VERSION "HNNBNNNYNNNNNNNNNNNNNNNNNNNNNNNNNNNNNNNNNN/4/%%%/4/'%**4NNN///"

NS_ :

BS_:

BU_: BAP_Tester BCM1 Gateway Gateway_PAG Klima_MSB Lift_VA VAS_L VAS_R

BO_ 1624 Licht_vorne_01: 8 BCM1
 SG_ Licht_Vorne_01_CRC : 0|8@1+ (1,0) [0|255] ""  Gateway,Gateway_PAG
 SG_ Licht_Vorne_01_BZ : 8|4@1+ (1,0) [0|15] ""  Gateway,Gateway_PAG
 SG_ LV_Standlicht_Anzeige : 12|1@1+ (1.0,0.0) [0.0|1] ""  Gateway,Gateway_PAG
 SG_ LV_Abblendlicht_Anzeige : 13|1@1+ (1.0,0.0) [0.0|1] ""  Gateway,Gateway_PAG
 SG_ LV_Fernlicht_Anzeige : 14|1@1+ (1.0,0.0) [0.0|1] ""  Gateway,Gateway_PAG
 SG_ LV_Nebellicht_Anzeige : 15|1@1+ (1.0,0.0) [0.0|1] ""  Gateway,Gateway_PAG
 SG_ LV_Nebelschlusslicht_Anzeige : 16|1@1+ (1.0,0.0) [0.0|1] ""  Gateway,Gateway_PAG
 SG_ LV_Tagfahrlicht_Anzeige : 17|1@1+ (1.0,0.0) [0.0|1] ""  Gateway,Gateway_PAG
 SG_ LV_AFL_aktiv_Anzeige : 18|1@1+ (1.0,0.0) [0.0|1] ""  Gateway,Gateway_PAG
 SG_ LV_AFL_defekt : 19|1@1+ (1.0,0.0) [0.0|1] ""  Gateway,Gateway_PAG
 SG_ LV_Blinker_li_def : 20|1@1+ (1.0,0.0) [0.0|1] ""  Gateway,Gateway_PAG,VAS_L,VAS_R
 SG_ LV_Standlicht_li_def : 21|1@1+ (1.0,0.0) [0.0|1] ""  Gateway,Gateway_PAG
 SG_ LV_Abblendlicht_li_def : 22|1@1+ (1.0,0.0) [0.0|1] ""  Gateway,Gateway_PAG,VAS_L,VAS_R
 SG_ LV_Fernlicht_li_def : 23|1@1+ (1.0,0.0) [0.0|1] ""  Gateway,Gateway_PAG,VAS_L,VAS_R
 SG_ LV_Nebellicht_li_def : 24|1@1+ (1.0,0.0) [0.0|1] ""  Gateway,Gateway_PAG,VAS_L,VAS_R
 SG_ LV_Blk_li_Seite_def : 25|1@1+ (1.0,0.0) [0.0|1] ""  Gateway,Gateway_PAG,VAS_L,VAS_R
 SG_ LV_Tagfahrlicht_li_def : 26|1@1+ (1.0,0.0) [0.0|1] ""  Gateway,Gateway_PAG
 SG_ LV_FLA_aktiv_Anzeige : 27|1@1+ (1.0,0.0) [0.0|1] ""  Gateway,Gateway_PAG
 SG_ LV_FLA_defekt : 28|1@1+ (1.0,0.0) [0.0|1] ""  Gateway,Gateway_PAG
 SG_ LV_FLA_Sensor_blockiert : 29|1@1+ (1.0,0.0) [0.0|1] ""  Gateway,Gateway_PAG
 SG_ LV_Blinker_re_def : 30|1@1+ (1.0,0.0) [0.0|1] ""  Gateway,Gateway_PAG,VAS_L,VAS_R
 SG_ LV_Standlicht_re_def : 31|1@1+ (1.0,0.0) [0.0|1] ""  Gateway,Gateway_PAG
 SG_ LV_Abblendlicht_re_def : 32|1@1+ (1.0,0.0) [0.0|1] ""  Gateway,Gateway_PAG,VAS_L,VAS_R
 SG_ LV_Fernlicht_re_def : 33|1@1+ (1.0,0.0) [0.0|1] ""  Gateway,Gateway_PAG,VAS_L,VAS_R
 SG_ LV_Nebellicht_re_def : 34|1@1+ (1.0,0.0) [0.0|1] ""  Gateway,Gateway_PAG,VAS_L,VAS_R
 SG_ LV_Blk_re_Seite_def : 35|1@1+ (1.0,0.0) [0.0|1] ""  Gateway,Gateway_PAG,VAS_L,VAS_R
 SG_ LV_Tagfahrlicht_re_def : 36|1@1+ (1.0,0.0) [0.0|1] ""  Gateway,Gateway_PAG
 SG_ LV_Aussenlicht_def : 37|1@1+ (1.0,0.0) [0.0|1] ""  Gateway,Gateway_PAG,VAS_L,VAS_R
 SG_ LV_Abblendlicht_TFL_li_def : 38|1@1+ (1.0,0.0) [0.0|1] ""  Gateway,Gateway_PAG,VAS_L,VAS_R
 SG_ LV_Nebellicht_TFL_li_def : 39|1@1+ (1.0,0.0) [0.0|1] ""  Gateway,Gateway_PAG,VAS_L,VAS_R
 SG_ LV_Standlicht_TFL_li_def : 40|1@1+ (1.0,0.0) [0.0|1] ""  Gateway,Gateway_PAG
 SG_ LV_Abblend_Fernlicht_li_def : 41|1@1+ (1.0,0.0) [0.0|1] ""  Gateway,Gateway_PAG,VAS_L,VAS_R
 SG_ LV_Abblendlicht_TFL_re_def : 42|1@1+ (1.0,0.0) [0.0|1] ""  Gateway,Gateway_PAG,VAS_L,VAS_R
 SG_ LV_Nebellicht_TFL_re_def : 43|1@1+ (1.0,0.0) [0.0|1] ""  Gateway,Gateway_PAG,VAS_L,VAS_R
 SG_ LV_Standlicht_TFL_re_def : 44|1@1+ (1.0,0.0) [0.0|1] ""  Gateway,Gateway_PAG
 SG_ LV_Abblend_Fernlicht_re_def : 45|1@1+ (1.0,0.0) [0.0|1] ""  Gateway,Gateway_PAG,VAS_L,VAS_R
 SG_ LV_Abbiegelicht_li_def : 46|1@1+ (1.0,0.0) [0.0|1] ""  Gateway,Gateway_PAG
 SG_ LV_Abbiegelicht_re_def : 47|1@1+ (1.0,0.0) [0.0|1] ""  Gateway,Gateway_PAG
 SG_ BCM1_Linksverkehr : 48|1@1+ (1.0,0.0) [0.0|1] ""  Gateway,Gateway_PAG
 SG_ BCM1_Licht_Dunkelheit_aktiv : 49|1@1+ (1.0,0.0) [0.0|1] ""  Gateway,Gateway_PAG
 SG_ LV_LED_Scheinwerfer_li_def : 50|1@1+ (1.0,0.0) [0.0|1] ""  Gateway,Gateway_PAG
 SG_ LV_LED_Scheinwerfer_re_def : 51|1@1+ (1.0,0.0) [0.0|1] ""  Gateway,Gateway_PAG
 SG_ LV_Blinker_VL_aktiv : 52|1@1+ (1.0,0.0) [0.0|1] ""  Gateway,Gateway_PAG,VAS_L,VAS_R
 SG_ LV_Blinker_VR_aktiv : 53|1@1+ (1.0,0.0) [0.0|1] ""  Gateway,Gateway_PAG,VAS_L,VAS_R
 SG_ LV_MXB_Status_Anzeige : 54|2@1+ (1.0,0.0) [0.0|3] ""  Gateway,Gateway_PAG

BO_ 1321 Lift_01: 8 Lift_VA
 SG_ Lift_Charisma_FahrPr : 15|3@1+ (1.0,0.0) [0.0|7] ""  Gateway,Gateway_PAG
 SG_ Lift_Charisma_Status : 18|2@1+ (1.0,0.0) [0.0|3] ""  Gateway,Gateway_PAG
 SG_ Lift_Charisma_Umschaltung : 20|2@1+ (1.0,0.0) [0.0|3] ""  Gateway,Gateway_PAG
 SG_ Lift_Anforderung_EFP : 22|2@1+ (1.0,0.0) [0.0|3] ""  Gateway,Gateway_PAG
 SG_ Lift_ESP_Zuschaltung : 24|1@1+ (1.0,0.0) [0.0|1] ""  Gateway,Gateway_PAG
 SG_ Lift_Meldung_12 : 40|1@1+ (1.0,0.0) [0.0|1] ""  Gateway,Gateway_PAG
 SG_ Lift_Meldung_13 : 41|1@1+ (1.0,0.0) [0.0|1] ""  Gateway,Gateway_PAG
 SG_ Lift_Meldung_14 : 42|1@1+ (1.0,0.0) [0.0|1] ""  Gateway,Gateway_PAG
 SG_ Lift_LED : 43|2@1+ (1.0,0.0) [0.0|3] ""  Gateway,Gateway_PAG
 SG_ Lift_Position : 45|3@1+ (1.0,0.0) [0.0|7] ""  Gateway,Gateway_PAG
 SG_ Lift_Meldung_01 : 48|1@1+ (1.0,0.0) [0.0|1] ""  Gateway,Gateway_PAG
 SG_ Lift_Meldung_02 : 49|1@1+ (1.0,0.0) [0.0|1] ""  Gateway,Gateway_PAG
 SG_ Lift_Meldung_03 : 50|1@1+ (1.0,0.0) [0.0|1] ""  Gateway,Gateway_PAG
 SG_ Lift_Meldung_04 : 51|1@1+ (1.0,0.0) [0.0|1] ""  Gateway,Gateway_PAG
 SG_ Lift_Meldung_05 : 52|1@1+ (1.0,0.0) [0.0|1] ""  Gateway,Gateway_PAG
 SG_ Lift_Meldung_06 : 53|1@1+ (1.0,0.0) [0.0|1] ""  Gateway,Gateway_PAG
 SG_ Lift_Meldung_07 : 54|1@1+ (1.0,0.0) [0.0|1] ""  Gateway,Gateway_PAG
 SG_ Lift_Meldung_08 : 55|1@1+ (1.0,0.0) [0.0|1] ""  Gateway,Gateway_PAG
 SG_ Lift_Meldung_09 : 56|1@1+ (1.0,0.0) [0.0|1] ""  Gateway,Gateway_PAG
 SG_ Lift_Meldung_10 : 57|1@1+ (1.0,0.0) [0.0|1] ""  Gateway,Gateway_PAG
 SG_ Lift_Meldung_11 : 58|1@1+ (1.0,0.0) [0.0|1] ""  Gateway,Gateway_PAG
 SG_ Lift_SpannungsAnf : 59|2@1+ (1.0,0.0) [0.0|3] ""  Gateway,Gateway_PAG
 SG_ Lift_StartStopp_Info : 61|2@1+ (1.0,0.0) [0.0|3] ""  Gateway,Gateway_PAG

BO_ 822 LR_HZG_01: 2 Gateway
 SG_ LR_HZG_Temp_Sensor : 0|8@1+ (1,-50) [-50|104] "Unit_DegreCelsi"  Klima_MSB
 SG_ LR_HZG_Taster_on_off : 8|1@1+ (1.0,0.0) [0.0|1] ""  BCM1,Klima_MSB

BO_ 2527679652 LS1_01: 8 Gateway
 SG_ LS1_Reinigung_Anf : 63|1@1+ (1.0,0.0) [0.0|1] ""  BCM1

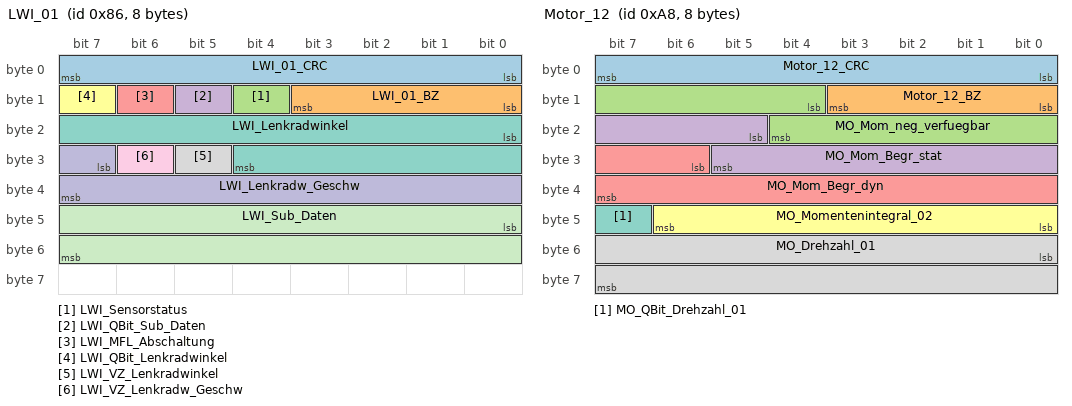
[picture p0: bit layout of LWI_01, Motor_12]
BO_ 134 LWI_01: 8 Gateway
 SG_ LWI_01_CRC : 0|8@1+ (1,0) [0|255] ""  Vector__XXX
 SG_ LWI_01_BZ : 8|4@1+ (1,0) [0|15] ""  Vector__XXX
 SG_ LWI_Sensorstatus : 12|1@1+ (1.0,0.0) [0.0|1] ""  Vector__XXX
 SG_ LWI_QBit_Sub_Daten : 13|1@1+ (1.0,0.0) [0.0|1] ""  Vector__XXX
 SG_ LWI_MFL_Abschaltung : 14|1@1+ (1.0,0.0) [0.0|1] ""  Vector__XXX
 SG_ LWI_QBit_Lenkradwinkel : 15|1@1+ (1.0,0.0) [0.0|1] ""  Vector__XXX
 SG_ LWI_Lenkradwinkel : 16|13@1+ (0.1,0) [0.0|800.0] "Unit_DegreOfArc"  Lift_VA
 SG_ LWI_VZ_Lenkradwinkel : 29|1@1+ (1.0,0.0) [0.0|1] ""  Lift_VA
 SG_ LWI_VZ_Lenkradw_Geschw : 30|1@1+ (1.0,0.0) [0.0|1] ""  Vector__XXX
 SG_ LWI_Lenkradw_Geschw : 31|9@1+ (5,0) [0|2500] "Unit_DegreOfArcPerSecon"  Vector__XXX
 SG_ LWI_Sub_Daten : 40|16@1+ (1,0) [0|65535] ""  Vector__XXX

BO_ 917 LWR_AFS_01: 8 BCM1
 SG_ AFS_Abbiegelicht_li_Anf : 0|1@1+ (1.0,0.0) [0.0|1] ""  Gateway,Gateway_PAG
 SG_ AFS_Abbiegelicht_re_Anf : 1|1@1+ (1.0,0.0) [0.0|1] ""  Gateway,Gateway_PAG
 SG_ AFS_Abbiegelicht_Dimm_Anf : 2|1@1+ (1.0,0.0) [0.0|1] ""  Gateway,Gateway_PAG
 SG_ AFS_Verfuegbarkeit_GLW : 3|1@1+ (1.0,0.0) [0.0|1] ""  Gateway,Gateway_PAG
 SG_ AFS_Status_adaptive_LV : 4|1@1+ (1.0,0.0) [0.0|1] ""  Gateway,Gateway_PAG
 SG_ AFS_Fernlicht_li_defekt : 5|1@1+ (1.0,0.0) [0.0|1] ""  Gateway,Gateway_PAG
 SG_ AFS_Fernlicht_re_defekt : 6|1@1+ (1.0,0.0) [0.0|1] ""  Gateway,Gateway_PAG
 SG_ AFS_Fernlicht_Status : 7|1@1+ (1.0,0.0) [0.0|1] ""  Gateway,Gateway_PAG
 SG_ LWR_AFS_01_BZ : 8|4@1+ (1,0) [0|15] ""  Gateway,Gateway_PAG
 SG_ AFS_Lampe : 12|1@1+ (1.0,0.0) [0.0|1] ""  Gateway,Gateway_PAG
 SG_ LWR_Lampe : 13|1@1+ (1.0,0.0) [0.0|1] ""  Gateway,Gateway_PAG
 SG_ AFS_Fehlertext : 14|1@1+ (1.0,0.0) [0.0|1] ""  Gateway,Gateway_PAG
 SG_ AFS_LED_Blinkmode : 15|1@1+ (1.0,0.0) [0.0|1] ""  Gateway,Gateway_PAG
 SG_ LWR_Touristenmodus_aktiv : 16|1@1+ (1.0,0.0) [0.0|1] ""  Gateway,Gateway_PAG
 SG_ AFS_Charisma_FahrPr : 17|4@1+ (1.0,0.0) [0.0|15] ""  Gateway,Gateway_PAG
 SG_ AFS_Charisma_Status : 21|2@1+ (1.0,0.0) [0.0|3] ""  Gateway,Gateway_PAG
 SG_ LWR_Sicherheitsposition_re : 23|1@1+ (1.0,0.0) [0.0|1] ""  Gateway,Gateway_PAG
 SG_ AFS_Allwetterlicht : 24|1@1+ (1.0,0.0) [0.0|1] ""  Gateway,Gateway_PAG
 SG_ LWR_Touristenmodus_verbaut : 25|1@1+ (1.0,0.0) [0.0|1] ""  Gateway,Gateway_PAG
 SG_ AFS_adaptive_LV_verbaut : 26|1@1+ (1.0,0.0) [0.0|1] ""  Gateway,Gateway_PAG
 SG_ LWR_Reisemodus_Texte : 27|2@1+ (1.0,0.0) [0.0|3] ""  Gateway,Gateway_PAG
 SG_ GLW_Sensor_blockiert : 29|1@1+ (1.0,0.0) [0.0|1] ""  Gateway,Gateway_PAG
 SG_ AFS_Charisma_Umschaltung : 30|2@1+ (1.0,0.0) [0.0|3] ""  Gateway,Gateway_PAG
 SG_ LWR_Pos_Schrittmotor : 32|8@1+ (0.4,0) [0.0|100.0] "Unit_PerCent"  Gateway,Gateway_PAG
 SG_ LWR_Hoehenwert_VL : 40|8@1+ (1,-127) [-127|126] ""  Gateway,Gateway_PAG
 SG_ LWR_Hoehenwert_HL : 48|8@1+ (1,-127) [-127|126] ""  Gateway,Gateway_PAG
 SG_ AFS_Ersatzlicht_Links : 56|1@1+ (1.0,0.0) [0.0|1] ""  Gateway,Gateway_PAG
 SG_ AFS_Ersatzlicht_Rechts : 57|1@1+ (1.0,0.0) [0.0|1] ""  Gateway,Gateway_PAG
 SG_ LWR_AFS_Grundeinstellung : 58|1@1+ (1.0,0.0) [0.0|1] ""  Gateway,Gateway_PAG
 SG_ LWR_AFS_Parametrisierung : 59|1@1+ (1.0,0.0) [0.0|1] ""  Gateway,Gateway_PAG
 SG_ LWR_Initialisierungslauf : 60|1@1+ (1.0,0.0) [0.0|1] ""  Gateway,Gateway_PAG
 SG_ LWR_Sicherheitsposition_li : 61|1@1+ (1.0,0.0) [0.0|1] ""  Gateway,Gateway_PAG
 SG_ LWR_Modus : 62|1@1+ (1.0,0.0) [0.0|1] ""  Gateway,Gateway_PAG

BO_ 1153 MainUnit_01: 8 Gateway
 SG_ ZR_LoGeWa_Event_Kombiwarnung : 0|4@1+ (1.0,0.0) [0.0|15] ""  Vector__XXX
 SG_ Nav_FoD_Status : 4|3@1+ (1.0,0.0) [0.0|7] ""  Vector__XXX
 SG_ MIB_Tongenerator_PH_verfuegbar : 9|3@1+ (1.0,0.0) [0.0|7] ""  BCM1
 SG_ MMI_Counter_Bedienevent : 12|4@1+ (1.0,0.0) [0.0|15] ""  Vector__XXX
 SG_ DSSS_Warning : 16|5@1+ (1.0,0.0) [0.0|31] ""  Vector__XXX
 SG_ ZR_Kindersicherung_RSE : 21|1@1+ (1.0,0.0) [0.0|1] ""  Vector__XXX
 SG_ ZR_RSE_aktivieren : 22|1@1+ (1.0,0.0) [0.0|1] ""  Vector__XXX
 SG_ MMI_SDS_aktiv : 23|1@1+ (1.0,0.0) [0.0|1] ""  Vector__XXX
 SG_ MU_SecondDisplay : 24|3@1+ (1.0,0.0) [0.0|7] ""  Vector__XXX
 SG_ MMI_Telefon_aktiv : 27|1@1+ (1.0,0.0) [0.0|1] ""  Vector__XXX
 SG_ MMI_Gurt_Mic_ref : 28|1@1+ (1.0,0.0) [0.0|1] ""  Vector__XXX
 SG_ ZR_Sta_Inszenierung : 29|2@1+ (1.0,0.0) [0.0|3] ""  BCM1
 SG_ MMI_Gauges_active : 31|1@1+ (1.0,0.0) [0.0|1] ""  Vector__XXX
 SG_ MU_Update_Time : 32|8@1+ (0.1,0) [0.0|25.5] "Unit_Hours"  Vector__XXX
 SG_ ZR_MXB_Manoever_Ansage : 42|2@1+ (1.0,0.0) [0.0|3] ""  Vector__XXX
 SG_ ZR_LAPP_Sondermodus_Status : 44|2@1+ (1.0,0.0) [0.0|3] ""  Vector__XXX
 SG_ MMI_StartStopp_Info : 46|2@1+ (1.0,0.0) [0.0|3] ""  Vector__XXX
 SG_ ZR_Parken_Sondermodus : 48|4@1+ (1.0,0.0) [0.0|15] ""  Vector__XXX
 SG_ ZR_Rundenbewertung : 52|4@1+ (1.0,0.0) [0.0|15] ""  Vector__XXX
 SG_ ZR_Rundenfortschritt : 56|8@1+ (0.5,0) [0.0|100.0] "Unit_PerCent"  Vector__XXX

BO_ 1639 Mem_BFS_01: 8 Gateway
 SG_ BFS_Fond_Bed_Ack : 12|1@1+ (1.0,0.0) [0.0|1] ""  Vector__XXX
 SG_ BFS_Lehne_nicht_verriegelt : 13|1@1+ (1.0,0.0) [0.0|1] ""  Vector__XXX
 SG_ BFS_Klapptisch_offen : 14|1@1+ (1.0,0.0) [0.0|1] ""  Vector__XXX
 SG_ BFS_Gurtbringer_Sperre : 15|1@1+ (1.0,0.0) [0.0|1] ""  Vector__XXX
 SG_ BFS_Sitzsym_Fahrt_aktiv : 16|1@1+ (1.0,0.0) [0.0|1] ""  Vector__XXX
 SG_ BFS_Sitzfahrt_aktiv : 17|1@1+ (1.0,0.0) [0.0|1] ""  Vector__XXX
 SG_ BFS_SLV_aktiv : 18|1@1+ (1.0,0.0) [0.0|1] ""  Vector__XXX
 SG_ BFS_SHV_aktiv : 19|1@1+ (1.0,0.0) [0.0|1] ""  Vector__XXX
 SG_ BFS_LNV_aktiv : 20|1@1+ (1.0,0.0) [0.0|1] ""  Vector__XXX
 SG_ BFS_SNV_aktiv : 21|1@1+ (1.0,0.0) [0.0|1] ""  Vector__XXX
 SG_ BFS_KSV_aktiv : 22|1@1+ (1.0,0.0) [0.0|1] ""  Vector__XXX
 SG_ BFS_LKV_aktiv : 23|1@1+ (1.0,0.0) [0.0|1] ""  Vector__XXX
 SG_ BFS_STV_aktiv : 24|1@1+ (1.0,0.0) [0.0|1] ""  Vector__XXX
 SG_ BFS_LHV_aktiv : 25|1@1+ (1.0,0.0) [0.0|1] ""  Vector__XXX
 SG_ BFS_LWV_aktiv : 26|1@1+ (1.0,0.0) [0.0|1] ""  Vector__XXX
 SG_ BFS_GHV_aktiv : 27|1@1+ (1.0,0.0) [0.0|1] ""  Vector__XXX
 SG_ BFS_KSS_Fahrt_aktiv : 28|1@1+ (1.0,0.0) [0.0|1] ""  Vector__XXX
 SG_ BFS_MMB_lokal_Stop : 29|1@1+ (1.0,0.0) [0.0|1] ""  Vector__XXX
 SG_ BFS_Ruhestellung_Status : 30|1@1+ (1.0,0.0) [0.0|1] ""  Vector__XXX
 SG_ BFS_Seat_Locked : 31|1@1+ (1.0,0.0) [0.0|1] ""  Vector__XXX
 SG_ BFS_MMB_storage : 32|4@1+ (1.0,0.0) [0.0|15] ""  BCM1
 SG_ BFS_MMB_tipp : 36|1@1+ (1.0,0.0) [0.0|1] ""  BCM1
 SG_ BFS_MMB_tast : 37|1@1+ (1.0,0.0) [0.0|1] ""  BCM1
 SG_ BFS_MMB_store_LED_on : 38|1@1+ (1.0,0.0) [0.0|1] ""  Vector__XXX
 SG_ BFS_MMB_storage_beep : 39|1@1+ (1.0,0.0) [0.0|1] ""  Vector__XXX
 SG_ BFS_MMB_store : 40|1@1+ (1.0,0.0) [0.0|1] ""  Vector__XXX
 SG_ BFS_MMB_glob_stop : 41|1@1+ (1.0,0.0) [0.0|1] ""  BCM1
 SG_ BFS_FSV_ausgeklappt : 42|1@1+ (1.0,0.0) [0.0|1] ""  BCM1
 SG_ BFS_NFA_einfahren : 43|1@1+ (1.0,0.0) [0.0|1] ""  Vector__XXX
 SG_ BFS_Kollisionsbereich_Windschott : 44|1@1+ (1.0,0.0) [0.0|1] ""  Vector__XXX
 SG_ BFS_Kollisionsgefahr_Windschott : 45|1@1+ (1.0,0.0) [0.0|1] ""  Vector__XXX

BO_ 1178 Mem_FS_01: 8 Gateway
 SG_ FS_Fond_Bed_enable : 12|1@1+ (1.0,0.0) [0.0|1] ""  Vector__XXX
 SG_ FS_Lehne_nicht_verriegelt : 13|1@1+ (1.0,0.0) [0.0|1] ""  Vector__XXX
 SG_ FS_Spezialposition_anfahren : 14|1@1+ (1.0,0.0) [0.0|1] ""  Vector__XXX
 SG_ FS_Gurtbringer_Sperre : 15|1@1+ (1.0,0.0) [0.0|1] ""  Vector__XXX
 SG_ FS_BFS_Sitzsym_Anfahrt : 16|1@1+ (1.0,0.0) [0.0|1] ""  Vector__XXX
 SG_ FS_Sitzfahrt_aktiv : 17|1@1+ (1.0,0.0) [0.0|1] ""  BCM1
 SG_ FS_SLV_aktiv : 18|1@1+ (1.0,0.0) [0.0|1] ""  Vector__XXX
 SG_ FS_SHV_aktiv : 19|1@1+ (1.0,0.0) [0.0|1] ""  Vector__XXX
 SG_ FS_LNV_aktiv : 20|1@1+ (1.0,0.0) [0.0|1] ""  Vector__XXX
 SG_ FS_SNV_aktiv : 21|1@1+ (1.0,0.0) [0.0|1] ""  Vector__XXX
 SG_ FS_KSV_aktiv : 22|1@1+ (1.0,0.0) [0.0|1] ""  Vector__XXX
 SG_ FS_LKV_aktiv : 23|1@1+ (1.0,0.0) [0.0|1] ""  Vector__XXX
 SG_ FS_STV_aktiv : 24|1@1+ (1.0,0.0) [0.0|1] ""  Vector__XXX
 SG_ FS_LHV_aktiv : 25|1@1+ (1.0,0.0) [0.0|1] ""  Vector__XXX
 SG_ FS_LWV_aktiv : 26|1@1+ (1.0,0.0) [0.0|1] ""  Vector__XXX
 SG_ FS_GHV_aktiv : 27|1@1+ (1.0,0.0) [0.0|1] ""  Vector__XXX
 SG_ FS_BFS_KSS_Anfahrt : 28|1@1+ (1.0,0.0) [0.0|1] ""  Vector__XXX
 SG_ FS_MMB_lokal_Stop : 29|1@1+ (1.0,0.0) [0.0|1] ""  Vector__XXX
 SG_ FS_NFA_einfahren : 30|1@1+ (1.0,0.0) [0.0|1] ""  Vector__XXX
 SG_ FS_Kollisionsbereich_Windschott : 31|1@1+ (1.0,0.0) [0.0|1] ""  Vector__XXX
 SG_ FS_MMB_storage : 32|4@1+ (1.0,0.0) [0.0|15] ""  BCM1,Klima_MSB
 SG_ FS_MMB_tipp : 36|1@1+ (1.0,0.0) [0.0|1] ""  BCM1,Klima_MSB
 SG_ FS_MMB_tast : 37|1@1+ (1.0,0.0) [0.0|1] ""  BCM1,Klima_MSB
 SG_ FS_MMB_store_LED_on : 38|1@1+ (1.0,0.0) [0.0|1] ""  Vector__XXX
 SG_ FS_MMB_storage_beep : 39|1@1+ (1.0,0.0) [0.0|1] ""  Vector__XXX
 SG_ FS_MMB_store : 40|1@1+ (1.0,0.0) [0.0|1] ""  BCM1,Klima_MSB
 SG_ FS_MMB_glob_stop : 41|1@1+ (1.0,0.0) [0.0|1] ""  BCM1
 SG_ FS_EE_Fond_FS_enable : 42|1@1+ (1.0,0.0) [0.0|1] ""  Vector__XXX
 SG_ FS_EE_Fond_BFS_enable : 43|1@1+ (1.0,0.0) [0.0|1] ""  Vector__XXX
 SG_ FS_BFS_Fond_Verst_enable : 44|1@1+ (1.0,0.0) [0.0|1] ""  Vector__XXX
 SG_ FS_EE_BFS_enable : 45|1@1+ (1.0,0.0) [0.0|1] ""  Vector__XXX
 SG_ FS_Kollisionsgefahr_Windschott : 46|1@1+ (1.0,0.0) [0.0|1] ""  Vector__XXX

BO_ 1171 MFG_01: 8 Gateway
 SG_ MFG_01_CRC : 0|8@1+ (1,0) [0|255] ""  BCM1
 SG_ MFG_01_BZ : 8|4@1+ (1,0) [0|15] ""  BCM1
 SG_ MF_ZV_Lock : 12|1@1+ (1.0,0.0) [0.0|1] ""  Vector__XXX
 SG_ MF_Motorweiterlauf : 13|1@1+ (1.0,0.0) [0.0|1] ""  Vector__XXX
 SG_ MF_Heckrollo : 14|1@1+ (1.0,0.0) [0.0|1] ""  Vector__XXX
 SG_ MF_Anlassersperre : 15|1@1+ (1.0,0.0) [0.0|1] ""  Vector__XXX
 SG_ MF_Variante : 16|3@1+ (1.0,0.0) [0.0|7] ""  BCM1
 SG_ MF_Sperre_Rollo : 19|1@1+ (1.0,0.0) [0.0|1] ""  Vector__XXX
 SG_ MF_Laderelais : 20|1@1+ (1.0,0.0) [0.0|1] ""  Vector__XXX
 SG_ MF_StartStopp_Info : 21|2@1+ (1.0,0.0) [0.0|3] ""  Vector__XXX
 SG_ MF_Fernbed_ein : 23|1@1+ (1.0,0.0) [0.0|1] ""  BCM1
 SG_ MF_Standlicht : 24|1@1+ (1.0,0.0) [0.0|1] ""  BCM1
 SG_ MF_Fahrlicht : 25|1@1+ (1.0,0.0) [0.0|1] ""  BCM1
 SG_ MF_interm_Fernlicht : 26|1@1+ (1.0,0.0) [0.0|1] ""  BCM1
 SG_ MF_Warnblinker : 27|1@1+ (1.0,0.0) [0.0|1] ""  BCM1
 SG_ MF_Fussraumbel : 28|1@1+ (1.0,0.0) [0.0|1] ""  BCM1
 SG_ MF_Innenraumbel : 29|1@1+ (1.0,0.0) [0.0|1] ""  BCM1
 SG_ MF_Innenraumbel_Unterdrueck : 30|1@1+ (1.0,0.0) [0.0|1] ""  BCM1
 SG_ MF_Notstart : 31|1@1+ (1.0,0.0) [0.0|1] ""  Vector__XXX
 SG_ MF_Blk_li : 32|1@1+ (1.0,0.0) [0.0|1] ""  Vector__XXX
 SG_ MF_Blk_re : 33|1@1+ (1.0,0.0) [0.0|1] ""  Vector__XXX
 SG_ MF_Lichthupe : 34|1@1+ (1.0,0.0) [0.0|1] ""  BCM1
 SG_ MF_Fernlicht : 35|1@1+ (1.0,0.0) [0.0|1] ""  BCM1
 SG_ MF_HFS_verriegeln : 36|1@1+ (1.0,0.0) [0.0|1] ""  Vector__XXX
 SG_ MF_HFS_entriegeln : 37|1@1+ (1.0,0.0) [0.0|1] ""  Vector__XXX
 SG_ MF_HBFS_verriegeln : 38|1@1+ (1.0,0.0) [0.0|1] ""  Vector__XXX
 SG_ MF_HBFS_entriegeln : 39|1@1+ (1.0,0.0) [0.0|1] ""  Vector__XXX
 SG_ MF_Tippwischen : 40|1@1+ (1.0,0.0) [0.0|1] ""  BCM1
 SG_ MF_Frontintervall : 41|1@1+ (1.0,0.0) [0.0|1] ""  BCM1
 SG_ MF_Wischerstufe_1 : 42|1@1+ (1.0,0.0) [0.0|1] ""  BCM1
 SG_ MF_Wischerstufe_2 : 43|1@1+ (1.0,0.0) [0.0|1] ""  BCM1
 SG_ MF_Frontwaschen : 44|1@1+ (1.0,0.0) [0.0|1] ""  BCM1
 SG_ MF_nachtr_Stopp_Anf : 45|1@1+ (1.0,0.0) [0.0|1] ""  Vector__XXX
 SG_ MF_Heckintervall : 46|1@1+ (1.0,0.0) [0.0|1] ""  BCM1
 SG_ MF_Heckwaschen : 47|1@1+ (1.0,0.0) [0.0|1] ""  BCM1
 SG_ MF_Summer : 48|1@1+ (1.0,0.0) [0.0|1] ""  Vector__XXX
 SG_ MF_Alarm_Blinkertakt : 49|1@1+ (1.0,0.0) [0.0|1] ""  Vector__XXX
 SG_ MF_Alarm_Blinker : 50|1@1+ (1.0,0.0) [0.0|1] ""  Vector__XXX
 SG_ MF_TFL_Abschaltung : 51|1@1+ (1.0,0.0) [0.0|1] ""  BCM1
 SG_ MF_interm_Takt : 52|1@1+ (1.0,0.0) [0.0|1] ""  Vector__XXX
 SG_ MF_Tuerentriegelung_hinten : 53|1@1+ (1.0,0.0) [0.0|1] ""  Vector__XXX
 SG_ MF_interm_Fahrlicht : 54|1@1+ (1.0,0.0) [0.0|1] ""  Vector__XXX
 SG_ MF_Signalhorn : 55|1@1+ (1.0,0.0) [0.0|1] ""  BCM1
 SG_ MF_FH_FT_hoch : 56|1@1+ (1.0,0.0) [0.0|1] ""  Vector__XXX
 SG_ MF_FH_FT_tief : 57|1@1+ (1.0,0.0) [0.0|1] ""  Vector__XXX
 SG_ MF_FH_BT_hoch : 58|1@1+ (1.0,0.0) [0.0|1] ""  Vector__XXX
 SG_ MF_FH_BT_tief : 59|1@1+ (1.0,0.0) [0.0|1] ""  Vector__XXX
 SG_ MF_FT_verriegeln : 60|1@1+ (1.0,0.0) [0.0|1] ""  Vector__XXX
 SG_ MF_FT_entriegeln : 61|1@1+ (1.0,0.0) [0.0|1] ""  Vector__XXX
 SG_ MF_BT_verriegeln : 62|1@1+ (1.0,0.0) [0.0|1] ""  Vector__XXX
 SG_ MF_BT_entriegeln : 63|1@1+ (1.0,0.0) [0.0|1] ""  Vector__XXX

BO_ 817 MFL_01: 8 Gateway
 SG_ MFL_Zaehler : 0|4@1+ (1,0) [0|15] ""  Vector__XXX
 SG_ MFL_Toggle : 4|1@1+ (1,0) [0|1] ""  Vector__XXX
 SG_ MFL_Lokalaktiv : 5|1@1+ (1.0,0.0) [0.0|1] ""  Vector__XXX
 SG_ MFL_M_Taste : 6|1@1+ (1.0,0.0) [0.0|1] ""  Vector__XXX
 SG_ MFL_Paddle_Verbau : 7|1@1+ (1.0,0.0) [0.0|1] ""  Vector__XXX
 SG_ MFL_Tastencode_1 : 8|8@1+ (1.0,0.0) [0.0|255] ""  BCM1
 SG_ MFL_Tastencode_2 : 16|8@1+ (1.0,0.0) [0.0|255] ""  BCM1
 SG_ MFL_Eventcode_1 : 24|4@1+ (1.0,0.0) [0.0|15] ""  Vector__XXX
 SG_ MFL_Eventcode_2 : 28|4@1+ (1.0,0.0) [0.0|15] ""  Vector__XXX
 SG_ MFL_Marke : 32|4@1+ (1.0,0.0) [0.0|15] ""  Vector__XXX
 SG_ MFL_Variante : 36|4@1+ (1,0) [0|15] ""  Vector__XXX
 SG_ MFL_Dummy_0_Signal_1 : 40|8@1+ (1.0,0.0) [0.0|255] ""  Vector__XXX
 SG_ MFL_Tip_Down : 48|1@1+ (1.0,0.0) [0.0|1] ""  Vector__XXX
 SG_ MFL_Tip_Up : 49|1@1+ (1.0,0.0) [0.0|1] ""  Vector__XXX
 SG_ MFL_SatModul_links_Err : 50|1@1+ (1.0,0.0) [0.0|1] ""  Vector__XXX
 SG_ MFL_SatModul_rechts_Err : 51|1@1+ (1.0,0.0) [0.0|1] ""  Vector__XXX
 SG_ MFL_Dummy_0_Signal_2 : 52|1@1+ (1.0,0.0) [0.0|1] ""  Vector__XXX
 SG_ MFL_Dummy_0_Signal_3 : 53|1@1+ (1.0,0.0) [0.0|1] ""  Vector__XXX
 SG_ MFL_LR_HZG_Status : 54|1@1+ (1.0,0.0) [0.0|1] ""  Vector__XXX
 SG_ MFL_LR_HZG_Err : 55|1@1+ (1.0,0.0) [0.0|1] ""  Vector__XXX
 SG_ MFL_Signalhorn : 56|1@1+ (1.0,0.0) [0.0|1] ""  BCM1
 SG_ MFL_Signalhorn_Err : 57|1@1+ (1.0,0.0) [0.0|1] ""  Vector__XXX
 SG_ MFL_Tip_links_Err : 58|1@1+ (1.0,0.0) [0.0|1] ""  Vector__XXX
 SG_ MFL_Tip_rechts_Err : 59|1@1+ (1.0,0.0) [0.0|1] ""  Vector__XXX
 SG_ MFL_Taste_links_Err : 60|1@1+ (1.0,0.0) [0.0|1] ""  Vector__XXX
 SG_ MFL_Taste_rechts_Err : 61|1@1+ (1.0,0.0) [0.0|1] ""  Vector__XXX
 SG_ MFL_ECU_Err : 62|1@1+ (1.0,0.0) [0.0|1] ""  Vector__XXX
 SG_ MFL_Response_Err : 63|1@1+ (1.0,0.0) [0.0|1] ""  Vector__XXX

BO_ 1600 Motor_07: 8 Gateway
 SG_ MO_QBit_Ansaugluft_Temp : 0|1@1+ (1.0,0.0) [0.0|1] ""  Vector__XXX
 SG_ MO_QBit_Oel_Temp : 1|1@1+ (1.0,0.0) [0.0|1] ""  Vector__XXX
 SG_ MO_QBit_Kuehlmittel_Temp : 2|1@1+ (1.0,0.0) [0.0|1] ""  Vector__XXX
 SG_ MO_KL15_Abschaltempfehlung : 3|1@1+ (1.0,0.0) [0.0|1] ""  Vector__XXX
 SG_ MO_HYB_Fehler_HV_Netz : 4|1@1+ (1.0,0.0) [0.0|1] ""  Vector__XXX
 SG_ MO_aktives_Getriebeheizen : 5|1@1+ (1.0,0.0) [0.0|1] ""  Vector__XXX
 SG_ MO_Absperrventil_oeffnen : 6|2@1+ (1.0,0.0) [0.0|3] ""  BCM1,Klima_MSB
 SG_ MO_Ansaugluft_Temp : 8|8@1+ (0.75,-48) [-48.00|141.75] "Unit_DegreCelsi"  Vector__XXX
 SG_ MO_Oel_Temp : 16|8@1+ (1,-60) [-60|192] "Unit_DegreCelsi"  BCM1,Klima_MSB
 SG_ MO_Kuehlmittel_Temp : 24|8@1+ (0.75,-48) [-48.00|141.75] "Unit_DegreCelsi"  BCM1,Klima_MSB
 SG_ MO_Hoeheninfo : 32|8@1+ (0.00781,0) [0.00000|1.98374] ""  BCM1,Klima_MSB
 SG_ MO_Kennfeldk : 40|1@1+ (1.0,0.0) [0.0|1] ""  BCM1,Klima_MSB
 SG_ MO_Versionsinfo_02 : 41|5@1+ (1.0,0.0) [0.0|31] ""  Vector__XXX
 SG_ MO_QBit_Hoeheninfo : 46|1@1+ (1.0,0.0) [0.0|1] ""  Vector__XXX
 SG_ MO_Getriebe_kuehlen : 47|1@1+ (1.0,0.0) [0.0|1] ""  Vector__XXX
 SG_ MO_Mom_Traegheit_02 : 48|5@1+ (0.01,0) [0.00|0.31] "Unit_KiloGramMeterSquar"  Vector__XXX
 SG_ MO_Heizungspumpenansteuerung : 53|4@1+ (10,0) [0|100] "Unit_PerCent"  BCM1,Klima_MSB
 SG_ MO_SpannungsAnf : 57|1@1+ (1.0,0.0) [0.0|1] ""  Vector__XXX
 SG_ MO_Nachlaufzeit_Heizungspumpe : 58|6@1+ (15,0) [0|945] "Unit_Secon"  BCM1

BO_ 1607 Motor_09: 8 Gateway
 SG_ MO_ITM_Kuehlmittel_Temp : 0|8@1+ (0.75,-48) [-45.75|143.25] "Unit_DegreCelsi"  BCM1,Klima_MSB
 SG_ MO_E85_Sensor : 8|4@1+ (10,0) [0|100] "Unit_PerCent"  Vector__XXX
 SG_ SCR_Anz_Motorstarts : 12|4@1+ (1.0,0.0) [0.0|15] ""  Vector__XXX
 SG_ SCR_Reichweite : 16|15@1+ (1,0) [0|32766] "Unit_KiloMeter"  Vector__XXX
 SG_ MO_Ethanol_Spuelhinweis : 31|1@1+ (1.0,0.0) [0.0|1] ""  Vector__XXX
 SG_ SCR_Warnstufe_1 : 32|1@1+ (1.0,0.0) [0.0|1] ""  Vector__XXX
 SG_ SCR_Warnstufe_2 : 33|1@1+ (1.0,0.0) [0.0|1] ""  Vector__XXX
 SG_ SCR_Text : 34|3@1+ (1.0,0.0) [0.0|7] ""  Vector__XXX
 SG_ SCR_Akustik : 37|2@1+ (1.0,0.0) [0.0|3] ""  Vector__XXX
 SG_ SCR_verbaut : 39|1@1+ (1.0,0.0) [0.0|1] ""  Vector__XXX
 SG_ MO_Kraftstofffilter_Wasser : 40|1@1+ (1.0,0.0) [0.0|1] ""  Vector__XXX
 SG_ SCR_Systemfehler : 41|1@1+ (1.0,0.0) [0.0|1] ""  Vector__XXX
 SG_ SCR_Inducement_Strategie : 42|2@1+ (1.0,0.0) [0.0|3] ""  Vector__XXX
 SG_ MO_CO2_Faktor : 44|12@1+ (1,0) [1|4094] "Unit_GramPerLiter"  Vector__XXX
 SG_ MO_MKB_MUX M  : 56|2@1+ (1.0,0.0) [0.0|3] ""  Vector__XXX
 SG_ MO_MKB_01 m0  : 59|5@1+ (1.0,0.0) [0.0|31] ""  Vector__XXX
 SG_ MO_MKB_02 m1  : 59|5@1+ (1.0,0.0) [0.0|31] ""  Vector__XXX
 SG_ MO_MKB_03 m2  : 59|5@1+ (1.0,0.0) [0.0|31] ""  Vector__XXX
 SG_ MO_MKB_04 m3  : 59|5@1+ (1.0,0.0) [0.0|31] ""  Vector__XXX

BO_ 168 Motor_12: 8 Gateway
 SG_ Motor_12_CRC : 0|8@1+ (1,0) [0|255] ""  Vector__XXX
 SG_ Motor_12_BZ : 8|4@1+ (1,0) [0|15] ""  Vector__XXX
 SG_ MO_Mom_neg_verfuegbar : 12|9@1+ (1,-509) [-509|0] ""  Vector__XXX
 SG_ MO_Mom_Begr_stat : 21|9@1+ (1,0) [0|509] ""  Vector__XXX
 SG_ MO_Mom_Begr_dyn : 30|10@1+ (1,-509) [-509|509] ""  Vector__XXX
 SG_ MO_Momentenintegral_02 : 40|7@1+ (1,0) [0|100] "Unit_PerCent"  Vector__XXX
 SG_ MO_QBit_Drehzahl_01 : 47|1@1+ (1.0,0.0) [0.0|1] ""  BCM1,Klima_MSB
 SG_ MO_Drehzahl_01 : 48|16@1+ (0.25,0) [0.00|16383.00] "Unit_MinutInver"  BCM1,Klima_MSB,Lift_VA

BO_ 958 Motor_14: 8 Gateway
 SG_ Motor_14_CRC : 0|8@1+ (1,0) [0|255] ""  Vector__XXX
 SG_ Motor_14_BZ : 8|4@1+ (1,0) [0|15] ""  Vector__XXX
 SG_ MO_StartStopp_Status : 12|2@1+ (1.0,0.0) [0.0|3] ""  BCM1,Klima_MSB,Lift_VA
 SG_ MO_StartStopp_Wiederstart : 14|1@1+ (1.0,0.0) [0.0|1] ""  BCM1,Klima_MSB,Lift_VA
 SG_ MO_StartStopp_Motorstopp : 15|1@1+ (1.0,0.0) [0.0|1] ""  BCM1,Klima_MSB,Lift_VA
 SG_ MO_Freig_Reku : 16|2@1+ (1.0,0.0) [0.0|3] ""  Vector__XXX
 SG_ MO_Kl_75 : 18|1@1+ (1.0,0.0) [0.0|1] ""  BCM1,Klima_MSB,VAS_L,VAS_R
 SG_ MO_Kl_50 : 19|1@1+ (1.0,0.0) [0.0|1] ""  Lift_VA
 SG_ MO_Gangposition : 20|4@1+ (1.0,0.0) [0.0|15] ""  BCM1,Klima_MSB,VAS_L,VAS_R
 SG_ MO_StartStopp_Fahrerwunsch : 24|2@1+ (1.0,0.0) [0.0|3] ""  BCM1,Klima_MSB,Lift_VA
 SG_ MO_HYB_Fahrbereitschaft : 26|1@1+ (1.0,0.0) [0.0|1] ""  BCM1,Klima_MSB
 SG_ MO_Ext_E_Fahrt_aktiv : 27|1@1+ (1.0,0.0) [0.0|1] ""  BCM1,Klima_MSB
 SG_ MO_Fahrer_bremst : 28|1@1+ (1.0,0.0) [0.0|1] ""  BCM1
 SG_ MO_QBit_Fahrer_bremst : 29|1@1+ (1.0,0.0) [0.0|1] ""  BCM1
 SG_ MO_BLS : 30|1@1+ (1.0,0.0) [0.0|1] ""  BCM1
 SG_ MO_Konsistenz_Bremsped : 31|1@1+ (1.0,0.0) [0.0|1] ""  Vector__XXX
 SG_ MO_KomFehler_ESP : 32|1@1+ (1.0,0.0) [0.0|1] ""  Vector__XXX
 SG_ MO_Klima_Eingr : 33|2@1+ (1.0,0.0) [0.0|3] ""  BCM1,Klima_MSB
 SG_ MO_Aussp_Anlass : 35|1@1+ (1.0,0.0) [0.0|1] ""  Vector__XXX
 SG_ MO_Freig_Anlass : 36|1@1+ (1.0,0.0) [0.0|1] ""  Vector__XXX
 SG_ MO_Kuppl_schalter : 37|1@1+ (1.0,0.0) [0.0|1] ""  BCM1
 SG_ MO_Interlock : 38|1@1+ (1.0,0.0) [0.0|1] ""  BCM1
 SG_ MO_Motor_laeuft : 39|1@1+ (1.0,0.0) [0.0|1] ""  BCM1,Klima_MSB,Lift_VA
 SG_ MO_Kickdown : 40|1@1+ (1.0,0.0) [0.0|1] ""  BCM1,Klima_MSB
 SG_ MO_QBit_KL_75 : 41|1@1+ (1.0,0.0) [0.0|1] ""  BCM1
 SG_ MO_EKlKomLeiRed : 42|2@1+ (1.0,0.0) [0.0|3] ""  Vector__XXX
 SG_ MO_Handshake_STH : 44|1@1+ (1.0,0.0) [0.0|1] ""  Vector__XXX
 SG_ MO_BKV_Unterdruckwarnung : 45|1@1+ (1.0,0.0) [0.0|1] ""  Vector__XXX
 SG_ MO_Freigabe_Segeln : 46|1@1+ (1.0,0.0) [0.0|1] ""  Vector__XXX
 SG_ MO_PTC_Status : 47|3@1+ (1.0,0.0) [0.0|7] ""  Vector__XXX
 SG_ MO_QBit_Gangposition : 50|1@1+ (1.0,0.0) [0.0|1] ""  Vector__XXX
 SG_ MO_Signalquelle_Gangposition : 51|1@1+ (1.0,0.0) [0.0|1] ""  Vector__XXX
 SG_ MO_Remotestart_Betrieb : 52|1@1+ (1.0,0.0) [0.0|1] ""  Vector__XXX
 SG_ MO_Remotestart_moeglich : 53|1@1+ (1.0,0.0) [0.0|1] ""  Vector__XXX
 SG_ MO_Text_Geschw_red : 54|1@1+ (1.0,0.0) [0.0|1] ""  Vector__XXX
 SG_ MO_FMAus_aktiv : 55|1@1+ (1.0,0.0) [0.0|1] ""  BCM1,Klima_MSB
 SG_ MO_FMAus_Startvariante : 56|2@1+ (1.0,0.0) [0.0|3] ""  Vector__XXX
 SG_ MO_BMS_NV_Anf_stuetzen : 58|1@1+ (1.0,0.0) [0.0|1] ""  Vector__XXX
 SG_ MO_Zylinderabschaltung : 59|2@1+ (1.0,0.0) [0.0|3] ""  Vector__XXX
 SG_ MO_HYB_VM_aktiv : 61|1@1+ (1.0,0.0) [0.0|1] ""  BCM1,Klima_MSB
 SG_ MO_StartVorauss_erfuellt : 62|2@1+ (1.0,0.0) [0.0|3] ""  Vector__XXX

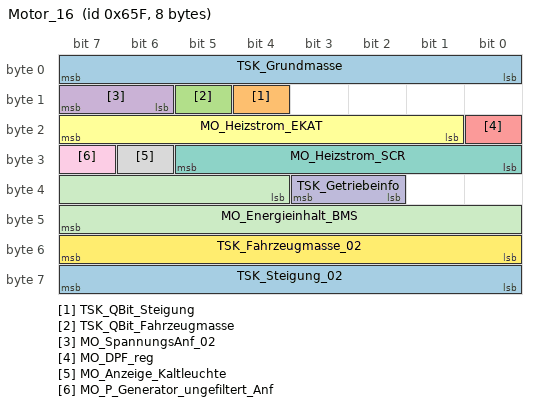
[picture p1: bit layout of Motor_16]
BO_ 1631 Motor_16: 8 Gateway
 SG_ TSK_Grundmasse : 0|8@1+ (32,0) [0|8128] "Unit_KiloGram"  Vector__XXX
 SG_ TSK_QBit_Steigung : 12|1@1+ (1.0,0.0) [0.0|1] ""  BCM1
 SG_ TSK_QBit_Fahrzeugmasse : 13|1@1+ (1.0,0.0) [0.0|1] ""  Vector__XXX
 SG_ MO_SpannungsAnf_02 : 14|2@1+ (1.0,0.0) [0.0|3] ""  Vector__XXX
 SG_ MO_DPF_reg : 16|1@1+ (1.0,0.0) [0.0|1] ""  Vector__XXX
 SG_ MO_Heizstrom_EKAT : 17|7@1+ (1,0) [0|126] "Unit_Amper"  Vector__XXX
 SG_ MO_Heizstrom_SCR : 24|6@1+ (1,0) [0|62] "Unit_Amper"  Vector__XXX
 SG_ MO_Anzeige_Kaltleuchte : 30|1@1+ (1.0,0.0) [0.0|1] ""  Vector__XXX
 SG_ MO_P_Generator_ungefiltert_Anf : 31|1@1+ (1.0,0.0) [0.0|1] ""  Vector__XXX
 SG_ TSK_Getriebeinfo : 34|2@1+ (1.0,0.0) [0.0|3] ""  Vector__XXX
 SG_ MO_Energieinhalt_BMS : 36|12@1+ (25,0) [0|102325] "Unit_WattHour"  Vector__XXX
 SG_ TSK_Fahrzeugmasse_02 : 48|8@1+ (32,0) [0|8128] "Unit_KiloGram"  Vector__XXX
 SG_ TSK_Steigung_02 : 56|8@1+ (0.8,-101.6) [-100.8|101.6] "Unit_PerCent"  BCM1

BO_ 812 Motor_17: 8 Gateway
 SG_ MO_Sperrung_FahrPr_BZS : 0|8@1+ (1.0,0.0) [0.0|255] ""  Vector__XXX
 SG_ MO_Rampenzeit_Generator_Anf : 8|4@1+ (1.0,0.0) [0.0|15] ""  Vector__XXX
 SG_ MO_Prio_MAX_Wunschdrehzahl : 12|1@1+ (1.0,0.0) [0.0|1] ""  Vector__XXX
 SG_ MO_Prio_MIN_Wunschdrehzahl : 13|1@1+ (1.0,0.0) [0.0|1] ""  Vector__XXX
 SG_ MO_Luftpfad_aktiv : 14|1@1+ (1.0,0.0) [0.0|1] ""  Vector__XXX
 SG_ MO_v_Begrenz_Aktivierbar : 15|1@1+ (1.0,0.0) [0.0|1] ""  Vector__XXX
 SG_ MO_Drehzahlbeeinflussung : 16|8@1+ (0.39,0) [0.00|99.45] "Unit_PerCent"  Vector__XXX
 SG_ MO_MIN_Wunschdrehzahl : 24|8@1+ (25,0) [0|6350] "Unit_MinutInver"  Vector__XXX
 SG_ MO_MAX_Wunschdrehzahl : 32|9@1+ (25,0) [0|12750] "Unit_MinutInver"  Vector__XXX
 SG_ MO_Charisma_FahrPr : 41|4@1+ (1.0,0.0) [0.0|15] ""  Vector__XXX
 SG_ MO_Charisma_Status : 45|2@1+ (1.0,0.0) [0.0|3] ""  Vector__XXX
 SG_ MO_StSt_Charisma_FahrPr : 47|4@1+ (1.0,0.0) [0.0|15] ""  Vector__XXX
 SG_ MO_StSt_Charisma_Status : 51|2@1+ (1.0,0.0) [0.0|3] ""  Vector__XXX
 SG_ MO_BZS_Charisma_FahrPr : 53|4@1+ (1.0,0.0) [0.0|15] ""  BCM1
 SG_ MO_BZS_Charisma_Status : 57|2@1+ (1.0,0.0) [0.0|3] ""  Vector__XXX
 SG_ MO_NGS_Position : 59|1@1+ (1.0,0.0) [0.0|1] ""  Vector__XXX
 SG_ MO_NGS_Status : 60|2@1+ (1.0,0.0) [0.0|3] ""  Vector__XXX
 SG_ MO_v_Begrenzung_Niveau : 62|2@1+ (1.0,0.0) [0.0|3] ""  Vector__XXX

BO_TX_BU_ 822 :Gateway,Gateway_PAG;
BO_TX_BU_ 2527679652 :Gateway,Gateway_PAG;
BO_TX_BU_ 134 :Gateway,Gateway_PAG;
BO_TX_BU_ 1153 :Gateway,Gateway_PAG;
BO_TX_BU_ 1639 :Gateway,Gateway_PAG;
BO_TX_BU_ 1178 :Gateway,Gateway_PAG;
BO_TX_BU_ 1171 :Gateway,Gateway_PAG;
BO_TX_BU_ 817 :Gateway,Gateway_PAG;
BO_TX_BU_ 1600 :Gateway,Gateway_PAG;
BO_TX_BU_ 1607 :Gateway,Gateway_PAG;
BO_TX_BU_ 168 :Gateway,Gateway_PAG;
BO_TX_BU_ 958 :Gateway,Gateway_PAG;
BO_TX_BU_ 1631 :Gateway,Gateway_PAG;
BO_TX_BU_ 812 :Gateway,Gateway_PAG;
CM_ BO_ 134 "ab MQB mit CRC in Byte 1";
CM_ BO_ 917 "MLB";
CM_ BO_ 1639 "MLBevo";
CM_ BO_ 1178 "ab MQB 7.2";
CM_ BO_ 1171 "ab MQB 7.2 gültig";
CM_ BO_ 1600 "ab MQB mit QBit Höheneinfo und MO_Versionsinfo_02";
CM_ BO_ 168 "Teil 2 neue Momentenschnittstelle MLB";

CM_ SG_ 1624 BCM1_Licht_Dunkelheit_aktiv "Licht aktiv aufgrund von Dunkelheit (nicht bei Autobahn-, Tagfahr- oder Regenlicht)";
CM_ SG_ 1624 BCM1_Linksverkehr "Information über Aufbauzustand des Fzg:
0 = Scheinwerfer für Rechtsverkehr
1 = Scheinwerfer für Linksverkehr";
CM_ SG_ 1624 Licht_Vorne_01_CRC "Für MLB:
'Berechnung siehe Lastenheft 'Kommunikationsabsicherung für FlexRay und CAN''

Ab MQB und MLBevo:
'Berechnung siehe Lastenheft 'End-to-End Kommunikationsabsicherung''

Endwerte siehe Begleitdokument 'S-PDU Kennungsfolgen'";
CM_ SG_ 1624 LV_Abbiegelicht_li_def "Fehlerstatus Abbiegelicht vorne links
";
CM_ SG_ 1624 LV_Abbiegelicht_re_def "Fehlerstatus Abbiegelicht vorne rechts
";
CM_ SG_ 1624 LV_Abblend_Fernlicht_li_def "Fehlerstatus Abblendlicht und Fernlicht links ";
CM_ SG_ 1624 LV_Abblend_Fernlicht_re_def "Fehlerstatus Abblendlicht und Fernlicht rechts";
CM_ SG_ 1624 LV_Abblendlicht_Anzeige "Abblendlicht aktiv";
CM_ SG_ 1624 LV_Abblendlicht_li_def "Fehlerstatus Abblendlicht vorne links 
";
CM_ SG_ 1624 LV_Abblendlicht_re_def "Fehlerstatus Abblendlicht vorne rechts
";
CM_ SG_ 1624 LV_Abblendlicht_TFL_li_def "Fehlerstatus Abblendlicht und Tagfahrlicht links
";
CM_ SG_ 1624 LV_Abblendlicht_TFL_re_def "Fehlerstatus Abblendlicht und Tagfahrlicht rechts ";
CM_ SG_ 1624 LV_AFL_aktiv_Anzeige "Anzeige AFL-Funktion";
CM_ SG_ 1624 LV_AFL_defekt "Fehlerstatus AFL
";
CM_ SG_ 1624 LV_Aussenlicht_def "Aussenlicht kann nicht mehr korrekt angesteuert werden (EEPROM Codierung kann nicht mehr ausgelesen werden)
";
CM_ SG_ 1624 LV_Blinker_li_def "Fehlerstatus Blinker vorne links
";
CM_ SG_ 1624 LV_Blinker_re_def "Fehlerstatus Blinker vorne rechts
";
CM_ SG_ 1624 LV_Blinker_VL_aktiv "Blinker vorne links
";
CM_ SG_ 1624 LV_Blinker_VR_aktiv "Blinker vorne links
";
CM_ SG_ 1624 LV_Blk_li_Seite_def "Fehlerstatus Seitenblinker links
";
CM_ SG_ 1624 LV_Blk_re_Seite_def "Fehlerstatus Blinker Seite rechts
";
CM_ SG_ 1624 LV_Fernlicht_Anzeige "Fernlicht_aktiv";
CM_ SG_ 1624 LV_Fernlicht_li_def "Fehlerstatus Fernlicht vorne links
";
CM_ SG_ 1624 LV_Fernlicht_re_def "Fehlerstatus Fernlicht vorne rechts
";
CM_ SG_ 1624 LV_FLA_aktiv_Anzeige "Ansteuerung FLA-Lampe im Kombi (BCM1 Bedienmaster)";
CM_ SG_ 1624 LV_FLA_defekt "Fehlerstatus FLA (Anzeige des entsprechenden Fehlertext im Kombi)";
CM_ SG_ 1624 LV_FLA_Sensor_blockiert "Status FLA-Sensor (Anzeige des entsprechenden Fehlertext im Kombi)";
CM_ SG_ 1624 LV_LED_Scheinwerfer_li_def "Fehlerstatus LED-Scheinwerfer links
";
CM_ SG_ 1624 LV_LED_Scheinwerfer_re_def "Fehlerstatus LED-Scheinwerfer rechts";
CM_ SG_ 1624 LV_MXB_Status_Anzeige "Aktueller Status des Fernlichts / MxB zur Signalisierung im Kombi.";
CM_ SG_ 1624 LV_Nebellicht_Anzeige "Nebellicht_aktiv
";
CM_ SG_ 1624 LV_Nebellicht_li_def "Fehlerstatus Nebelscheinwerfer vorne links
";
CM_ SG_ 1624 LV_Nebellicht_re_def "Fehlerstatus Nebelscheinwerfer vorne rechts
";
CM_ SG_ 1624 LV_Nebellicht_TFL_li_def "Fehlerstatus Nebellicht und Tagfahrlicht links ";
CM_ SG_ 1624 LV_Nebellicht_TFL_re_def "Fehlerstatus Nebellicht und Tagfahrlicht rechts";
CM_ SG_ 1624 LV_Nebelschlusslicht_Anzeige "Nebelschlusslicht_aktiv
";
CM_ SG_ 1624 LV_Standlicht_Anzeige "Anzeige Standlicht
";
CM_ SG_ 1624 LV_Standlicht_li_def "Fehlerstatus Standlicht vorne links
";
CM_ SG_ 1624 LV_Standlicht_re_def "Fehlerstatus Standlicht vorne rechts
";
CM_ SG_ 1624 LV_Standlicht_TFL_li_def "Fehlerstatus Standlicht und Tagfahrlicht links ";
CM_ SG_ 1624 LV_Standlicht_TFL_re_def "Fehlerstatus Standlicht und Tagfahrlicht rechts ";
CM_ SG_ 1624 LV_Tagfahrlicht_Anzeige "Anzeige Tagfahrlicht
";
CM_ SG_ 1624 LV_Tagfahrlicht_li_def "Fehlerstatus Tagfahrlicht links
";
CM_ SG_ 1624 LV_Tagfahrlicht_re_def "Fehlerstatus Tagfahrlicht rechts";

CM_ SG_ 1321 Lift_Anforderung_EFP "Lift Funktionsanforderungen";
CM_ SG_ 1321 Lift_Charisma_FahrPr "


";
CM_ SG_ 1321 Lift_Charisma_Status "Systemstatus des Charismateilnehmers

";
CM_ SG_ 1321 Lift_Charisma_Umschaltung "Erkennung Umschaltaufforderung des Charisma-Teilnehmers";
CM_ SG_ 1321 Lift_ESP_Zuschaltung "Zwangsweise Aktivierung der ESP-Funktionalität wird angefordert.";
CM_ SG_ 1321 Lift_LED "Status der Liftanzeige";
CM_ SG_ 1321 Lift_Meldung_01 "Meldung 1 für das Kombi ";
CM_ SG_ 1321 Lift_Meldung_02 "Meldung 2 für das Kombi ";
CM_ SG_ 1321 Lift_Meldung_03 "Meldung 3 für das Kombi ";
CM_ SG_ 1321 Lift_Meldung_04 "Meldung 4 für das Kombi ";
CM_ SG_ 1321 Lift_Meldung_05 "Meldung 5 für das Kombi ";
CM_ SG_ 1321 Lift_Meldung_06 "Meldung 6 für das Kombi ";
CM_ SG_ 1321 Lift_Meldung_07 "Meldung 7 für das Kombi ";
CM_ SG_ 1321 Lift_Meldung_08 "Meldung 8 für das Kombi ";
CM_ SG_ 1321 Lift_Meldung_09 "Meldung 9 für das Kombi ";
CM_ SG_ 1321 Lift_Meldung_10 "Meldung 10 für das Kombi";
CM_ SG_ 1321 Lift_Meldung_11 "Meldung 11 für das Kombi";
CM_ SG_ 1321 Lift_Meldung_12 "Meldung 12 für das Kombi";
CM_ SG_ 1321 Lift_Meldung_13 "Meldung 13 für das Kombi";
CM_ SG_ 1321 Lift_Meldung_14 "Meldung 14 für das Kombi";
CM_ SG_ 1321 Lift_Position "Aktuelle Position der Liftfunktion";
CM_ SG_ 1321 Lift_SpannungsAnf "Anforderung des Lift zur Spannungsanhebung des Bordnetzes.";
CM_ SG_ 1321 Lift_StartStopp_Info "Stopp-Freigabe und Start-Anforderung an den Start-Stopp-Koordinator";

CM_ SG_ 822 LR_HZG_Taster_on_off "Anforderung des Schalters am MFL: Lenkradheizung aus/ein
(Regelung der LR_HZG ist im SMLS)";
CM_ SG_ 822 LR_HZG_Temp_Sensor "Temperaturwert Lenkradheizung";

CM_ SG_ 2527679652 LS1_Reinigung_Anf "Anforderung zur Ansteuerung der Reinigungspumpe für den Laserscanner.";

CM_ SG_ 134 LWI_01_BZ "Botschaft asynchron geroutet. Zählerwert kann springen.";
CM_ SG_ 134 LWI_01_CRC "Für MLB:
'Berechnung siehe Lastenheft 'Kommunikationsabsicherung für FlexRay und CAN''

Ab MQB und MLBevo:
'Berechnung siehe Lastenheft 'End-to-End Kommunikationsabsicherung'

Endwerte siehe Begleitdokument 'S-PDU Kennungsfolgen'";
CM_ SG_ 134 LWI_Lenkradw_Geschw "Wertebereich = +/- 2500 Grad/s
Auflösung = 5 Grad/s

Hinweis: Zusätzlich gestellte Winkel bei Dynamiklenkung beachten !";
CM_ SG_ 134 LWI_Lenkradwinkel "Wertebereich = +/- 800 Grad
Auflösung = 0,1 Grad
ACHTUNG: spezifizierte Interne Auflösung des Sensors beträgt aber nur Schrittweite 0,5 Grad!

Hinweis:
MLB: Zusätzlich gestellte Winkel bei Dynamiklenkung beachten !
MQB: Nicht konstante Lenkübersetzu";
CM_ SG_ 134 LWI_MFL_Abschaltung "Signal zur Anforderung der MFL Abschaltung bei Erkennung einer dynamischen Lenkbewegung.";
CM_ SG_ 134 LWI_QBit_Lenkradwinkel "Das QBit wird auch bei nicht abgeglichenem Lenkradwinkelsensor gesetzt";
CM_ SG_ 134 LWI_QBit_Sub_Daten "Es gilt die Signalspezifikation laut LAH";
CM_ SG_ 134 LWI_Sub_Daten "Verschlüsseltes Datenpaket vom Sub-Rechner des LWS, Verwendung nur durch SCU und ESP_ADS
Verwendung gemäß 'Sicherheitsanforderungen an Empfängersteuergeräte'

Im MLB gilt die Signalspezifikation: LAH 8K0953B
Im MLBevo gilt die Signalspezifikation LAH.";
CM_ SG_ 134 LWI_VZ_Lenkradw_Geschw "Vorzeichen Lenkradwinkelgeschwindigkeit gemäss DIN70000; 
Nullstellung = +0";
CM_ SG_ 134 LWI_VZ_Lenkradwinkel "Vorzeichen Lenkradwinkel gemäss DIN70000; 
Nullstellung = +0";

CM_ SG_ 917 AFS_Abbiegelicht_Dimm_Anf "Beschreibt ob das Abbiegelicht gedimmt oder hart einschalten werden soll. Dimmkurve ist Empfänger hinterlegt.";
CM_ SG_ 917 AFS_Abbiegelicht_li_Anf "Anforderung das Abbiegelicht links einzuschalten";
CM_ SG_ 917 AFS_Abbiegelicht_re_Anf "Anforderung das Abbiegelicht rechts einzuschalten";
CM_ SG_ 917 AFS_adaptive_LV_verbaut "Verfügbarkeit der adaptiven Lichtverteilung im AFS-SG.
(Das BCM steuert mit diesem Signal die Einblendung des entsprechenden Menüs)";
CM_ SG_ 917 AFS_Allwetterlicht "Status ¿Allwetterlicht¿ - Licht für schlechte Sichtverhältnisse
(bei Defekt -> nicht aktiv)";
CM_ SG_ 917 AFS_Charisma_FahrPr "MLBevo: Aktuelles Fahrprogramm des Charisma-Teilnehmers (siehe Systemlastenheft Drive Select)
MQB: Istwert der Kennlinie (siehe Systemlastenheft MQB FPA)";
CM_ SG_ 917 AFS_Charisma_Status "Charisma Systemstatus des Charisma-Teilnehmers

Wert 0x3 ist nur für Fahrzeuge ab MQB relevant";
CM_ SG_ 917 AFS_Charisma_Umschaltung "Erkennung  Umschaltaufforderung des Charisma-Teilnehmers";
CM_ SG_ 917 AFS_Ersatzlicht_Links "Bei aktivierter Ersatzlichtfunktion wird das Abblendlicht ausgeschaltet und eine Ersatzlichtquelle eingeschaltet (z.Zt. B7)";
CM_ SG_ 917 AFS_Ersatzlicht_Rechts "Bei aktivierter Ersatzlichtfunktion wird das Abblendlicht ausgeschaltet und eine Ersatzlichtquelle eingeschaltet (z.Zt. B7)";
CM_ SG_ 917 AFS_Fehlertext "Fehlertext wird im Kombi angezeigt (z.Zt nur bei VW)";
CM_ SG_ 917 AFS_Fernlicht_li_defekt "Beschreibt ob das Fernlicht des linken Scheinwerfers defekt ist";
CM_ SG_ 917 AFS_Fernlicht_re_defekt "Beschreibt ob das Fernlicht des rechten Scheinwerfers defekt ist";
CM_ SG_ 917 AFS_Fernlicht_Status "Beschreibt ob das Fernlicht aktiv oder inaktiv ist";
CM_ SG_ 917 AFS_Lampe "Status der Fehlerlampe: aktuell anliegender Fehlerzustand des dynamischen oder statischen Kurvenlichtes";
CM_ SG_ 917 AFS_LED_Blinkmode "Lampe soll im Warnfall mit 1Hz blinken, wenn das Bit gesetzt ist (z.Zt nur bei VW)";
CM_ SG_ 917 AFS_Status_adaptive_LV "Gibt den Status der adaptiven Lichtverteilung an";
CM_ SG_ 917 AFS_Verfuegbarkeit_GLW "Beschreibt die Verfügbarkeit der Gleitenden Leuchtweite / Fernlichtassistenz - Verfügbarkeit bedeutet, dass die Funktion Gleitende Leuchtweite möglich ist";
CM_ SG_ 917 GLW_Sensor_blockiert "Das Signal zeigt an, dass die Kamera zur Zeit keine Sicht hat. 
Verhalten wie Fernlichassisten. 
Weiterleitung des Signals vom BCM an das KOMBI";
CM_ SG_ 917 LWR_AFS_Grundeinstellung "Grundeinstellung des Abblendlichtes am Lichteinstellkasten im Service oder Bandende mit Tester erfolgt! (auch für das dynamische Kurvernlicht)";
CM_ SG_ 917 LWR_AFS_Parametrisierung "Parametrisierung wählt die Fahrzeugvariante und die AFS-Variante aus";
CM_ SG_ 917 LWR_Hoehenwert_HL "Aktueller Höhensensorwert Hinten Links
MSS LB überträgt den Aktueller Höhensensorwert Vorne Rechts.

0x7F = 0 mm";
CM_ SG_ 917 LWR_Hoehenwert_VL "Aktueller Höhensensorwert Vorne Links

0x7F = 0 mm";
CM_ SG_ 917 LWR_Initialisierungslauf "Initialisierungslauf der Schrittmotoren, erfolgt defaultmäßig beim Motorstart";
CM_ SG_ 917 LWR_Lampe "Status der Fehlerlampe: aktuell anliegender Fehlerzustand";
CM_ SG_ 917 LWR_Modus "Schnelle oder langsame Regelart der LWR";
CM_ SG_ 917 LWR_Pos_Schrittmotor "Position des Aktuators in Prozent des maximalen Stellweges; vor dem Initialisierungslauf (Motorstart) wird der Initwert ausgegeben: 
0% : tiefste Stellung (auf Block) des Schrittmotors;
100% : maximaler Verstellweg des Schrittmotors (nicht die Grenze de";
CM_ SG_ 917 LWR_Reisemodus_Texte "Anzeige der eingestellten Verkehrsart bei aktivem Touristenlicht";
CM_ SG_ 917 LWR_Sicherheitsposition_li "Rechter Scheinwerfer in Sicherheitsposition.";
CM_ SG_ 917 LWR_Sicherheitsposition_re "Rechter Scheinwerfer in Sicherheitsposition.";
CM_ SG_ 917 LWR_Touristenmodus_aktiv "Über MMI sendet BCM1 eine Anforderung Touristenmodus an die LWR. Diese sendet als Rückmeldung an BCM1, dass der Touristenmodus aktiv geschaltet wurde";
CM_ SG_ 917 LWR_Touristenmodus_verbaut "Verfügbarkeit der Touristenfunktion im AFS/LWR-SG.
(Das BCM steuert mit diesem Signal die Einblendung des entsprechenden Menüs)";

CM_ SG_ 1153 DSSS_Warning "DSSS - Driving Safety Support System Meldungen";
CM_ SG_ 1153 MIB_Tongenerator_PH_verfuegbar "Verfügbarkeit des Tongenerators im MIB für die Nutzung durch die Parkhilfe";
CM_ SG_ 1153 MMI_Counter_Bedienevent "Signal wird inkrementiert, wenn Bedienevent stattgefunden hat.";
CM_ SG_ 1153 MMI_Gauges_active "Signal sent from Main Unit to Kombi instrument to give the display status of the additional gauges in the rotating display";
CM_ SG_ 1153 MMI_Gurt_Mic_ref "Referenzsignal für das Gurtmikrofon Steuergerät zur Signalisierung ob der Downlink aktiv oder inaktiv ist";
CM_ SG_ 1153 MMI_SDS_aktiv "Signal wird gesetzt, solange die Sprachbedienung aktiv ist.";
CM_ SG_ 1153 MMI_StartStopp_Info "Stopp-Freigabe und Start-Anforderung an den Start-Stopp-Koordinator
Signal gilt nur für MHEV12V im MLBevo, Stoppverbot darf nur bei Ausstattungsvariante mit 3D-Sound verwendet werden.";
CM_ SG_ 1153 MU_SecondDisplay "Dient zur Überwachung der zweiten LVDS Leitung.";
CM_ SG_ 1153 MU_Update_Time "Ermöglicht auslesen der Historiendaten, wann ein Update lief";
CM_ SG_ 1153 Nav_FoD_Status "FoD Status der Navigation";
CM_ SG_ 1153 ZR_Kindersicherung_RSE "Sperren der Rearseat Unit (Komplette Weckfähigkeit)";
CM_ SG_ 1153 ZR_LAPP_Sondermodus_Status "Statusrückmeldung zum ZR Sondermodus (BT Abschaltung)";
CM_ SG_ 1153 ZR_LoGeWa_Event_Kombiwarnung "Event für Kombiwarnung";
CM_ SG_ 1153 ZR_MXB_Manoever_Ansage "Übertragung der aktuellen Manöver-Ansage für MatrixBeam. Dient zur Veränderung des Lichtbilds abhängig von Navigationsmanövern.";
CM_ SG_ 1153 ZR_Parken_Sondermodus "Rückkanal zum pilotierten Parken zur Signalisierung Status Sondermodus";
CM_ SG_ 1153 ZR_RSE_aktivieren "Weckfähigkeit der RSE";
CM_ SG_ 1153 ZR_Rundenbewertung "Bewertung einer aktuellen Runde (langsamer, gleich schnell, schneller)";
CM_ SG_ 1153 ZR_Rundenfortschritt "Verhältnis von gefahrener Strecke in einer aktuellen Runde zur Länge einer Referenzrunde in Prozent";
CM_ SG_ 1153 ZR_Sta_Inszenierung "MIB sendet Status über Inszenierungssound (welcome sound) an BCM1
Zweck: Synchronisierung mit weiteren Teilnehmern der Startupinszenierung";

CM_ SG_ 1639 BFS_Fond_Bed_Ack "Bestätigung Beifahrersitzverstellung vom Fond";
CM_ SG_ 1639 BFS_FSV_ausgeklappt "Zustandssignalisierung der el. mech. Fußstütze (eingeklappt oder ausgeklappt)";
CM_ SG_ 1639 BFS_GHV_aktiv "Verstellung Gurthoehe
";
CM_ SG_ 1639 BFS_Gurtbringer_Sperre "Freigabesignal für den Gurtzubringer";
CM_ SG_ 1639 BFS_Klapptisch_offen "Signalisiert eine Verstelleinschränkung des Beifahrersitz  (für BAP Visualisierung)";
CM_ SG_ 1639 BFS_Kollisionsbereich_Windschott "Beifahrersitz steht innerhalb oder außerhalb Windschottbereich. Sitzposition in Kennfeld bedeutet: Windschott kann ohne Kollision ausfahren.";
CM_ SG_ 1639 BFS_Kollisionsgefahr_Windschott "Warnmeldung in Kombi anzeigen, dass manuelle oder automatische Sitzfahrt nicht (mehr) möglich ist, da Kollisionsgefahr zwischen Sitz und Windschott besteht.";
CM_ SG_ 1639 BFS_KSS_Fahrt_aktiv "Komfortseitensichtfahrt (BFS)";
CM_ SG_ 1639 BFS_KSV_aktiv "Kopfstuetzenverstellung BFS
";
CM_ SG_ 1639 BFS_Lehne_nicht_verriegelt "Fahrer Sitz Lehne Verstellung Verriegelt Status

Verwendung nur im  Bentley";
CM_ SG_ 1639 BFS_LHV_aktiv "Verstellung Lordose Höhe
";
CM_ SG_ 1639 BFS_LKV_aktiv "Verstellung Lehnenkopf
";
CM_ SG_ 1639 BFS_LNV_aktiv "Verstellung Lehnenneigung
";
CM_ SG_ 1639 BFS_LWV_aktiv "Lordose W Verstellung
";
CM_ SG_ 1639 BFS_MMB_glob_stop "Abbruch Memoryverstellung";
CM_ SG_ 1639 BFS_MMB_lokal_Stop "mit dem lokal Stop moechte man, dass ein Sitz mit Pneumatik - Lordose sich im Memoryfall wie ein Sitz mit elektromechanischer Lordose verhaelt. Nur lokler Abbruch im TIP-Betrieb.";
CM_ SG_ 1639 BFS_MMB_storage "Speichern auf Memoryposition";
CM_ SG_ 1639 BFS_MMB_storage_beep "Quittierungston Sitzmemory BFS (Anforderung Kombi)

";
CM_ SG_ 1639 BFS_MMB_store "Speichern der Sitzposition
";
CM_ SG_ 1639 BFS_MMB_store_LED_on "LED für Speichern
";
CM_ SG_ 1639 BFS_MMB_tast "Memoryverstellung im Tastbetrieb";
CM_ SG_ 1639 BFS_MMB_tipp "Memoryverstellung im Tippbetrieb";
CM_ SG_ 1639 BFS_NFA_einfahren "Neigungsverstellbare Fussauflage im Fond muss eingefahren werden";
CM_ SG_ 1639 BFS_Ruhestellung_Status "dient der Signalisierung für eine Verstelleinschränkung, da der Sitz sich in Ruhestellung befindet.";
CM_ SG_ 1639 BFS_Seat_Locked "Anzeige des gesperrten Beifahrersitzes aufgrund ungültiger Sitzposition.";
CM_ SG_ 1639 BFS_SHV_aktiv "Sitzhöhenverstellung
";
CM_ SG_ 1639 BFS_Sitzfahrt_aktiv "Aktive Sitzfahrt";
CM_ SG_ 1639 BFS_Sitzsym_Fahrt_aktiv "Sitzsymetriefahrt
";
CM_ SG_ 1639 BFS_SLV_aktiv "Sitzlängsverstellung
";
CM_ SG_ 1639 BFS_SNV_aktiv "Verstellung Sitzneigung
";
CM_ SG_ 1639 BFS_STV_aktiv "Sitztiefeverstellung
";

CM_ SG_ 1178 FS_BFS_Fond_Verst_enable "Verstellung Fond (vom MMI)
";
CM_ SG_ 1178 FS_BFS_KSS_Anfahrt "Komfortseitensicht Anfahrt BFS";
CM_ SG_ 1178 FS_BFS_Sitzsym_Anfahrt "Sitzsymetrie Anfahrt BFS";
CM_ SG_ 1178 FS_EE_BFS_enable "EasyEntry Freigabe für Befahrersitz.";
CM_ SG_ 1178 FS_EE_Fond_BFS_enable "EE Fond rechts

";
CM_ SG_ 1178 FS_EE_Fond_FS_enable "EE Fond links
";
CM_ SG_ 1178 FS_Fond_Bed_enable "Freigabe für Fondsitzverstellungen";
CM_ SG_ 1178 FS_GHV_aktiv "Verstellung Gurthöhe
";
CM_ SG_ 1178 FS_Gurtbringer_Sperre "Freigabesignal für den Gurtzubringer";
CM_ SG_ 1178 FS_Kollisionsbereich_Windschott "Fahrersitz steht innerhalb oder außerhalb Windschottbereich. Sitzposition in Kennfeld bedeutet: Windschott kann ohne Kollision ausfahren.";
CM_ SG_ 1178 FS_Kollisionsgefahr_Windschott "Warnmeldung in Kombi anzeigen, dass manuelle oder automatische Sitzfahrt nicht (mehr) möglich ist, da Kollisionsgefahr zwischen Sitz und Windschott besteht.";
CM_ SG_ 1178 FS_KSV_aktiv "Verstellung Kopfstütze
";
CM_ SG_ 1178 FS_Lehne_nicht_verriegelt "Fahrer Sitz Lehne Verstellung Verriegelt Status

Verwendung nur im Bentley";
CM_ SG_ 1178 FS_LHV_aktiv "Verstellung Lordose Höhe
";
CM_ SG_ 1178 FS_LKV_aktiv "Verstellung Lehnenkopf
";
CM_ SG_ 1178 FS_LNV_aktiv "Verstellung Lehnenneigung
";
CM_ SG_ 1178 FS_LWV_aktiv "Verstellung Lordose W
";
CM_ SG_ 1178 FS_MMB_glob_stop "Abbruch Memoryverstellung";
CM_ SG_ 1178 FS_MMB_lokal_Stop "mit dem lokal Stop moechte man, dass ein Sitz mit Pneumatik - Lordose sich im Memoryfall wie ein Sitz mit elektromechanischer Lordose verhaelt. Nur lokler Abbruch im TIP-Betrieb.";
CM_ SG_ 1178 FS_MMB_storage "Memory-Positionstaste, Funkschlüssel-Memory-ID, Benutzerkonto-Nummer";
CM_ SG_ 1178 FS_MMB_storage_beep "Quittierungston Sitzmemory FS (Anforderung Kombi)";
CM_ SG_ 1178 FS_MMB_store "Memoryposition Speichern";
CM_ SG_ 1178 FS_MMB_store_LED_on "LED für Speichern
";
CM_ SG_ 1178 FS_MMB_tast "Memoryverstellung im Tastbetrieb";
CM_ SG_ 1178 FS_MMB_tipp "Memoryverstellung im Tippbetrieb";
CM_ SG_ 1178 FS_NFA_einfahren "Neigungsverstellbare Fussauflage im Fond muss eingefahren werden";
CM_ SG_ 1178 FS_SHV_aktiv "Verstellung Sitzhöhe

";
CM_ SG_ 1178 FS_Sitzfahrt_aktiv "Aktive Sitzfahrt Fahrersitz
";
CM_ SG_ 1178 FS_SLV_aktiv "Sitzlängsverstellung
";
CM_ SG_ 1178 FS_SNV_aktiv "Verstellung Sitzneigung
";
CM_ SG_ 1178 FS_Spezialposition_anfahren "paralell zu diesem Signal wird eine Botschaft auf den KCAN gesendet in der spezielle Anforderungen für den Empfänger stehen. 
Dieses Signal dient zusätzlich der Checksummenabsicherung bei einer Remotverstellung ";
CM_ SG_ 1178 FS_STV_aktiv "Verstellung Sitztiefe
";

CM_ SG_ 1171 MF_Alarm_Blinker "Taxialarmblinken, wie DWA ohne Fanfare";
CM_ SG_ 1171 MF_Alarm_Blinkertakt "Ansteuerung Blinker bei Alarm. Signal wird getaktet.
0 = Blinker für Alarm aus
1 = Blinker für Alarm ein";
CM_ SG_ 1171 MF_Anlassersperre "Notarzt 230V-Steckdose";
CM_ SG_ 1171 MF_Blk_li "Versehrte oder Fahrschule; Prio über Fernbedienung ein";
CM_ SG_ 1171 MF_Blk_re "Versehrte oder Fahrschule; Prio über Fernbedienung ein";
CM_ SG_ 1171 MF_BT_entriegeln "Beifahrertür entriegeln";
CM_ SG_ 1171 MF_BT_verriegeln "Beifahrertür verriegeln";
CM_ SG_ 1171 MF_Fahrlicht "statisch oder auch mit Blink_modi für interm.  Fahrlicht";
CM_ SG_ 1171 MF_Fernbed_ein "Fernbedienung für Petri+Lehr; Versehrte und Fahrschule";
CM_ SG_ 1171 MF_Fernlicht "Versehrte oder Fahrschule; Oder-Verknüpfung";
CM_ SG_ 1171 MF_FH_BT_hoch "Versehrte";
CM_ SG_ 1171 MF_FH_BT_tief "Versehrte";
CM_ SG_ 1171 MF_FH_FT_hoch "Versehrte";
CM_ SG_ 1171 MF_FH_FT_tief "Versehrte";
CM_ SG_ 1171 MF_Frontintervall "Versehrte oder Fahrschule; Oder-Verknüpfung";
CM_ SG_ 1171 MF_Frontwaschen "Versehrte oder Fahrschule; Oder-Verknüpfung";
CM_ SG_ 1171 MF_FT_entriegeln "Fahrertür entriegeln";
CM_ SG_ 1171 MF_FT_verriegeln "Fahrertür verriegeln";
CM_ SG_ 1171 MF_Fussraumbel "Fussraumbeleuchtung, Fahrschule";
CM_ SG_ 1171 MF_HBFS_entriegeln "Hinten Beifahrertür entriegeln";
CM_ SG_ 1171 MF_HBFS_verriegeln "Hinten Beifahrertür verriegeln";
CM_ SG_ 1171 MF_Heckintervall "Versehrte oder Fahrschule; Oder-Verknüpfung";
CM_ SG_ 1171 MF_Heckrollo "zusätzliche Bedienstelle Heckrollo";
CM_ SG_ 1171 MF_Heckwaschen "Versehrte oder Fahrschule; Oder-Verknüpfung";
CM_ SG_ 1171 MF_HFS_entriegeln "Hinten Fahrertür entriegeln";
CM_ SG_ 1171 MF_HFS_verriegeln "Hinten Fahrertür verriegeln";
CM_ SG_ 1171 MF_Innenraumbel "sämtliche Beleuchtungen akitivieren (Fussraum, Tür u.a.)";
CM_ SG_ 1171 MF_Innenraumbel_Unterdrueck "Unterdrückung des Innenlichts/Fussraumbeleuchtung, sowie Schließblinken";
CM_ SG_ 1171 MF_interm_Fahrlicht "Ansteuerung intermittierendes Abblendlicht";
CM_ SG_ 1171 MF_interm_Fernlicht "mit Blink_modi für SoSi oder Taxialarm";
CM_ SG_ 1171 MF_interm_Takt "Taktung von intermittierenden Fernlicht/Fahrlicht bei einer Einsatzfahrt
0 = Licht aus
1 = Licht ein";
CM_ SG_ 1171 MF_Laderelais "Signal für die Auswertung zur Anzeige der Batterie-Schwach-Anzeige im Kombi";
CM_ SG_ 1171 MF_Lichthupe "Versehrte oder Fahrschule; Oder-Verknuepfung
";
CM_ SG_ 1171 MF_Motorweiterlauf "Motorstop Behoerdenfahrzeug";
CM_ SG_ 1171 MF_nachtr_Stopp_Anf "Dieses Signal dient dem Motor als Trigger, dass ein nachträglicher Motorstopp eingeleitet werden kann, wenn es die Bedingungen des StSt Koordinators dies zulassen.";
CM_ SG_ 1171 MF_Notstart "Signal zeigt an, dass ein Notstart über DBMC erfolgte.

Verwendung in Verbindung mit Signal MF_Variante = DBMC.";
CM_ SG_ 1171 MF_Signalhorn "Versehrte, Fahrschule oder Taxi (bei Alarm)";
CM_ SG_ 1171 MF_Sperre_Rollo "sperrt den Heckrollo";
CM_ SG_ 1171 MF_Standlicht "statisch oder auch mit Blink_modi für Taxialarm";
CM_ SG_ 1171 MF_StartStopp_Info "Stopp-Freigabe und Start-Anforderung an den Start-Stopp-Koordinator";
CM_ SG_ 1171 MF_Summer "Warnsummer für Funkhauptschalter und Fahrschulpedal";
CM_ SG_ 1171 MF_TFL_Abschaltung "Abschaltung des Tagfahrlicht
0 = keine Auswirkung
1 = Tagfahrlicht deaktiviert";
CM_ SG_ 1171 MF_Tippwischen "Versehrte oder Fahrschule; Oder-Verknüpfung";
CM_ SG_ 1171 MF_Tuerentriegelung_hinten "Bei von innen verriegelten Fahrzeug Türen hinten entriegeln
0 = keine Auswirkung
1 = Türen hinten entriegeln
";
CM_ SG_ 1171 MF_Variante "Sonderfahrzeugvariante
0 = keine Sonderfunktion 
1 = Sondersignalfahrzeug
2 = Taxi 
3 = Fahrhilfe 
4 = Fahrschule+Extra 
5 = SSF
6 =  DBMC
7 = Arbeitsmaschine";
CM_ SG_ 1171 MF_Warnblinker "Versehrte";
CM_ SG_ 1171 MF_Wischerstufe_1 "Versehrte oder Fahrschule; Oder-Verknüpfung";
CM_ SG_ 1171 MF_Wischerstufe_2 "Versehrte oder Fahrschule; Oder-Verknüpfung";
CM_ SG_ 1171 MF_ZV_Lock "Verriegelungsanforderung durch MFG analog Meldung einer Locktasterbetätigung durch TSG.";
CM_ SG_ 1171 MFG_01_BZ "4bit Botschaftszähler, wird in jeder Sendebotschaft inkrementiert
";
CM_ SG_ 1171 MFG_01_CRC "Für MLB:
'Berechnung siehe Lastenheft 'Kommunikationsabsicherung für FlexRay und CAN''

Ab MQB und MLBevo:
'Berechnung siehe Lastenheft 'End-to-End Kommunikationsabsicherung''

Endwerte siehe Begleitdokument 'S-PDU Kennungsfolgen'";

CM_ SG_ 817 MFL_ECU_Err "MFL-µC Fehler";
CM_ SG_ 817 MFL_Eventcode_1 "Siehe Q-LAH MFL-Protokoll";
CM_ SG_ 817 MFL_Eventcode_2 "Siehe Q-LAH MFL-Protokoll";
CM_ SG_ 817 MFL_Lokalaktiv "Zeigt an ob das SG nach Klemme15 AUS und nach entsprechender MAX Aktivzeit noch aktiv war";
CM_ SG_ 817 MFL_LR_HZG_Err "Lenkradheizung Fehler";
CM_ SG_ 817 MFL_LR_HZG_Status "Status Lenkradheizung";
CM_ SG_ 817 MFL_M_Taste "Taster für Umschaltung Automatik/manuelles Schalten (Tiptronic)";
CM_ SG_ 817 MFL_Marke "Marke für markenspezifische Variantennummer des MFL";
CM_ SG_ 817 MFL_Paddle_Verbau "Signalisiert den Zustand des Tipp-Paddle-Verbaus";
CM_ SG_ 817 MFL_Response_Err "siehe LIN2.0-Specification
(Darf nicht über ein Fehlergueltigkeitsbit abgesichtert werden!)";
CM_ SG_ 817 MFL_SatModul_links_Err "Schalter Tastermodul links Fehler";
CM_ SG_ 817 MFL_SatModul_rechts_Err "Schalter Tastermodul rechts Fehler";
CM_ SG_ 817 MFL_Signalhorn "Signalhorn nicht betaetigt/betaetigt";
CM_ SG_ 817 MFL_Signalhorn_Err "Signalhorn Fehler";
CM_ SG_ 817 MFL_Taste_links_Err "MFL_Tastenblock links Fehler";
CM_ SG_ 817 MFL_Taste_rechts_Err "MFL_Tastenblock rechts Fehler";
CM_ SG_ 817 MFL_Tastencode_1 "Beschreibt die Funktion einer fest zugeordneten Taste/Walze auf dem MFL. Bei Betätigung ändert sich der Wert von 0x0 auf den jeweiligen Tastencode.";
CM_ SG_ 817 MFL_Tastencode_2 "Beschreibt die Funktion einer fest zugeordneten Taste/Walze auf dem MFL. Ist MFL_Tastencode_1 wegen Betätigung einer Taste/Walze bereits mit einem Wert ungleich 0x0 belegt, so ändert sich bei Betätigung einer weiteren Taste/Walze der Wert dieses Signals v";
CM_ SG_ 817 MFL_Tip_Down "MFL-Tiptronic Tasten vom MFL für Getriebe
    0x0 = kein Tip_Down
    0x1 = Tip_Down";
CM_ SG_ 817 MFL_Tip_links_Err "Tiptronic links Fehler";
CM_ SG_ 817 MFL_Tip_rechts_Err "Tiptronic rechts Fehler";
CM_ SG_ 817 MFL_Tip_Up "MFL-Tiptronic Tasten vom MFL für Getriebe
    0x0 = kein Tip_Up
    0x1 = Tip_Up";
CM_ SG_ 817 MFL_Toggle "Watchdog Toggle-Bit";
CM_ SG_ 817 MFL_Variante "Markenspezifische Variantennummer des MFL";

CM_ SG_ 1600 MO_Absperrventil_oeffnen "Signal an Klima-SG das Absperrrventil anzusteuern. Ab D4 auch 0x3 Ventil_schließen.

Im MQB wird hier der Soll-Status des Absperrventils ausgegeben.
Achtung: bei z. B. klemmendem Ventil entspricht das Signal nicht dem tatsächlichen Status!";
CM_ SG_ 1600 MO_aktives_Getriebeheizen "Information für Getriebe, ob ein Ventil für Getriebheizen angesteuert werden muss";
CM_ SG_ 1600 MO_Ansaugluft_Temp "In Fahrzeugen ohne Außentemperatur vom Kombi kann aus der Ansauglufttemperatur auf die Außentemperatur geschlossen werden. Beim SDI ist das mit einer gewissen Genauigkeit gegeben. Genutzt wird es vom ASG.";
CM_ SG_ 1600 MO_Getriebe_kuehlen "Anforderung Getriebekühlventilansteuerung";
CM_ SG_ 1600 MO_Heizungspumpenansteuerung "Anforderung Heizungspumpenansteuerung
MQB und Hybrid: Status der Heizungsunterstützungspumpe am MSG
";
CM_ SG_ 1600 MO_Hoeheninfo "Korrekturfaktor Höhe (1 entspricht 1013 mbar)";
CM_ SG_ 1600 MO_HYB_Fehler_HV_Netz "Im HV-Bordnetz ist fehlerbedingt kein generatorischer Betrieb möglich. Das 12V-Bordnetz wird über den DC/DC-Wandler allein aus der Traktionsbatterie gespeist. Um diesen Zustand möglichst lange aufrechterhalten zu können, sollten Komfort-Verbraucher abgesc";
CM_ SG_ 1600 MO_Kennfeldk "Die Kennfeldkühlung ist in diesem Fahrzeug verbaut und hat keinen Systemfehler";
CM_ SG_ 1600 MO_KL15_Abschaltempfehlung "Kessy Abschaltempfehlung nach Verlassen des Fahrzeugs";
CM_ SG_ 1600 MO_Kuehlmittel_Temp "Kuehlmitteltemperatur";
CM_ SG_ 1600 MO_Mom_Traegheit_02 "Massenträgheit (J) der Motors bzw. der Antriebsmaschinen in kgm².

Zur Berücksichtigung des E-Motor in Hybrid-Projekten:
in MLB-Projekten wird nur der J-Wert des Verbrennungsmotors und nicht der J-Wert des E-Motors berücksichtigt.
In MQB/MLBevo-Projek";
CM_ SG_ 1600 MO_Nachlaufzeit_Heizungspumpe "Nachlaufzeit für Heizungspumpe für Turboladerschutz";
CM_ SG_ 1600 MO_Oel_Temp "Realer Meßbereich ca. -40..150 Grad";
CM_ SG_ 1600 MO_QBit_Ansaugluft_Temp "
";
CM_ SG_ 1600 MO_QBit_Hoeheninfo "Qualifizierungsbit der Höheninfo. Gesetzt bei Ersatzwert, Init oder Fehler.";
CM_ SG_ 1600 MO_QBit_Kuehlmittel_Temp "
";
CM_ SG_ 1600 MO_SpannungsAnf "Forderung des Motor-SGs zur Spannungsanhebung";
CM_ SG_ 1600 MO_Versionsinfo_02 "Versioninformation vom Motor zur Steuerung bei inkompatiblen KMatrix-Änderung bzw. Einführung von neuen Funktionen, die in den Empfängern verriegelt werden müssen. Zu jedem Ereignis wird ein fixer Zählerstand zugeordnet, um dem Empfänger die funktionale Ä";

CM_ SG_ 1607 MO_CO2_Faktor "dynamischer Umrechnungsfaktor von l in CO2";
CM_ SG_ 1607 MO_E85_Sensor "Information über den E85 Gehalt (%-mass.) im Ottokraftstoff";
CM_ SG_ 1607 MO_Ethanol_Spuelhinweis "Hinweis das der Fahrer beim nächsten Tanken Ethanol armen Sprit tanken soll.";
CM_ SG_ 1607 MO_ITM_Kuehlmittel_Temp "Kuehlmitteltemperatur: Ersatzkühlmitteltemperatur für Motoren mit ITM (Thermomanagement)

ACHTUNG: Ab MQB wird in diesem Signal das Anzeigeplateau durch das MSG dargestellt!";
CM_ SG_ 1607 MO_Kraftstofffilter_Wasser "Für Schlechtkraftstoffländer wird das Wasserabscheidevolumen im Dieselkraftstofffilter mit einem  Wassersensor überwacht. Ist das Volumen erschöpft, erfolgt im Kombi eine entsprechende Anzeige.";
CM_ SG_ 1607 MO_MKB_01 "Motorkennbuchstabe 1";
CM_ SG_ 1607 MO_MKB_02 "Motorkennbuchstabe 2";
CM_ SG_ 1607 MO_MKB_03 "Motorkennbuchstabe 3";
CM_ SG_ 1607 MO_MKB_04 "Motorkennbuchstabe 4";
CM_ SG_ 1607 MO_MKB_MUX "Die vier Motorkennbuchstaben werden gemultiplext in MO_MKB übertragen. Das Signal MO_MKB_MUX stellt das Steuersignal für diesen Multiplexer dar.";
CM_ SG_ 1607 SCR_Akustik "Ansteuerung von Summer/Gong bei Aktivieren der SCR-Warnungen.
Bedienung des Signals nur bei Dieseln mit SCR-System. Andere senden Initwert.";
CM_ SG_ 1607 SCR_Anz_Motorstarts "Anzahl noch möglicher Motorstarts, wenn Reichweite = 0 ist
0..13 = Anzeige 'x mögliche Restarts'
14 = Eingeschränkte Fahrfunktion (z. Zt. Audi)
15 = keine Einschränkung (Anzeige Reichweite)
Bedienung des Signals nur bei Dieseln mit SCR-System.";
CM_ SG_ 1607 SCR_Inducement_Strategie "Art des Motor-Inducement-Konzepts. Abhängig von diesem Signal sind die Warntexte zwischen 'Kein Motorstart (in...km)' und 'eingeschränkte Fahrbarkeit (in ...km)' auszuwählen.";
CM_ SG_ 1607 SCR_Reichweite "Gesamtreichweite in km der aktuellen SCR-Tankfüllung, sofern die Reichweite kleiner 2400 km ist. Bei einer Reichweite größer 2400 km wird grundsätzlich der Initwert (32767) übertragen. Bedienung des Signals nur bei Dieseln mit SCR-System.";
CM_ SG_ 1607 SCR_Systemfehler "Ansteuerung Anzeige für SCR-Systemfehler";
CM_ SG_ 1607 SCR_Text "Warntext (z. B. in Kombination mit SCR Warnstufe und SCR-Systemfehler).
Bedienung des Signals nur bei Dieseln mit SCR-System. Andere senden Initwert.";
CM_ SG_ 1607 SCR_verbaut "Die SCR-Signale deren Initwert ungleich 0 sind, werden nur dann ausgewertet, wenn SCR_verbaut == 1 den Verbau des SCR Systems zeigt.";
CM_ SG_ 1607 SCR_Warnstufe_1 "Ansteuerung der SCR Füllstandswarnlampe (Stufe 1) (gelbe Lampe) SCR_Warnstufe_1 (Prio 2).
Bedienung des Signals nur bei Dieseln mit SCR-System. Andere senden Initwert.";
CM_ SG_ 1607 SCR_Warnstufe_2 "Ansteuerung der SCR Füllstandswarnlampe (Stufe 2) (Blinkbit für gelbe Lampe oder rote Lampe) SCR_Warnstufe_2 (Prio 1).
Bedienung des Signals nur bei Dieseln mit SCR-System. Andere senden Initwert.";

CM_ SG_ 168 MO_Drehzahl_01 "Im Fehlerfall wird die Motordrehzahl über die Nockenwellendrehzahl als Ersatzgrösse ausgegeben

Bei Parallelhybrid: Getriebeeingangsdrehzahl (=E-Maschinen Drehzahl)

Hinweis: 
Ehemaliger Fehlerwert 0xFFFF wird senderseitig nicht unterstützt. 
Diesen";
CM_ SG_ 168 MO_Mom_Begr_dyn "Einheitenloser Wert! Faktor in MO_Faktor_Momente (CAN V6.x) bzw. MO_Faktor_Momente_02 (CAN V7.x/V8.x) in Motor_Code_01 beachten!

Bei aktueller Drehzahl kurzfristig (ca. 100..200 ms) max. mögliches Moment (Summe aus Verbrennungsmotor und E-Motor), wird ";
CM_ SG_ 168 MO_Mom_Begr_stat "Einheitenloser Wert! Faktor in MO_Faktor_Momente (CAN V6.x) bzw. MO_Faktor_Momente_02 (CAN V7.x) in Motor_Code_01 beachten!

Bei aktueller Drehzahl quasistationär (nach ca. 3..5 s) max. mögliches Moment (Summe aus max. Moment des Verbrennungsmotors aus ";
CM_ SG_ 168 MO_Mom_neg_verfuegbar "Einheitenloser Wert! Faktor in MO_Faktor_Momente (CAN V6.x) bzw. MO_Faktor_Momente_02 (CAN V7.x) in Motor_Code_01 beachten!

Bei aktueller Drehzahl im nächsten Task (bei CAN-Übertragung z.B. 10ms) tatsächlich verfügbares negatives Moment (Summe aus Verl";
CM_ SG_ 168 MO_Momentenintegral_02 "100  %  entspricht volle Verfügbarkeit aktuell vorhanden. 0 % entspricht Integral bis Limit gefüllt, erhöhender Eingriff kann aktuell nicht berücksichtigt werden oder aufgrund eines Fehlers nicht verfügbar
";
CM_ SG_ 168 MO_QBit_Drehzahl_01 "AUDI D4: Zykluszeit: 10ms (siehe Zykluszeit schnell/Cycletime Fast)

Achtung:
Reduktion der Zykluszeit Motor_03 auf 10ms geplant.
Projektabhängig soll künftig mit 10ms gesendet werden.
Empfänger die in weiteren Konzern-Projekten eingesetzt werden müs";
CM_ SG_ 168 Motor_12_CRC "Für MLB:
'Berechnung siehe Lastenheft 'Kommunikationsabsicherung für FlexRay und CAN''

Ab MQB und MLBevo:
'Berechnung siehe Lastenheft 'End-to-End Kommunikationsabsicherung'

Endwerte siehe Begleitdokument 'S-PDU Kennungsfolgen'";

CM_ SG_ 958 MO_Aussp_Anlass "Das Signal zeigt an, ob die Wiederholstartsperre aktiv ist. D. h. eine Ansteuerung des Anlassers wird auch bei erfüllten Startvoraussetzungen (HS: Interlock betätigt bzw. AT: P/N eingelegt und Bremse betätigt) nicht erfolgen.";
CM_ SG_ 958 MO_BKV_Unterdruckwarnung "Über die Unterdruckwarnung signalisiert das MSG dem ESP, dass kein ausreichender Unterdruck für den BKV zur Verfügung gestellt werden kann.";
CM_ SG_ 958 MO_BLS "Ungefiltertes Rohsignal des Bremslichtschalters, nur wenn HW-Eingang bestückt und ausgewertet wird. Bei Motoren ohne genutzten HW-Eingang wird kein Ersatzwert (bspw. SW-Signal über CAN) ausgegeben!
Bei AUDI muss das Signal wg. Bremslichtfunktion immer be";
CM_ SG_ 958 MO_BMS_NV_Anf_stuetzen "Garantierte Unterstützung des Zusatzspeichers ist erforderlich. Zusatzspeicher muss an das Versorgungsnezt angebunden werden. ";
CM_ SG_ 958 MO_EKlKomLeiRed "Anforderung an die Klimasteuerung, die Leistungsaufnahme des E-Kompressors bei schlechtem SOC und in bestimmten Fahrsituationen zu begrenzen. (Das bereits bestehende Signal 'Klimakompressor aus' als stets umzusetzende Anforderung bleibt unverändert besteh";
CM_ SG_ 958 MO_Ext_E_Fahrt_aktiv "Funktionsrückmeldung zum erw. E-Fahr-Betrieb über Lampe/LED im E-Mode-Taster";
CM_ SG_ 958 MO_Fahrer_bremst "Redundante Bremsinformation vom Motor.

MLB:
AUDI D4: Zykluszeit: 10ms (siehe Zykluszeit schnell/Cycletime Fast)
Im AUDI B8 wird in diesem Bit der Wert der ESP-CAN-Information 'ESP_Fahrer_bremst' ausgegeben.

Achtung:
Reduktion der Zykluszeit Motor";
CM_ SG_ 958 MO_FMAus_aktiv "Das Signal gibt Rückmeldung ob Freilauf Motor aus aktiv ist. Beleibt auch 0km/h (unterhalb der StartStopp Schwelle) weiterhin aktiv.";
CM_ SG_ 958 MO_FMAus_Startvariante "Startvariante beim Motorstart aus der Freilauf-Motor-AUS Phase";
CM_ SG_ 958 MO_Freig_Anlass "Bit wird gesetzt, wenn der Motor beim Automatikstart gestartet werden darf (Motorstillstand, Emissionsmaßnahmen sind erfüllt).";
CM_ SG_ 958 MO_Freig_Reku "Empfehlung des Motor-SG's zur Spannungsabsenkung/-anhebung für den Rekuperationsbetrieb";
CM_ SG_ 958 MO_Freigabe_Segeln "Freigabebit des Segelbetriebs im Getriebe. Bedingt durch bestimmte Diagnosen und Adaptionen des MSGs, die nur im Schub möglich sind, darf nicht jede Schubphase für einen Segelbetrieb genutzt werden. Eine Freigabe bleibt auch außerhalb einer Schubphase bes";
CM_ SG_ 958 MO_Gangposition "MLB:
Stellung des Wählhebels in der Schaltgasse des Handschaltgetriebes.
MLBevo: 
Ausweitung der Bedienung auch auf Automatikgetriebe;
Routing des Signals GE_Fahrstufe: 
1. Position_R (dez. 6) auf MO_Gangposition: Gang_R (dez. 13) wegen Entfall Signa";
CM_ SG_ 958 MO_Handshake_STH "Es gilt: Signalspec MO_Handshake v1.0

Handshake zwischen MSG und STH. Wenn das MSG die EKP aufgrund einer STH-Anforderung ansteuert und kein Fehlereintrag bzgl. EKP/KPE/NDR vorliegt, wird das Bit gesetzt.";
CM_ SG_ 958 MO_HYB_Fahrbereitschaft "Signal steuert u.a. in der Lenkhilfe zusammen mit weiteren Informationen den Modewechsel in den 'Drivemode'
Grüne Anzeige im Kombiinstrument zur Signalisierung der Bereitschaft des Hybridsystems.";
CM_ SG_ 958 MO_HYB_VM_aktiv "0 = VMotor wird nicht aktiv gehalten (nVM < n_min und keine LL-Regelung aktiv)
1 = VMotor aktiv (ab der ersten Einspritzung; gilt auch für Schubbetrieb, wenn VMotor spätestens durch LLRegelung befeuert würde)
Verwendet zur Bestimmung des Ist-Zustandes";
CM_ SG_ 958 MO_Interlock "Das Motorsteuergerät gibt die Information aus, ab wann der Kupplungsschalter durch das Motorsteuergerät als getreten gesehen wird.
Bei Systemen für Start Stopp muss das Interlocksignal für einen Start durch das MSG generiert werden, sobald der Schalthebe";
CM_ SG_ 958 MO_Kickdown "Es gilt: Signalspec MO_Kickdown v1.0";
CM_ SG_ 958 MO_Kl_50 "Klemme 50: Startausführung durch Ritzelstarter

MLB: nicht von allen Motoren gesendet
MQB/MLBevo: gesendet von allen Motoren";
CM_ SG_ 958 MO_Kl_75 "Klemme X
";
CM_ SG_ 958 MO_Klima_Eingr "Eingriffe des Motor bei der Klima";
CM_ SG_ 958 MO_KomFehler_ESP "Anzeige Kommunikationsfehler bei Empfang vom ESP";
CM_ SG_ 958 MO_Konsistenz_Bremsped "MLB:

AUDI D4: Zykluszeit: 10ms (siehe Zykluszeit schnell/Cycletime Fast)
Siehe 'Funktionsspezifikation Bremslichtinfo B8'

Achtung:
Reduktion der Zykluszeit Motor_03 auf 10ms geplant.
Projektabhängig soll künftig mit 10ms gesendet werden.
Empfäng";
CM_ SG_ 958 MO_Kuppl_schalter "MLB:
Das Motorsteuergerät gibt die Information aus, ab wann der Kupplungsschalter durch das Motorsteuergerät als getreten gesehen wird
0x0: Schalter sagt betätigt (Ausgekuppelt)
0x1: Schalter sagt nicht betätigt (Eingekuppelt)

MQB:
Nur Handschalter";
CM_ SG_ 958 MO_Motor_laeuft "Das Motorsteuergerät gibt die Information aus, ab wann der Motor verbrennungsbedingt autark läuft und durch zuschaltbare Nebenaggregate mechanisch belastbar ist (z.B. durch Generator, Klimakompressor, etc.).

Die 'Motor läuft' Information wird ausgegebe";
CM_ SG_ 958 MO_PTC_Status "Status-Rückmeldung vom MSG zum aktuellen PTC-Status (stufiges PTC, Relais am MSG). Bei Ansteuerung eines stufigen PTC durch ein anderes SG beschreibt das Signal die vom MSG freigegebene PTC-Stufe.";
CM_ SG_ 958 MO_QBit_Fahrer_bremst "MLB:
AUDI D4: Zykluszeit: 10ms (siehe Zykluszeit schnell/Cycletime Fast)

Achtung:
Reduktion der Zykluszeit Motor_03 auf 10ms geplant.
Projektabhängig soll künftig mit 10ms gesendet werden.
Empfänger die in weiteren Konzern-Projekten eingesetzt werd";
CM_ SG_ 958 MO_QBit_Gangposition "Qualitätsbit zum Signal MO_Gangposition";
CM_ SG_ 958 MO_QBit_KL_75 "Q - Bit für das KL 75 Signal zur Vermeidung der fehlerhaften Erkennung von Motorstarts. 
Wird auf 1 gesetzt, solange das Motorsteuergerät KL15 = AUS erkannt hat.";
CM_ SG_ 958 MO_Remotestart_Betrieb "Das MSG ist für den Remotestart-Betrieb bereit. Nach Empfang der Motorstartanforderung für RSt-Betrieb durch BCM wird der Fahrzeugmotor gestartet und solange der Motor läuft, bleibt dieses Bit aktiv. Dieses Signal ist nur zur Verwendung durch das BCM zur ";
CM_ SG_ 958 MO_Remotestart_moeglich "Wenn Bit gesetzt, würde das MSG bei entsprechender Anforderung durch das BCM den Remotestartbetrieb einleiten, d.h. das MSG ist remotestartfähig und es liegen aktuell keine relevanten Fehler oder andere Abbruchgründe vor.";
CM_ SG_ 958 MO_Signalquelle_Gangposition "Signalquelle des Signals MO_Gangposition
0: Signalquelle Gangpositionssensor
1: Signalquelle Modellwert (v/n)";
CM_ SG_ 958 MO_StartStopp_Fahrerwunsch "Fahreraktivität Start/Stop";
CM_ SG_ 958 MO_StartStopp_Motorstopp "Motor-Stopp durch Start/Stopp-Koordinator
HYBRID:
Wenn MO_Hybridfahrzeug = 1 gilt:
Verbrennungsmotor durch Hybrid-Koordinator im MSG ausgeschaltet. 
Die definierten Start/Stopp-Signale beziehen sich nur auf den Verbrennungsmotor!";
CM_ SG_ 958 MO_StartStopp_Status "Aktivitätsstatus Start/Stopp-Koordinator
HYBRID:
Wenn MO_Hybridfahrzeug = 1 gilt:
Signal bezieht sich nur auf den Verbrennungsmotor, nicht auf den Hybridantrieb
";
CM_ SG_ 958 MO_StartStopp_Wiederstart "Motorwiederstart durch Start/Stopp-Koordinator
HYBRID:
Wenn MO_Hybridfahrzeug =1 gilt:
Warnung vor Spannungseinbruch beim Zustart des Verbrennungsmotors. 
-nicht relevant, da derzeit kein Start über 12V-Starter geplant-
Dieses Signal wird nur vom Hyb";
CM_ SG_ 958 MO_StartVorauss_erfuellt "Dient der Fallunterscheidung bei ZAT-Betätigung im Zustand 'KL15 ein' (bei nicht gesetztem Signal folgt KL15 aus, bei gesetztem Signal folgt setzen KL50-Anf.)

0: Signal nicht bedient 
1: Voraussetzungen zur Antriebsstrangaktivierung / Startvoraussetzu";
CM_ SG_ 958 MO_Text_Geschw_red "Anforderung an das Kombi die Textmeldung 'Geschwindigkeitsreduzierung' anzuzeigen";
CM_ SG_ 958 MO_Zylinderabschaltung "Status Zylinderabschaltung Motor";
CM_ SG_ 958 Motor_14_CRC "Ab MQB und MLBevo:
'Berechnung siehe Lastenheft 'End-to-End Kommunikationsabsicherung'

Endwerte siehe Begleitdokument 'S-PDU Kennungsfolgen'";

CM_ SG_ 1631 MO_Anzeige_Kaltleuchte "Fahrleistungseinschänkungen aus dem Motor-Abgasmanagement zur Anzeige als Lampe ohne Hinweistext im Kombiinstrument";
CM_ SG_ 1631 MO_DPF_reg "Regeneration Diesel-Partikel-Filter";
CM_ SG_ 1631 MO_Energieinhalt_BMS "Restenergieinhalt der Traktionsbatterie, beeinflusst durch Fahrstrategie und weiteren Faktoren der Antriebssteuerung.";
CM_ SG_ 1631 MO_Heizstrom_EKAT "Aktuelle Gesamtstromaufnahme des E-Katalysators";
CM_ SG_ 1631 MO_Heizstrom_SCR "Aktuelle Gesamtstromaufnahme der Tank-, Fördermodul- und Leitungsheizung des SCR-Systems";
CM_ SG_ 1631 MO_P_Generator_ungefiltert_Anf "Bei Empfang der Anforderung soll der Sender BEM_P_Generator ungefiltert befüllen.";
CM_ SG_ 1631 MO_SpannungsAnf_02 "Forderung des Motor-SG's zur Spannungsanhebung";
CM_ SG_ 1631 TSK_Fahrzeugmasse_02 "Neue Definition ab D4
Fahrzeugmasse in kg. Das Signal dient der Anpassung der Sollbeschleunigung vom ACC


";
CM_ SG_ 1631 TSK_Grundmasse "Fahrzeuggrundmasse in kg. Das Signal dient der Anpassung der Sollbeschleunigung vom ACC

Hinweis: Ehemaliger Fehlerwert 0x7F wird senderseitig nicht unterstützt. Diesen Wert aus Kompatibilitätsgründen nicht neu belegen!";
CM_ SG_ 1631 TSK_Steigung_02 "Steigung in % Berg. Das Signal dient der Anpassung der Sollbeschleunigung vom ACC

Positive Werte > bergauf; 
Negative Werte < bergab

Fehler: Die Steigung aufgrund eines Fehlers (mit KD-Fehlereintrag) nicht mehr berechnet werden";

CM_ SG_ 812 MO_BZS_Charisma_FahrPr "Rückmeldung des aktuellen Charisma-Fahrprogramms der MSG Betriebsstrategie

MLBevo: Aktuelles Fahrprogramm des Charisma-Teilnehmers (siehe Systemlastenheft Drive Select)
MQB: Istwert der Kennlinie (siehe Systemlastenheft MQB FPA)";
CM_ SG_ 812 MO_BZS_Charisma_Status "Charisma Systemstatus des Charisma-Teilnehmers MSG (Betriebszustände)

Wert 0x3 ist nur für Fahrzeuge ab MQB relevant";
CM_ SG_ 812 MO_Charisma_FahrPr "MLBevo: Aktuelles Fahrprogramm des Charisma-Teilnehmers (siehe Systemlastenheft Drive Select)
MQB: Istwert der Kennlinie (siehe Systemlastenheft MQB FPA)";
CM_ SG_ 812 MO_Charisma_Status "Charisma Systemstatus des Charisma-Teilnehmers

Wert 0x3 ist nur für Fahrzeuge ab MQB relevant";
CM_ SG_ 812 MO_Drehzahlbeeinflussung "Faktor zur Anhebung der Fahrdrehzahl im Warmlauf";
CM_ SG_ 812 MO_Luftpfad_aktiv "Getriebeeingriff wird zusätzlich zum Zündungspfad auch über den Luftpfad umgesetzt, kommt zu MLB neu in die PL48-Getriebe";
CM_ SG_ 812 MO_MAX_Wunschdrehzahl "maximale Motorwunschdrehzahl, die vom Getriebe nicht überschritten werden darf

Signal darf GE_Synchro_Wunschdrehzahl nicht spiegeln";
CM_ SG_ 812 MO_MIN_Wunschdrehzahl "minimale Motorwunschdrehzahl aufgrund Regeneration, die vom Getriebe nicht unterschritten werden darf

Hinweis: 
Ehemaliger Fehlerwert 0xFF wird senderseitig nicht unterstützt. 
Diesen Wert aus Kompatibilitätsgründen nicht neu belegen!";
CM_ SG_ 812 MO_NGS_Position "Messwert des Neutralgangsensors
(nur Handschalter)";
CM_ SG_ 812 MO_NGS_Status "Status des Signals MO_NGS_Position. Das MSG prüft die Plausibilität nur hinsichtlich sicher geöffnetem Triebstrang.";
CM_ SG_ 812 MO_Prio_MAX_Wunschdrehzahl "Prioritätsbit der Motorwunschdrehzahl  als MAX";
CM_ SG_ 812 MO_Prio_MIN_Wunschdrehzahl "Prioritätsbit der Motorwunschdrehzahl als MIN";
CM_ SG_ 812 MO_Rampenzeit_Generator_Anf "Das Motorsteuergerät kann eine Load-Response-Zeit des Generators vom Niedervoltenergiemanagement (NVEM) anfordern. Die Load-Response-Zeit wird vom NVEM umgesetzt, wenn dies bordnetzverträglich möglich ist.";
CM_ SG_ 812 MO_Sperrung_FahrPr_BZS "Sperrung einzelner Betriebszustände bzgl. Kommunikation zwischen Motor-SG und Charisma-SG (Gateway)";
CM_ SG_ 812 MO_StSt_Charisma_FahrPr "MLBevo: Aktuelles Fahrprogramm des Charisma-Teilnehmers (siehe Systemlastenheft Drive Select)
MQB: Istwert der Kennlinie (siehe Systemlastenheft MQB FPA)";
CM_ SG_ 812 MO_StSt_Charisma_Status "Charisma Systemstatus des Charisma-Teilnehmers

Wert 0x3 ist nur für Fahrzeuge ab MQB relevant";
CM_ SG_ 812 MO_v_Begrenz_Aktivierbar "Fehlerbit wird vom Motor-SG gesetzt, wenn dieses nicht in dieGeschwindigkeits-begrenzung gehen kann, ein Fehler während der v-Begrenzung auftritt oder v > v_Begrenzung - v_Delta";
CM_ SG_ 812 MO_v_Begrenzung_Niveau "Zeigt an, ob eine v-Begrenzung aufgrund Anforderung der Niveauregelung  im MSG aktiv ist oder nicht (Signal für Niveau zum Steuern der Kombianzeige).";
BA_DEF_REL_ BU_SG_REL_  "GenSigTimeoutTime" INT 0 65535;
BA_DEF_ BO_  "DiagRequest" ENUM "No", "Yes";
BA_DEF_ BO_  "DiagResponse" ENUM "No", "Yes";
BA_DEF_ BO_  "DiagState" ENUM "No", "Yes";
BA_DEF_ BO_  "GenMsgChkConstant" HEX 0 4095;
BA_DEF_ BO_  "GenMsgCycleTime" INT 0 65535;
BA_DEF_ BO_  "GenMsgCycleTimeFast" INT 0 65535;
BA_DEF_ BO_  "GenMsgDelayTime" INT 0 100000;
BA_DEF_ BO_  "GenMsgILSupport" ENUM "No", "Yes";
BA_DEF_ BO_  "GenMsgNrOfRepetition" INT 0 100;
BA_DEF_ BO_  "GenMsgPDUConstants" STRING;
BA_DEF_ BO_  "GenMsgSendType" ENUM "Cyclic", "not_used", "not_used", "not_used", "not_used", "not_used", "not_used", "IfActive", "NoMsgSendType";
BA_DEF_ BO_  "GenMsgStartDelayTime" INT 0 100000;
BA_DEF_ BO_  "NmMessage" ENUM "No", "Yes";
BA_DEF_ BO_  "NmhMessage" ENUM "No", "Yes";
BA_DEF_ BO_  "MsgType" ENUM "Application", "NM ", "NMH", "TP2.0", "ISO-TP ", "BAP", "EID", "KS", "XCP_PRE_CONFIGURED", "XCP_RUNTIME_CONFIGURED";
BA_DEF_ BO_  "VAGTP20_API" HEX 0 255;
BA_DEF_ BO_  "VAGTP20_DynConnection" ENUM "No", "Yes";
BA_DEF_ BO_  "VAGTP20_DynSetup" ENUM "No", "Yes";
BA_DEF_ BO_  "VAGTP20_StatConnection" ENUM "No", "Yes";
BA_DEF_ SG_  "GenSigActiveRepetitions" INT -2147483648 2147483647;
BA_DEF_ SG_  "GenSigInactiveValue" INT -2147483648 2147483647;
BA_DEF_ SG_  "GenSigSendType" ENUM "Cyclic", "OnWrite", "OnWriteWithRepetition", "OnChange", "OnChangeWithRepetition", "IfActive", "IfActiveWithRepetition", "NoSigSendType", "OnChangeAndIfActive", "OnChangeAndIfActiveWithRepetition";
BA_DEF_ SG_  "GenSigStartValue" INT -2147483648 2147483647;
BA_DEF_ SG_  "NWM-WakeupAllowed" ENUM "No", "Yes";
BA_DEF_ SG_  "GenSigFuncType" ENUM "NoFunction", "MsgCounter", "CRC-8", "XOR", "XOR-2", "DatedBit", "SW-Kl15", "CHK", "Constant", "Protocol", "CRC-8-SAE_J1850", "CRC-32", "DataLength", "DataID", "MsgCounter16", "SOK-Signatur", "Cluster";
BA_DEF_ SG_  "GenSigSwitchedByIgnition" ENUM "No", "Yes";
BA_DEF_ SG_  "Fehlerwert" HEX 0 2147483647;
BA_DEF_ SG_  "GenSigMissingSourceValue" HEX 0 2147483647;
BA_DEF_DEF_REL_  "GenSigTimeoutTime" 0;
BA_DEF_DEF_  "DiagRequest" "No";
BA_DEF_DEF_  "DiagResponse" "No";
BA_DEF_DEF_  "DiagState" "No";
BA_DEF_DEF_  "GenMsgChkConstant" 0;
BA_DEF_DEF_  "GenMsgCycleTime" 0;
BA_DEF_DEF_  "GenMsgCycleTimeFast" 0;
BA_DEF_DEF_  "GenMsgDelayTime" 0;
BA_DEF_DEF_  "GenMsgILSupport" "No";
BA_DEF_DEF_  "GenMsgNrOfRepetition" 0;
BA_DEF_DEF_  "GenMsgPDUConstants" "";
BA_DEF_DEF_  "GenMsgSendType" "NoMsgSendType";
BA_DEF_DEF_  "GenMsgStartDelayTime" 0;
BA_DEF_DEF_  "NmMessage" "No";
BA_DEF_DEF_  "NmhMessage" "No";
BA_DEF_DEF_  "MsgType" "Application";
BA_DEF_DEF_  "VAGTP20_API" 0;
BA_DEF_DEF_  "VAGTP20_DynConnection" "No";
BA_DEF_DEF_  "VAGTP20_DynSetup" "No";
BA_DEF_DEF_  "VAGTP20_StatConnection" "No";
BA_DEF_DEF_  "GenSigActiveRepetitions" 0;
BA_DEF_DEF_  "GenSigInactiveValue" 0;
BA_DEF_DEF_  "GenSigSendType" "NoSigSendType";
BA_DEF_DEF_  "GenSigStartValue" 0;
BA_DEF_DEF_  "NWM-WakeupAllowed" "No";
BA_DEF_DEF_  "GenSigFuncType" "NoFunction";
BA_DEF_DEF_  "GenSigSwitchedByIgnition" "Yes";
BA_DEF_DEF_  "Fehlerwert" 0;
BA_DEF_DEF_  "GenSigMissingSourceValue" 0;
BA_ "GenMsgCycleTime" BO_ 1624 1000;
BA_ "GenMsgDelayTime" BO_ 1624 50;
BA_ "GenMsgILSupport" BO_ 1624 1;
BA_ "GenMsgPDUConstants" BO_ 1624 "0x46,0x0f,0xe0,0xcc,0xbe,0xb1,0xd7,0xf1,0x1f,0x31,0xc1,0x25,0xb4,0x3e,0xc8,0xa3";
BA_ "GenMsgSendType" BO_ 1624 0;
BA_ "GenMsgCycleTime" BO_ 1321 200;
BA_ "GenMsgDelayTime" BO_ 1321 20;
BA_ "GenMsgILSupport" BO_ 1321 1;
BA_ "GenMsgSendType" BO_ 1321 0;
BA_ "GenMsgCycleTime" BO_ 822 120;
BA_ "GenMsgILSupport" BO_ 822 1;
BA_ "GenMsgSendType" BO_ 822 0;
BA_ "GenMsgCycleTime" BO_ 2527679652 960;
BA_ "GenMsgCycleTimeFast" BO_ 2527679652 160;
BA_ "GenMsgDelayTime" BO_ 2527679652 160;
BA_ "GenMsgILSupport" BO_ 2527679652 1;
BA_ "GenMsgNrOfRepetition" BO_ 2527679652 5;
BA_ "GenMsgSendType" BO_ 2527679652 0;
BA_ "GenMsgChkConstant" BO_ 134 134;
BA_ "GenMsgCycleTime" BO_ 134 100;
BA_ "GenMsgILSupport" BO_ 134 1;
BA_ "GenMsgPDUConstants" BO_ 134 "0x86,0x86,0x86,0x86,0x86,0x86,0x86,0x86,0x86,0x86,0x86,0x86,0x86,0x86,0x86,0x86";
BA_ "GenMsgSendType" BO_ 134 0;
BA_ "GenMsgCycleTime" BO_ 917 100;
BA_ "GenMsgDelayTime" BO_ 917 10;
BA_ "GenMsgILSupport" BO_ 917 1;
BA_ "GenMsgSendType" BO_ 917 0;
BA_ "GenMsgCycleTime" BO_ 1153 500;
BA_ "GenMsgCycleTimeFast" BO_ 1153 50;
BA_ "GenMsgDelayTime" BO_ 1153 50;
BA_ "GenMsgILSupport" BO_ 1153 1;
BA_ "GenMsgNrOfRepetition" BO_ 1153 5;
BA_ "GenMsgSendType" BO_ 1153 0;
BA_ "GenMsgCycleTime" BO_ 1639 100;
BA_ "GenMsgDelayTime" BO_ 1639 50;
BA_ "GenMsgILSupport" BO_ 1639 1;
BA_ "GenMsgSendType" BO_ 1639 0;
BA_ "GenMsgCycleTime" BO_ 1178 100;
BA_ "GenMsgDelayTime" BO_ 1178 50;
BA_ "GenMsgILSupport" BO_ 1178 1;
BA_ "GenMsgSendType" BO_ 1178 0;
BA_ "GenMsgChkConstant" BO_ 1171 151;
BA_ "GenMsgCycleTime" BO_ 1171 200;
BA_ "GenMsgDelayTime" BO_ 1171 20;
BA_ "GenMsgILSupport" BO_ 1171 1;
BA_ "GenMsgPDUConstants" BO_ 1171 "0x97,0x97,0x97,0x97,0x97,0x97,0x97,0x97,0x97,0x97,0x97,0x97,0x97,0x97,0x97,0x97";
BA_ "GenMsgSendType" BO_ 1171 0;
BA_ "GenMsgCycleTime" BO_ 817 500;
BA_ "GenMsgCycleTimeFast" BO_ 817 30;
BA_ "GenMsgILSupport" BO_ 817 1;
BA_ "GenMsgSendType" BO_ 817 0;
BA_ "GenMsgCycleTime" BO_ 1600 320;
BA_ "GenMsgILSupport" BO_ 1600 1;
BA_ "GenMsgSendType" BO_ 1600 0;
BA_ "GenMsgCycleTime" BO_ 1607 320;
BA_ "GenMsgILSupport" BO_ 1607 1;
BA_ "GenMsgSendType" BO_ 1607 0;
BA_ "GenMsgCycleTime" BO_ 168 10;
BA_ "GenMsgILSupport" BO_ 168 1;
BA_ "GenMsgPDUConstants" BO_ 168 "0x52,0x8c,0x50,0xee,0x4f,0xa6,0xcc,0xcf,0x7d,0x2f,0x98,0x6b,0x27,0x41,0x9f,0x93";
BA_ "GenMsgSendType" BO_ 168 0;
BA_ "GenMsgCycleTime" BO_ 958 100;
BA_ "GenMsgDelayTime" BO_ 958 10;
BA_ "GenMsgILSupport" BO_ 958 1;
BA_ "GenMsgPDUConstants" BO_ 958 "0x1f,0x28,0xc6,0x85,0xe6,0xf8,0xb0,0x19,0x5b,0x64,0x35,0x21,0xe4,0xf7,0x9c,0x24";
BA_ "GenMsgSendType" BO_ 958 0;
BA_ "GenMsgCycleTime" BO_ 1631 320;
BA_ "GenMsgILSupport" BO_ 1631 1;
BA_ "GenMsgSendType" BO_ 1631 0;
BA_ "GenMsgCycleTime" BO_ 812 200;
BA_ "GenMsgDelayTime" BO_ 812 40;
BA_ "GenMsgILSupport" BO_ 812 1;
BA_ "GenMsgSendType" BO_ 812 0;
BA_ "GenSigSendType" SG_ 1624 BCM1_Licht_Dunkelheit_aktiv 3;
BA_ "GenSigSwitchedByIgnition" SG_ 1624 BCM1_Licht_Dunkelheit_aktiv 0;
BA_ "GenSigSendType" SG_ 1624 BCM1_Linksverkehr 0;
BA_ "GenSigSwitchedByIgnition" SG_ 1624 BCM1_Linksverkehr 0;
BA_ "GenSigSendType" SG_ 1624 Licht_Vorne_01_BZ 0;
BA_ "GenSigFuncType" SG_ 1624 Licht_Vorne_01_BZ 1;
BA_ "GenSigSendType" SG_ 1624 Licht_Vorne_01_CRC 0;
BA_ "GenSigFuncType" SG_ 1624 Licht_Vorne_01_CRC 2;
BA_ "GenSigSendType" SG_ 1624 LV_Abbiegelicht_li_def 0;
BA_ "GenSigSwitchedByIgnition" SG_ 1624 LV_Abbiegelicht_li_def 0;
BA_ "GenSigSendType" SG_ 1624 LV_Abbiegelicht_re_def 0;
BA_ "GenSigSwitchedByIgnition" SG_ 1624 LV_Abbiegelicht_re_def 0;
BA_ "GenSigSendType" SG_ 1624 LV_Abblend_Fernlicht_li_def 0;
BA_ "GenSigSwitchedByIgnition" SG_ 1624 LV_Abblend_Fernlicht_li_def 0;
BA_ "GenSigSendType" SG_ 1624 LV_Abblend_Fernlicht_re_def 0;
BA_ "GenSigSwitchedByIgnition" SG_ 1624 LV_Abblend_Fernlicht_re_def 0;
BA_ "GenSigSendType" SG_ 1624 LV_Abblendlicht_Anzeige 3;
BA_ "GenSigSwitchedByIgnition" SG_ 1624 LV_Abblendlicht_Anzeige 0;
BA_ "GenSigSendType" SG_ 1624 LV_Abblendlicht_li_def 0;
BA_ "GenSigSwitchedByIgnition" SG_ 1624 LV_Abblendlicht_li_def 0;
BA_ "GenSigSendType" SG_ 1624 LV_Abblendlicht_re_def 0;
BA_ "GenSigSwitchedByIgnition" SG_ 1624 LV_Abblendlicht_re_def 0;
BA_ "GenSigSendType" SG_ 1624 LV_Abblendlicht_TFL_li_def 0;
BA_ "GenSigSwitchedByIgnition" SG_ 1624 LV_Abblendlicht_TFL_li_def 0;
BA_ "GenSigSendType" SG_ 1624 LV_Abblendlicht_TFL_re_def 0;
BA_ "GenSigSwitchedByIgnition" SG_ 1624 LV_Abblendlicht_TFL_re_def 0;
BA_ "GenSigSendType" SG_ 1624 LV_AFL_aktiv_Anzeige 3;
BA_ "GenSigSwitchedByIgnition" SG_ 1624 LV_AFL_aktiv_Anzeige 0;
BA_ "GenSigSendType" SG_ 1624 LV_AFL_defekt 3;
BA_ "GenSigSwitchedByIgnition" SG_ 1624 LV_AFL_defekt 0;
BA_ "GenSigSendType" SG_ 1624 LV_Aussenlicht_def 3;
BA_ "GenSigSwitchedByIgnition" SG_ 1624 LV_Aussenlicht_def 0;
BA_ "GenSigSendType" SG_ 1624 LV_Blinker_li_def 3;
BA_ "GenSigSwitchedByIgnition" SG_ 1624 LV_Blinker_li_def 0;
BA_ "GenSigSendType" SG_ 1624 LV_Blinker_re_def 3;
BA_ "GenSigSwitchedByIgnition" SG_ 1624 LV_Blinker_re_def 0;
BA_ "GenSigSendType" SG_ 1624 LV_Blinker_VL_aktiv 3;
BA_ "GenSigSwitchedByIgnition" SG_ 1624 LV_Blinker_VL_aktiv 0;
BA_ "GenSigSendType" SG_ 1624 LV_Blinker_VR_aktiv 3;
BA_ "GenSigSwitchedByIgnition" SG_ 1624 LV_Blinker_VR_aktiv 0;
BA_ "GenSigSendType" SG_ 1624 LV_Blk_li_Seite_def 0;
BA_ "GenSigSwitchedByIgnition" SG_ 1624 LV_Blk_li_Seite_def 0;
BA_ "GenSigSendType" SG_ 1624 LV_Blk_re_Seite_def 0;
BA_ "GenSigSwitchedByIgnition" SG_ 1624 LV_Blk_re_Seite_def 0;
BA_ "GenSigSendType" SG_ 1624 LV_Fernlicht_Anzeige 3;
BA_ "GenSigSwitchedByIgnition" SG_ 1624 LV_Fernlicht_Anzeige 0;
BA_ "GenSigSendType" SG_ 1624 LV_Fernlicht_li_def 0;
BA_ "GenSigSwitchedByIgnition" SG_ 1624 LV_Fernlicht_li_def 0;
BA_ "GenSigSendType" SG_ 1624 LV_Fernlicht_re_def 0;
BA_ "GenSigSwitchedByIgnition" SG_ 1624 LV_Fernlicht_re_def 0;
BA_ "GenSigSendType" SG_ 1624 LV_FLA_aktiv_Anzeige 3;
BA_ "GenSigSwitchedByIgnition" SG_ 1624 LV_FLA_aktiv_Anzeige 0;
BA_ "GenSigSendType" SG_ 1624 LV_FLA_defekt 0;
BA_ "GenSigSwitchedByIgnition" SG_ 1624 LV_FLA_defekt 0;
BA_ "GenSigSendType" SG_ 1624 LV_FLA_Sensor_blockiert 0;
BA_ "GenSigSwitchedByIgnition" SG_ 1624 LV_FLA_Sensor_blockiert 0;
BA_ "GenSigSendType" SG_ 1624 LV_LED_Scheinwerfer_li_def 0;
BA_ "GenSigSwitchedByIgnition" SG_ 1624 LV_LED_Scheinwerfer_li_def 0;
BA_ "GenSigSendType" SG_ 1624 LV_LED_Scheinwerfer_re_def 0;
BA_ "GenSigSwitchedByIgnition" SG_ 1624 LV_LED_Scheinwerfer_re_def 0;
BA_ "GenSigSendType" SG_ 1624 LV_MXB_Status_Anzeige 3;
BA_ "GenSigSwitchedByIgnition" SG_ 1624 LV_MXB_Status_Anzeige 0;
BA_ "GenSigSendType" SG_ 1624 LV_Nebellicht_Anzeige 3;
BA_ "GenSigSwitchedByIgnition" SG_ 1624 LV_Nebellicht_Anzeige 0;
BA_ "GenSigSendType" SG_ 1624 LV_Nebellicht_li_def 0;
BA_ "GenSigSwitchedByIgnition" SG_ 1624 LV_Nebellicht_li_def 0;
BA_ "GenSigSendType" SG_ 1624 LV_Nebellicht_re_def 0;
BA_ "GenSigSwitchedByIgnition" SG_ 1624 LV_Nebellicht_re_def 0;
BA_ "GenSigSendType" SG_ 1624 LV_Nebellicht_TFL_li_def 0;
BA_ "GenSigSwitchedByIgnition" SG_ 1624 LV_Nebellicht_TFL_li_def 0;
BA_ "GenSigSendType" SG_ 1624 LV_Nebellicht_TFL_re_def 0;
BA_ "GenSigSwitchedByIgnition" SG_ 1624 LV_Nebellicht_TFL_re_def 0;
BA_ "GenSigSendType" SG_ 1624 LV_Nebelschlusslicht_Anzeige 3;
BA_ "GenSigSwitchedByIgnition" SG_ 1624 LV_Nebelschlusslicht_Anzeige 0;
BA_ "GenSigSendType" SG_ 1624 LV_Standlicht_Anzeige 3;
BA_ "GenSigSwitchedByIgnition" SG_ 1624 LV_Standlicht_Anzeige 0;
BA_ "GenSigSendType" SG_ 1624 LV_Standlicht_li_def 0;
BA_ "GenSigSwitchedByIgnition" SG_ 1624 LV_Standlicht_li_def 0;
BA_ "GenSigSendType" SG_ 1624 LV_Standlicht_re_def 0;
BA_ "GenSigSwitchedByIgnition" SG_ 1624 LV_Standlicht_re_def 0;
BA_ "GenSigSendType" SG_ 1624 LV_Standlicht_TFL_li_def 0;
BA_ "GenSigSwitchedByIgnition" SG_ 1624 LV_Standlicht_TFL_li_def 0;
BA_ "GenSigSendType" SG_ 1624 LV_Standlicht_TFL_re_def 0;
BA_ "GenSigSwitchedByIgnition" SG_ 1624 LV_Standlicht_TFL_re_def 0;
BA_ "GenSigSendType" SG_ 1624 LV_Tagfahrlicht_Anzeige 3;
BA_ "GenSigSwitchedByIgnition" SG_ 1624 LV_Tagfahrlicht_Anzeige 0;
BA_ "GenSigSendType" SG_ 1624 LV_Tagfahrlicht_li_def 0;
BA_ "GenSigSwitchedByIgnition" SG_ 1624 LV_Tagfahrlicht_li_def 0;
BA_ "GenSigSendType" SG_ 1624 LV_Tagfahrlicht_re_def 0;
BA_ "GenSigSwitchedByIgnition" SG_ 1624 LV_Tagfahrlicht_re_def 0;
BA_ "GenSigSendType" SG_ 1321 Lift_Anforderung_EFP 3;
BA_ "GenSigSwitchedByIgnition" SG_ 1321 Lift_Anforderung_EFP 0;
BA_ "GenSigSendType" SG_ 1321 Lift_Charisma_FahrPr 3;
BA_ "GenSigSwitchedByIgnition" SG_ 1321 Lift_Charisma_FahrPr 0;
BA_ "GenSigSendType" SG_ 1321 Lift_Charisma_Status 3;
BA_ "GenSigSwitchedByIgnition" SG_ 1321 Lift_Charisma_Status 0;
BA_ "GenSigSendType" SG_ 1321 Lift_Charisma_Umschaltung 3;
BA_ "GenSigSwitchedByIgnition" SG_ 1321 Lift_Charisma_Umschaltung 0;
BA_ "GenSigSendType" SG_ 1321 Lift_ESP_Zuschaltung 3;
BA_ "GenSigSwitchedByIgnition" SG_ 1321 Lift_ESP_Zuschaltung 0;
BA_ "GenSigSendType" SG_ 1321 Lift_LED 3;
BA_ "GenSigSwitchedByIgnition" SG_ 1321 Lift_LED 0;
BA_ "Fehlerwert" SG_ 1321 Lift_LED 3;
BA_ "GenSigSendType" SG_ 1321 Lift_Meldung_01 3;
BA_ "GenSigSwitchedByIgnition" SG_ 1321 Lift_Meldung_01 0;
BA_ "GenSigSendType" SG_ 1321 Lift_Meldung_02 3;
BA_ "GenSigSwitchedByIgnition" SG_ 1321 Lift_Meldung_02 0;
BA_ "GenSigSendType" SG_ 1321 Lift_Meldung_03 3;
BA_ "GenSigSwitchedByIgnition" SG_ 1321 Lift_Meldung_03 0;
BA_ "GenSigSendType" SG_ 1321 Lift_Meldung_04 3;
BA_ "GenSigSwitchedByIgnition" SG_ 1321 Lift_Meldung_04 0;
BA_ "GenSigSendType" SG_ 1321 Lift_Meldung_05 3;
BA_ "GenSigSwitchedByIgnition" SG_ 1321 Lift_Meldung_05 0;
BA_ "GenSigSendType" SG_ 1321 Lift_Meldung_06 3;
BA_ "GenSigSwitchedByIgnition" SG_ 1321 Lift_Meldung_06 0;
BA_ "GenSigSendType" SG_ 1321 Lift_Meldung_07 3;
BA_ "GenSigSwitchedByIgnition" SG_ 1321 Lift_Meldung_07 0;
BA_ "GenSigSendType" SG_ 1321 Lift_Meldung_08 3;
BA_ "GenSigSwitchedByIgnition" SG_ 1321 Lift_Meldung_08 0;
BA_ "GenSigSendType" SG_ 1321 Lift_Meldung_09 3;
BA_ "GenSigSwitchedByIgnition" SG_ 1321 Lift_Meldung_09 0;
BA_ "GenSigSendType" SG_ 1321 Lift_Meldung_10 3;
BA_ "GenSigSwitchedByIgnition" SG_ 1321 Lift_Meldung_10 0;
BA_ "GenSigSendType" SG_ 1321 Lift_Meldung_11 3;
BA_ "GenSigSwitchedByIgnition" SG_ 1321 Lift_Meldung_11 0;
BA_ "GenSigSendType" SG_ 1321 Lift_Meldung_12 3;
BA_ "GenSigSwitchedByIgnition" SG_ 1321 Lift_Meldung_12 0;
BA_ "GenSigSendType" SG_ 1321 Lift_Meldung_13 3;
BA_ "GenSigSwitchedByIgnition" SG_ 1321 Lift_Meldung_13 0;
BA_ "GenSigSendType" SG_ 1321 Lift_Meldung_14 3;
BA_ "GenSigSwitchedByIgnition" SG_ 1321 Lift_Meldung_14 0;
BA_ "GenSigSendType" SG_ 1321 Lift_Position 3;
BA_ "GenSigSwitchedByIgnition" SG_ 1321 Lift_Position 0;
BA_ "GenSigSendType" SG_ 1321 Lift_SpannungsAnf 3;
BA_ "GenSigSwitchedByIgnition" SG_ 1321 Lift_SpannungsAnf 0;
BA_ "GenSigSendType" SG_ 1321 Lift_StartStopp_Info 3;
BA_ "GenSigSendType" SG_ 822 LR_HZG_Taster_on_off 0;
BA_ "GenSigSwitchedByIgnition" SG_ 822 LR_HZG_Taster_on_off 0;
BA_ "GenSigSendType" SG_ 822 LR_HZG_Temp_Sensor 0;
BA_ "GenSigStartValue" SG_ 822 LR_HZG_Temp_Sensor 254;
BA_ "GenSigSwitchedByIgnition" SG_ 822 LR_HZG_Temp_Sensor 0;
BA_ "GenSigActiveRepetitions" SG_ 2527679652 LS1_Reinigung_Anf 5;
BA_ "GenSigSendType" SG_ 2527679652 LS1_Reinigung_Anf 4;
BA_ "GenSigSendType" SG_ 134 LWI_01_BZ 0;
BA_ "GenSigFuncType" SG_ 134 LWI_01_BZ 1;
BA_ "GenSigSendType" SG_ 134 LWI_01_CRC 0;
BA_ "GenSigFuncType" SG_ 134 LWI_01_CRC 2;
BA_ "GenSigSwitchedByIgnition" SG_ 134 LWI_01_CRC 0;
BA_ "GenSigSendType" SG_ 134 LWI_Lenkradw_Geschw 0;
BA_ "GenSigStartValue" SG_ 134 LWI_Lenkradw_Geschw 510;
BA_ "Fehlerwert" SG_ 134 LWI_Lenkradw_Geschw 511;
BA_ "GenSigSendType" SG_ 134 LWI_Lenkradwinkel 0;
BA_ "GenSigStartValue" SG_ 134 LWI_Lenkradwinkel 8190;
BA_ "Fehlerwert" SG_ 134 LWI_Lenkradwinkel 8191;
BA_ "GenSigSendType" SG_ 134 LWI_MFL_Abschaltung 0;
BA_ "GenSigSwitchedByIgnition" SG_ 134 LWI_MFL_Abschaltung 0;
BA_ "GenSigSendType" SG_ 134 LWI_QBit_Lenkradwinkel 0;
BA_ "GenSigStartValue" SG_ 134 LWI_QBit_Lenkradwinkel 1;
BA_ "GenSigSendType" SG_ 134 LWI_QBit_Sub_Daten 0;
BA_ "GenSigSendType" SG_ 134 LWI_Sensorstatus 0;
BA_ "GenSigSendType" SG_ 134 LWI_Sub_Daten 0;
BA_ "GenSigSendType" SG_ 134 LWI_VZ_Lenkradw_Geschw 0;
BA_ "GenSigSendType" SG_ 134 LWI_VZ_Lenkradwinkel 0;
BA_ "GenSigSendType" SG_ 917 AFS_Abbiegelicht_Dimm_Anf 0;
BA_ "GenSigSendType" SG_ 917 AFS_Abbiegelicht_li_Anf 0;
BA_ "GenSigSendType" SG_ 917 AFS_Abbiegelicht_re_Anf 0;
BA_ "GenSigSendType" SG_ 917 AFS_adaptive_LV_verbaut 0;
BA_ "GenSigSendType" SG_ 917 AFS_Allwetterlicht 0;
BA_ "GenSigSendType" SG_ 917 AFS_Charisma_FahrPr 0;
BA_ "GenSigSendType" SG_ 917 AFS_Charisma_Status 0;
BA_ "GenSigSendType" SG_ 917 AFS_Charisma_Umschaltung 3;
BA_ "GenSigSendType" SG_ 917 AFS_Ersatzlicht_Links 0;
BA_ "GenSigSendType" SG_ 917 AFS_Ersatzlicht_Rechts 0;
BA_ "GenSigSendType" SG_ 917 AFS_Fehlertext 0;
BA_ "GenSigSendType" SG_ 917 AFS_Fernlicht_li_defekt 0;
BA_ "GenSigSendType" SG_ 917 AFS_Fernlicht_re_defekt 0;
BA_ "GenSigSendType" SG_ 917 AFS_Fernlicht_Status 3;
BA_ "GenSigSendType" SG_ 917 AFS_Lampe 0;
BA_ "GenSigSendType" SG_ 917 AFS_LED_Blinkmode 0;
BA_ "GenSigSendType" SG_ 917 AFS_Status_adaptive_LV 0;
BA_ "GenSigStartValue" SG_ 917 AFS_Status_adaptive_LV 1;
BA_ "GenSigSendType" SG_ 917 AFS_Verfuegbarkeit_GLW 0;
BA_ "GenSigStartValue" SG_ 917 AFS_Verfuegbarkeit_GLW 1;
BA_ "GenSigSendType" SG_ 917 GLW_Sensor_blockiert 0;
BA_ "GenSigSendType" SG_ 917 LWR_AFS_01_BZ 0;
BA_ "GenSigFuncType" SG_ 917 LWR_AFS_01_BZ 1;
BA_ "GenSigSendType" SG_ 917 LWR_AFS_Grundeinstellung 0;
BA_ "GenSigSendType" SG_ 917 LWR_AFS_Parametrisierung 0;
BA_ "GenSigSendType" SG_ 917 LWR_Hoehenwert_HL 0;
BA_ "GenSigStartValue" SG_ 917 LWR_Hoehenwert_HL 254;
BA_ "Fehlerwert" SG_ 917 LWR_Hoehenwert_HL 255;
BA_ "GenSigSendType" SG_ 917 LWR_Hoehenwert_VL 0;
BA_ "GenSigStartValue" SG_ 917 LWR_Hoehenwert_VL 254;
BA_ "Fehlerwert" SG_ 917 LWR_Hoehenwert_VL 255;
BA_ "GenSigSendType" SG_ 917 LWR_Initialisierungslauf 0;
BA_ "GenSigSendType" SG_ 917 LWR_Lampe 0;
BA_ "GenSigSendType" SG_ 917 LWR_Modus 0;
BA_ "GenSigSendType" SG_ 917 LWR_Pos_Schrittmotor 0;
BA_ "GenSigStartValue" SG_ 917 LWR_Pos_Schrittmotor 254;
BA_ "Fehlerwert" SG_ 917 LWR_Pos_Schrittmotor 255;
BA_ "GenSigSendType" SG_ 917 LWR_Reisemodus_Texte 0;
BA_ "GenSigSendType" SG_ 917 LWR_Sicherheitsposition_li 0;
BA_ "GenSigSendType" SG_ 917 LWR_Sicherheitsposition_re 0;
BA_ "GenSigSendType" SG_ 917 LWR_Touristenmodus_aktiv 0;
BA_ "GenSigSendType" SG_ 917 LWR_Touristenmodus_verbaut 0;
BA_ "GenSigSendType" SG_ 1153 DSSS_Warning 3;
BA_ "GenSigSwitchedByIgnition" SG_ 1153 DSSS_Warning 0;
BA_ "GenSigSendType" SG_ 1153 MIB_Tongenerator_PH_verfuegbar 3;
BA_ "GenSigSwitchedByIgnition" SG_ 1153 MIB_Tongenerator_PH_verfuegbar 0;
BA_ "GenSigSendType" SG_ 1153 MMI_Counter_Bedienevent 0;
BA_ "GenSigSwitchedByIgnition" SG_ 1153 MMI_Counter_Bedienevent 0;
BA_ "GenSigSendType" SG_ 1153 MMI_Gauges_active 3;
BA_ "GenSigSwitchedByIgnition" SG_ 1153 MMI_Gauges_active 0;
BA_ "GenSigSendType" SG_ 1153 MMI_Gurt_Mic_ref 0;
BA_ "GenSigSwitchedByIgnition" SG_ 1153 MMI_Gurt_Mic_ref 0;
BA_ "GenSigSendType" SG_ 1153 MMI_SDS_aktiv 3;
BA_ "GenSigSwitchedByIgnition" SG_ 1153 MMI_SDS_aktiv 0;
BA_ "GenSigSendType" SG_ 1153 MMI_StartStopp_Info 3;
BA_ "GenSigSwitchedByIgnition" SG_ 1153 MMI_StartStopp_Info 0;
BA_ "Fehlerwert" SG_ 1153 MMI_StartStopp_Info 3;
BA_ "GenSigSendType" SG_ 1153 MMI_Telefon_aktiv 3;
BA_ "GenSigSwitchedByIgnition" SG_ 1153 MMI_Telefon_aktiv 0;
BA_ "GenSigSendType" SG_ 1153 MU_SecondDisplay 3;
BA_ "GenSigSwitchedByIgnition" SG_ 1153 MU_SecondDisplay 0;
BA_ "GenSigSendType" SG_ 1153 MU_Update_Time 0;
BA_ "GenSigSwitchedByIgnition" SG_ 1153 MU_Update_Time 0;
BA_ "GenSigSendType" SG_ 1153 Nav_FoD_Status 3;
BA_ "GenSigSwitchedByIgnition" SG_ 1153 Nav_FoD_Status 0;
BA_ "GenSigSendType" SG_ 1153 ZR_Kindersicherung_RSE 3;
BA_ "GenSigSwitchedByIgnition" SG_ 1153 ZR_Kindersicherung_RSE 0;
BA_ "GenSigSendType" SG_ 1153 ZR_LAPP_Sondermodus_Status 3;
BA_ "GenSigSendType" SG_ 1153 ZR_LoGeWa_Event_Kombiwarnung 3;
BA_ "GenSigSwitchedByIgnition" SG_ 1153 ZR_LoGeWa_Event_Kombiwarnung 0;
BA_ "GenSigSendType" SG_ 1153 ZR_MXB_Manoever_Ansage 3;
BA_ "GenSigSwitchedByIgnition" SG_ 1153 ZR_MXB_Manoever_Ansage 0;
BA_ "GenSigSendType" SG_ 1153 ZR_Parken_Sondermodus 3;
BA_ "GenSigSwitchedByIgnition" SG_ 1153 ZR_Parken_Sondermodus 0;
BA_ "GenSigSendType" SG_ 1153 ZR_RSE_aktivieren 3;
BA_ "GenSigSwitchedByIgnition" SG_ 1153 ZR_RSE_aktivieren 0;
BA_ "GenSigSendType" SG_ 1153 ZR_Rundenbewertung 3;
BA_ "GenSigStartValue" SG_ 1153 ZR_Rundenbewertung 14;
BA_ "GenSigSwitchedByIgnition" SG_ 1153 ZR_Rundenbewertung 0;
BA_ "GenSigSendType" SG_ 1153 ZR_Rundenfortschritt 3;
BA_ "GenSigStartValue" SG_ 1153 ZR_Rundenfortschritt 254;
BA_ "GenSigSwitchedByIgnition" SG_ 1153 ZR_Rundenfortschritt 0;
BA_ "GenSigActiveRepetitions" SG_ 1153 ZR_Sta_Inszenierung 5;
BA_ "GenSigSendType" SG_ 1153 ZR_Sta_Inszenierung 4;
BA_ "GenSigSwitchedByIgnition" SG_ 1153 ZR_Sta_Inszenierung 0;
BA_ "GenSigSendType" SG_ 1639 BFS_Fond_Bed_Ack 3;
BA_ "GenSigSwitchedByIgnition" SG_ 1639 BFS_Fond_Bed_Ack 0;
BA_ "GenSigSendType" SG_ 1639 BFS_FSV_ausgeklappt 0;
BA_ "GenSigSwitchedByIgnition" SG_ 1639 BFS_FSV_ausgeklappt 0;
BA_ "GenSigSendType" SG_ 1639 BFS_GHV_aktiv 3;
BA_ "GenSigSwitchedByIgnition" SG_ 1639 BFS_GHV_aktiv 0;
BA_ "GenSigSendType" SG_ 1639 BFS_Gurtbringer_Sperre 0;
BA_ "GenSigSwitchedByIgnition" SG_ 1639 BFS_Gurtbringer_Sperre 0;
BA_ "GenSigSendType" SG_ 1639 BFS_Klapptisch_offen 3;
BA_ "GenSigSwitchedByIgnition" SG_ 1639 BFS_Klapptisch_offen 0;
BA_ "GenSigSendType" SG_ 1639 BFS_Kollisionsbereich_Windschott 3;
BA_ "GenSigSwitchedByIgnition" SG_ 1639 BFS_Kollisionsbereich_Windschott 0;
BA_ "GenSigSendType" SG_ 1639 BFS_Kollisionsgefahr_Windschott 3;
BA_ "GenSigSwitchedByIgnition" SG_ 1639 BFS_Kollisionsgefahr_Windschott 0;
BA_ "GenSigSendType" SG_ 1639 BFS_KSS_Fahrt_aktiv 3;
BA_ "GenSigSwitchedByIgnition" SG_ 1639 BFS_KSS_Fahrt_aktiv 0;
BA_ "GenSigSendType" SG_ 1639 BFS_KSV_aktiv 3;
BA_ "GenSigSwitchedByIgnition" SG_ 1639 BFS_KSV_aktiv 0;
BA_ "GenSigSendType" SG_ 1639 BFS_Lehne_nicht_verriegelt 3;
BA_ "GenSigSwitchedByIgnition" SG_ 1639 BFS_Lehne_nicht_verriegelt 0;
BA_ "GenSigSendType" SG_ 1639 BFS_LHV_aktiv 3;
BA_ "GenSigSwitchedByIgnition" SG_ 1639 BFS_LHV_aktiv 0;
BA_ "GenSigSendType" SG_ 1639 BFS_LKV_aktiv 3;
BA_ "GenSigSwitchedByIgnition" SG_ 1639 BFS_LKV_aktiv 0;
BA_ "GenSigSendType" SG_ 1639 BFS_LNV_aktiv 3;
BA_ "GenSigSwitchedByIgnition" SG_ 1639 BFS_LNV_aktiv 0;
BA_ "GenSigSendType" SG_ 1639 BFS_LWV_aktiv 3;
BA_ "GenSigSwitchedByIgnition" SG_ 1639 BFS_LWV_aktiv 0;
BA_ "GenSigSendType" SG_ 1639 BFS_MMB_glob_stop 3;
BA_ "GenSigSwitchedByIgnition" SG_ 1639 BFS_MMB_glob_stop 0;
BA_ "GenSigSendType" SG_ 1639 BFS_MMB_lokal_Stop 3;
BA_ "GenSigSwitchedByIgnition" SG_ 1639 BFS_MMB_lokal_Stop 0;
BA_ "GenSigSendType" SG_ 1639 BFS_MMB_storage 3;
BA_ "GenSigSwitchedByIgnition" SG_ 1639 BFS_MMB_storage 0;
BA_ "GenSigSendType" SG_ 1639 BFS_MMB_storage_beep 3;
BA_ "GenSigSwitchedByIgnition" SG_ 1639 BFS_MMB_storage_beep 0;
BA_ "GenSigSendType" SG_ 1639 BFS_MMB_store 3;
BA_ "GenSigSwitchedByIgnition" SG_ 1639 BFS_MMB_store 0;
BA_ "GenSigSendType" SG_ 1639 BFS_MMB_store_LED_on 3;
BA_ "GenSigSwitchedByIgnition" SG_ 1639 BFS_MMB_store_LED_on 0;
BA_ "GenSigSendType" SG_ 1639 BFS_MMB_tast 3;
BA_ "GenSigSwitchedByIgnition" SG_ 1639 BFS_MMB_tast 0;
BA_ "GenSigSendType" SG_ 1639 BFS_MMB_tipp 3;
BA_ "GenSigSwitchedByIgnition" SG_ 1639 BFS_MMB_tipp 0;
BA_ "GenSigSendType" SG_ 1639 BFS_NFA_einfahren 3;
BA_ "GenSigSwitchedByIgnition" SG_ 1639 BFS_NFA_einfahren 0;
BA_ "GenSigSendType" SG_ 1639 BFS_Ruhestellung_Status 3;
BA_ "GenSigSwitchedByIgnition" SG_ 1639 BFS_Ruhestellung_Status 0;
BA_ "GenSigSendType" SG_ 1639 BFS_Seat_Locked 0;
BA_ "GenSigSwitchedByIgnition" SG_ 1639 BFS_Seat_Locked 0;
BA_ "GenSigSendType" SG_ 1639 BFS_SHV_aktiv 3;
BA_ "GenSigSwitchedByIgnition" SG_ 1639 BFS_SHV_aktiv 0;
BA_ "GenSigSendType" SG_ 1639 BFS_Sitzfahrt_aktiv 3;
BA_ "GenSigSwitchedByIgnition" SG_ 1639 BFS_Sitzfahrt_aktiv 0;
BA_ "GenSigSendType" SG_ 1639 BFS_Sitzsym_Fahrt_aktiv 3;
BA_ "GenSigSwitchedByIgnition" SG_ 1639 BFS_Sitzsym_Fahrt_aktiv 0;
BA_ "GenSigSendType" SG_ 1639 BFS_SLV_aktiv 3;
BA_ "GenSigSwitchedByIgnition" SG_ 1639 BFS_SLV_aktiv 0;
BA_ "GenSigSendType" SG_ 1639 BFS_SNV_aktiv 3;
BA_ "GenSigSwitchedByIgnition" SG_ 1639 BFS_SNV_aktiv 0;
BA_ "GenSigSendType" SG_ 1639 BFS_STV_aktiv 3;
BA_ "GenSigSwitchedByIgnition" SG_ 1639 BFS_STV_aktiv 0;
BA_ "GenSigSendType" SG_ 1178 FS_BFS_Fond_Verst_enable 3;
BA_ "GenSigSwitchedByIgnition" SG_ 1178 FS_BFS_Fond_Verst_enable 0;
BA_ "GenSigSendType" SG_ 1178 FS_BFS_KSS_Anfahrt 3;
BA_ "GenSigSwitchedByIgnition" SG_ 1178 FS_BFS_KSS_Anfahrt 0;
BA_ "GenSigSendType" SG_ 1178 FS_BFS_Sitzsym_Anfahrt 3;
BA_ "GenSigSwitchedByIgnition" SG_ 1178 FS_BFS_Sitzsym_Anfahrt 0;
BA_ "GenSigSendType" SG_ 1178 FS_EE_BFS_enable 3;
BA_ "GenSigSwitchedByIgnition" SG_ 1178 FS_EE_BFS_enable 0;
BA_ "GenSigSendType" SG_ 1178 FS_EE_Fond_BFS_enable 3;
BA_ "GenSigSwitchedByIgnition" SG_ 1178 FS_EE_Fond_BFS_enable 0;
BA_ "GenSigSendType" SG_ 1178 FS_EE_Fond_FS_enable 3;
BA_ "GenSigSwitchedByIgnition" SG_ 1178 FS_EE_Fond_FS_enable 0;
BA_ "GenSigSendType" SG_ 1178 FS_Fond_Bed_enable 3;
BA_ "GenSigSwitchedByIgnition" SG_ 1178 FS_Fond_Bed_enable 0;
BA_ "GenSigSendType" SG_ 1178 FS_GHV_aktiv 3;
BA_ "GenSigSwitchedByIgnition" SG_ 1178 FS_GHV_aktiv 0;
BA_ "GenSigSendType" SG_ 1178 FS_Gurtbringer_Sperre 0;
BA_ "GenSigSwitchedByIgnition" SG_ 1178 FS_Gurtbringer_Sperre 0;
BA_ "GenSigSendType" SG_ 1178 FS_Kollisionsbereich_Windschott 3;
BA_ "GenSigSwitchedByIgnition" SG_ 1178 FS_Kollisionsbereich_Windschott 0;
BA_ "GenSigSendType" SG_ 1178 FS_Kollisionsgefahr_Windschott 3;
BA_ "GenSigSwitchedByIgnition" SG_ 1178 FS_Kollisionsgefahr_Windschott 0;
BA_ "GenSigSendType" SG_ 1178 FS_KSV_aktiv 3;
BA_ "GenSigSwitchedByIgnition" SG_ 1178 FS_KSV_aktiv 0;
BA_ "GenSigSendType" SG_ 1178 FS_Lehne_nicht_verriegelt 3;
BA_ "GenSigSwitchedByIgnition" SG_ 1178 FS_Lehne_nicht_verriegelt 0;
BA_ "GenSigSendType" SG_ 1178 FS_LHV_aktiv 3;
BA_ "GenSigSwitchedByIgnition" SG_ 1178 FS_LHV_aktiv 0;
BA_ "GenSigSendType" SG_ 1178 FS_LKV_aktiv 3;
BA_ "GenSigSwitchedByIgnition" SG_ 1178 FS_LKV_aktiv 0;
BA_ "GenSigSendType" SG_ 1178 FS_LNV_aktiv 3;
BA_ "GenSigSwitchedByIgnition" SG_ 1178 FS_LNV_aktiv 0;
BA_ "GenSigSendType" SG_ 1178 FS_LWV_aktiv 3;
BA_ "GenSigSwitchedByIgnition" SG_ 1178 FS_LWV_aktiv 0;
BA_ "GenSigSendType" SG_ 1178 FS_MMB_glob_stop 3;
BA_ "GenSigSwitchedByIgnition" SG_ 1178 FS_MMB_glob_stop 0;
BA_ "GenSigSendType" SG_ 1178 FS_MMB_lokal_Stop 3;
BA_ "GenSigSwitchedByIgnition" SG_ 1178 FS_MMB_lokal_Stop 0;
BA_ "GenSigSendType" SG_ 1178 FS_MMB_storage 3;
BA_ "GenSigSwitchedByIgnition" SG_ 1178 FS_MMB_storage 0;
BA_ "GenSigSendType" SG_ 1178 FS_MMB_storage_beep 3;
BA_ "GenSigSwitchedByIgnition" SG_ 1178 FS_MMB_storage_beep 0;
BA_ "GenSigSendType" SG_ 1178 FS_MMB_store 3;
BA_ "GenSigSwitchedByIgnition" SG_ 1178 FS_MMB_store 0;
BA_ "GenSigSendType" SG_ 1178 FS_MMB_store_LED_on 3;
BA_ "GenSigSwitchedByIgnition" SG_ 1178 FS_MMB_store_LED_on 0;
BA_ "GenSigSendType" SG_ 1178 FS_MMB_tast 3;
BA_ "GenSigSwitchedByIgnition" SG_ 1178 FS_MMB_tast 0;
BA_ "GenSigSendType" SG_ 1178 FS_MMB_tipp 3;
BA_ "GenSigSwitchedByIgnition" SG_ 1178 FS_MMB_tipp 0;
BA_ "GenSigSendType" SG_ 1178 FS_NFA_einfahren 3;
BA_ "GenSigSwitchedByIgnition" SG_ 1178 FS_NFA_einfahren 0;
BA_ "GenSigSendType" SG_ 1178 FS_SHV_aktiv 3;
BA_ "GenSigSwitchedByIgnition" SG_ 1178 FS_SHV_aktiv 0;
BA_ "GenSigSendType" SG_ 1178 FS_Sitzfahrt_aktiv 3;
BA_ "GenSigSwitchedByIgnition" SG_ 1178 FS_Sitzfahrt_aktiv 0;
BA_ "GenSigSendType" SG_ 1178 FS_SLV_aktiv 3;
BA_ "GenSigSwitchedByIgnition" SG_ 1178 FS_SLV_aktiv 0;
BA_ "GenSigSendType" SG_ 1178 FS_SNV_aktiv 3;
BA_ "GenSigSwitchedByIgnition" SG_ 1178 FS_SNV_aktiv 0;
BA_ "GenSigSendType" SG_ 1178 FS_Spezialposition_anfahren 3;
BA_ "GenSigSwitchedByIgnition" SG_ 1178 FS_Spezialposition_anfahren 0;
BA_ "GenSigSendType" SG_ 1178 FS_STV_aktiv 3;
BA_ "GenSigSwitchedByIgnition" SG_ 1178 FS_STV_aktiv 0;
BA_ "GenSigSendType" SG_ 1171 MF_Alarm_Blinker 3;
BA_ "GenSigSwitchedByIgnition" SG_ 1171 MF_Alarm_Blinker 0;
BA_ "GenSigSendType" SG_ 1171 MF_Alarm_Blinkertakt 3;
BA_ "GenSigSwitchedByIgnition" SG_ 1171 MF_Alarm_Blinkertakt 0;
BA_ "GenSigSendType" SG_ 1171 MF_Anlassersperre 3;
BA_ "GenSigSwitchedByIgnition" SG_ 1171 MF_Anlassersperre 0;
BA_ "GenSigSendType" SG_ 1171 MF_Blk_li 3;
BA_ "GenSigSwitchedByIgnition" SG_ 1171 MF_Blk_li 0;
BA_ "GenSigSendType" SG_ 1171 MF_Blk_re 3;
BA_ "GenSigSwitchedByIgnition" SG_ 1171 MF_Blk_re 0;
BA_ "GenSigSendType" SG_ 1171 MF_BT_entriegeln 3;
BA_ "GenSigSwitchedByIgnition" SG_ 1171 MF_BT_entriegeln 0;
BA_ "GenSigSendType" SG_ 1171 MF_BT_verriegeln 3;
BA_ "GenSigSwitchedByIgnition" SG_ 1171 MF_BT_verriegeln 0;
BA_ "GenSigSendType" SG_ 1171 MF_Fahrlicht 3;
BA_ "GenSigSwitchedByIgnition" SG_ 1171 MF_Fahrlicht 0;
BA_ "GenSigSendType" SG_ 1171 MF_Fernbed_ein 3;
BA_ "GenSigSwitchedByIgnition" SG_ 1171 MF_Fernbed_ein 0;
BA_ "GenSigSendType" SG_ 1171 MF_Fernlicht 3;
BA_ "GenSigSwitchedByIgnition" SG_ 1171 MF_Fernlicht 0;
BA_ "GenSigSendType" SG_ 1171 MF_FH_BT_hoch 3;
BA_ "GenSigSwitchedByIgnition" SG_ 1171 MF_FH_BT_hoch 0;
BA_ "GenSigSendType" SG_ 1171 MF_FH_BT_tief 3;
BA_ "GenSigSwitchedByIgnition" SG_ 1171 MF_FH_BT_tief 0;
BA_ "GenSigSendType" SG_ 1171 MF_FH_FT_hoch 3;
BA_ "GenSigSwitchedByIgnition" SG_ 1171 MF_FH_FT_hoch 0;
BA_ "GenSigSendType" SG_ 1171 MF_FH_FT_tief 3;
BA_ "GenSigSwitchedByIgnition" SG_ 1171 MF_FH_FT_tief 0;
BA_ "GenSigSendType" SG_ 1171 MF_Frontintervall 3;
BA_ "GenSigSwitchedByIgnition" SG_ 1171 MF_Frontintervall 0;
BA_ "GenSigSendType" SG_ 1171 MF_Frontwaschen 3;
BA_ "GenSigSwitchedByIgnition" SG_ 1171 MF_Frontwaschen 0;
BA_ "GenSigSendType" SG_ 1171 MF_FT_entriegeln 3;
BA_ "GenSigSwitchedByIgnition" SG_ 1171 MF_FT_entriegeln 0;
BA_ "GenSigSendType" SG_ 1171 MF_FT_verriegeln 3;
BA_ "GenSigSwitchedByIgnition" SG_ 1171 MF_FT_verriegeln 0;
BA_ "GenSigSendType" SG_ 1171 MF_Fussraumbel 3;
BA_ "GenSigSwitchedByIgnition" SG_ 1171 MF_Fussraumbel 0;
BA_ "GenSigSendType" SG_ 1171 MF_HBFS_entriegeln 3;
BA_ "GenSigSwitchedByIgnition" SG_ 1171 MF_HBFS_entriegeln 0;
BA_ "GenSigSendType" SG_ 1171 MF_HBFS_verriegeln 3;
BA_ "GenSigSwitchedByIgnition" SG_ 1171 MF_HBFS_verriegeln 0;
BA_ "GenSigSendType" SG_ 1171 MF_Heckintervall 3;
BA_ "GenSigSwitchedByIgnition" SG_ 1171 MF_Heckintervall 0;
BA_ "GenSigSendType" SG_ 1171 MF_Heckrollo 3;
BA_ "GenSigSwitchedByIgnition" SG_ 1171 MF_Heckrollo 0;
BA_ "GenSigSendType" SG_ 1171 MF_Heckwaschen 3;
BA_ "GenSigSwitchedByIgnition" SG_ 1171 MF_Heckwaschen 0;
BA_ "GenSigSendType" SG_ 1171 MF_HFS_entriegeln 3;
BA_ "GenSigSwitchedByIgnition" SG_ 1171 MF_HFS_entriegeln 0;
BA_ "GenSigSendType" SG_ 1171 MF_HFS_verriegeln 3;
BA_ "GenSigSwitchedByIgnition" SG_ 1171 MF_HFS_verriegeln 0;
BA_ "GenSigSendType" SG_ 1171 MF_Innenraumbel 3;
BA_ "GenSigSwitchedByIgnition" SG_ 1171 MF_Innenraumbel 0;
BA_ "GenSigSendType" SG_ 1171 MF_Innenraumbel_Unterdrueck 3;
BA_ "GenSigSwitchedByIgnition" SG_ 1171 MF_Innenraumbel_Unterdrueck 0;
BA_ "GenSigSendType" SG_ 1171 MF_interm_Fahrlicht 3;
BA_ "GenSigSwitchedByIgnition" SG_ 1171 MF_interm_Fahrlicht 0;
BA_ "GenSigSendType" SG_ 1171 MF_interm_Fernlicht 3;
BA_ "GenSigSwitchedByIgnition" SG_ 1171 MF_interm_Fernlicht 0;
BA_ "GenSigSendType" SG_ 1171 MF_interm_Takt 3;
BA_ "GenSigSwitchedByIgnition" SG_ 1171 MF_interm_Takt 0;
BA_ "GenSigSendType" SG_ 1171 MF_Laderelais 3;
BA_ "GenSigSwitchedByIgnition" SG_ 1171 MF_Laderelais 0;
BA_ "GenSigSendType" SG_ 1171 MF_Lichthupe 3;
BA_ "GenSigSwitchedByIgnition" SG_ 1171 MF_Lichthupe 0;
BA_ "GenSigSendType" SG_ 1171 MF_Motorweiterlauf 3;
BA_ "GenSigSwitchedByIgnition" SG_ 1171 MF_Motorweiterlauf 0;
BA_ "GenSigSendType" SG_ 1171 MF_nachtr_Stopp_Anf 0;
BA_ "GenSigSwitchedByIgnition" SG_ 1171 MF_nachtr_Stopp_Anf 0;
BA_ "GenSigSendType" SG_ 1171 MF_Notstart 3;
BA_ "GenSigSwitchedByIgnition" SG_ 1171 MF_Notstart 0;
BA_ "GenSigSendType" SG_ 1171 MF_Signalhorn 3;
BA_ "GenSigSwitchedByIgnition" SG_ 1171 MF_Signalhorn 0;
BA_ "GenSigSendType" SG_ 1171 MF_Sperre_Rollo 3;
BA_ "GenSigSwitchedByIgnition" SG_ 1171 MF_Sperre_Rollo 0;
BA_ "GenSigSendType" SG_ 1171 MF_Standlicht 3;
BA_ "GenSigSwitchedByIgnition" SG_ 1171 MF_Standlicht 0;
BA_ "GenSigSendType" SG_ 1171 MF_StartStopp_Info 0;
BA_ "GenSigSwitchedByIgnition" SG_ 1171 MF_StartStopp_Info 0;
BA_ "GenSigSendType" SG_ 1171 MF_Summer 3;
BA_ "GenSigSwitchedByIgnition" SG_ 1171 MF_Summer 0;
BA_ "GenSigSendType" SG_ 1171 MF_TFL_Abschaltung 3;
BA_ "GenSigSwitchedByIgnition" SG_ 1171 MF_TFL_Abschaltung 0;
BA_ "GenSigSendType" SG_ 1171 MF_Tippwischen 3;
BA_ "GenSigSwitchedByIgnition" SG_ 1171 MF_Tippwischen 0;
BA_ "GenSigSendType" SG_ 1171 MF_Tuerentriegelung_hinten 3;
BA_ "GenSigSwitchedByIgnition" SG_ 1171 MF_Tuerentriegelung_hinten 0;
BA_ "GenSigSendType" SG_ 1171 MF_Variante 3;
BA_ "GenSigSwitchedByIgnition" SG_ 1171 MF_Variante 0;
BA_ "GenSigSendType" SG_ 1171 MF_Warnblinker 3;
BA_ "GenSigSwitchedByIgnition" SG_ 1171 MF_Warnblinker 0;
BA_ "GenSigSendType" SG_ 1171 MF_Wischerstufe_1 3;
BA_ "GenSigSwitchedByIgnition" SG_ 1171 MF_Wischerstufe_1 0;
BA_ "GenSigSendType" SG_ 1171 MF_Wischerstufe_2 3;
BA_ "GenSigSwitchedByIgnition" SG_ 1171 MF_Wischerstufe_2 0;
BA_ "GenSigSendType" SG_ 1171 MF_ZV_Lock 3;
BA_ "GenSigSwitchedByIgnition" SG_ 1171 MF_ZV_Lock 0;
BA_ "GenSigSendType" SG_ 1171 MFG_01_BZ 0;
BA_ "GenSigFuncType" SG_ 1171 MFG_01_BZ 1;
BA_ "GenSigSwitchedByIgnition" SG_ 1171 MFG_01_BZ 0;
BA_ "GenSigSendType" SG_ 1171 MFG_01_CRC 0;
BA_ "GenSigFuncType" SG_ 1171 MFG_01_CRC 2;
BA_ "GenSigSwitchedByIgnition" SG_ 1171 MFG_01_CRC 0;
BA_ "GenSigSendType" SG_ 817 MFL_Dummy_0_Signal_1 0;
BA_ "GenSigSendType" SG_ 817 MFL_Dummy_0_Signal_2 0;
BA_ "GenSigSendType" SG_ 817 MFL_Dummy_0_Signal_3 0;
BA_ "GenSigSendType" SG_ 817 MFL_ECU_Err 0;
BA_ "GenSigSwitchedByIgnition" SG_ 817 MFL_ECU_Err 0;
BA_ "Fehlerwert" SG_ 817 MFL_ECU_Err 1;
BA_ "GenSigSendType" SG_ 817 MFL_Eventcode_1 0;
BA_ "GenSigSwitchedByIgnition" SG_ 817 MFL_Eventcode_1 0;
BA_ "GenSigSendType" SG_ 817 MFL_Eventcode_2 0;
BA_ "GenSigSwitchedByIgnition" SG_ 817 MFL_Eventcode_2 0;
BA_ "GenSigSendType" SG_ 817 MFL_Lokalaktiv 0;
BA_ "GenSigSendType" SG_ 817 MFL_LR_HZG_Err 0;
BA_ "Fehlerwert" SG_ 817 MFL_LR_HZG_Err 1;
BA_ "GenSigSendType" SG_ 817 MFL_LR_HZG_Status 0;
BA_ "GenSigSendType" SG_ 817 MFL_M_Taste 0;
BA_ "GenSigSendType" SG_ 817 MFL_Marke 0;
BA_ "GenSigFuncType" SG_ 817 MFL_Marke 8;
BA_ "GenSigSendType" SG_ 817 MFL_Paddle_Verbau 0;
BA_ "GenSigSendType" SG_ 817 MFL_Response_Err 0;
BA_ "Fehlerwert" SG_ 817 MFL_Response_Err 1;
BA_ "GenSigSendType" SG_ 817 MFL_SatModul_links_Err 0;
BA_ "GenSigFuncType" SG_ 817 MFL_SatModul_links_Err 5;
BA_ "Fehlerwert" SG_ 817 MFL_SatModul_links_Err 1;
BA_ "GenSigSendType" SG_ 817 MFL_SatModul_rechts_Err 0;
BA_ "GenSigFuncType" SG_ 817 MFL_SatModul_rechts_Err 5;
BA_ "Fehlerwert" SG_ 817 MFL_SatModul_rechts_Err 1;
BA_ "GenSigSendType" SG_ 817 MFL_Signalhorn 5;
BA_ "GenSigSwitchedByIgnition" SG_ 817 MFL_Signalhorn 0;
BA_ "GenSigSendType" SG_ 817 MFL_Signalhorn_Err 0;
BA_ "GenSigSwitchedByIgnition" SG_ 817 MFL_Signalhorn_Err 0;
BA_ "Fehlerwert" SG_ 817 MFL_Signalhorn_Err 1;
BA_ "GenSigSendType" SG_ 817 MFL_Taste_links_Err 0;
BA_ "GenSigSwitchedByIgnition" SG_ 817 MFL_Taste_links_Err 0;
BA_ "Fehlerwert" SG_ 817 MFL_Taste_links_Err 1;
BA_ "GenSigSendType" SG_ 817 MFL_Taste_rechts_Err 0;
BA_ "GenSigSwitchedByIgnition" SG_ 817 MFL_Taste_rechts_Err 0;
BA_ "Fehlerwert" SG_ 817 MFL_Taste_rechts_Err 1;
BA_ "GenSigSendType" SG_ 817 MFL_Tastencode_1 0;
BA_ "GenSigSwitchedByIgnition" SG_ 817 MFL_Tastencode_1 0;
BA_ "GenSigSendType" SG_ 817 MFL_Tastencode_2 0;
BA_ "GenSigSwitchedByIgnition" SG_ 817 MFL_Tastencode_2 0;
BA_ "GenSigSendType" SG_ 817 MFL_Tip_Down 5;
BA_ "GenSigSendType" SG_ 817 MFL_Tip_links_Err 0;
BA_ "GenSigSwitchedByIgnition" SG_ 817 MFL_Tip_links_Err 0;
BA_ "Fehlerwert" SG_ 817 MFL_Tip_links_Err 1;
BA_ "GenSigSendType" SG_ 817 MFL_Tip_rechts_Err 0;
BA_ "GenSigSwitchedByIgnition" SG_ 817 MFL_Tip_rechts_Err 0;
BA_ "Fehlerwert" SG_ 817 MFL_Tip_rechts_Err 1;
BA_ "GenSigSendType" SG_ 817 MFL_Tip_Up 5;
BA_ "GenSigSendType" SG_ 817 MFL_Toggle 0;
BA_ "GenSigSwitchedByIgnition" SG_ 817 MFL_Toggle 0;
BA_ "GenSigSendType" SG_ 817 MFL_Variante 0;
BA_ "GenSigFuncType" SG_ 817 MFL_Variante 8;
BA_ "GenSigSendType" SG_ 817 MFL_Zaehler 0;
BA_ "GenSigSwitchedByIgnition" SG_ 817 MFL_Zaehler 0;
BA_ "GenSigSendType" SG_ 1600 MO_Absperrventil_oeffnen 0;
BA_ "GenSigSwitchedByIgnition" SG_ 1600 MO_Absperrventil_oeffnen 0;
BA_ "GenSigSendType" SG_ 1600 MO_aktives_Getriebeheizen 0;
BA_ "GenSigSwitchedByIgnition" SG_ 1600 MO_aktives_Getriebeheizen 0;
BA_ "GenSigSendType" SG_ 1600 MO_Ansaugluft_Temp 0;
BA_ "GenSigStartValue" SG_ 1600 MO_Ansaugluft_Temp 254;
BA_ "GenSigSwitchedByIgnition" SG_ 1600 MO_Ansaugluft_Temp 0;
BA_ "Fehlerwert" SG_ 1600 MO_Ansaugluft_Temp 255;
BA_ "GenSigSendType" SG_ 1600 MO_Getriebe_kuehlen 0;
BA_ "GenSigSwitchedByIgnition" SG_ 1600 MO_Getriebe_kuehlen 0;
BA_ "GenSigSendType" SG_ 1600 MO_Heizungspumpenansteuerung 0;
BA_ "GenSigStartValue" SG_ 1600 MO_Heizungspumpenansteuerung 14;
BA_ "GenSigSwitchedByIgnition" SG_ 1600 MO_Heizungspumpenansteuerung 0;
BA_ "Fehlerwert" SG_ 1600 MO_Heizungspumpenansteuerung 13;
BA_ "GenSigSendType" SG_ 1600 MO_Hoeheninfo 0;
BA_ "GenSigSwitchedByIgnition" SG_ 1600 MO_Hoeheninfo 0;
BA_ "Fehlerwert" SG_ 1600 MO_Hoeheninfo 255;
BA_ "GenSigSendType" SG_ 1600 MO_HYB_Fehler_HV_Netz 0;
BA_ "GenSigSwitchedByIgnition" SG_ 1600 MO_HYB_Fehler_HV_Netz 0;
BA_ "GenSigSendType" SG_ 1600 MO_Kennfeldk 0;
BA_ "GenSigSwitchedByIgnition" SG_ 1600 MO_Kennfeldk 0;
BA_ "GenSigSendType" SG_ 1600 MO_KL15_Abschaltempfehlung 0;
BA_ "GenSigSwitchedByIgnition" SG_ 1600 MO_KL15_Abschaltempfehlung 0;
BA_ "GenSigSendType" SG_ 1600 MO_Kuehlmittel_Temp 0;
BA_ "GenSigStartValue" SG_ 1600 MO_Kuehlmittel_Temp 254;
BA_ "GenSigSwitchedByIgnition" SG_ 1600 MO_Kuehlmittel_Temp 0;
BA_ "Fehlerwert" SG_ 1600 MO_Kuehlmittel_Temp 255;
BA_ "GenSigSendType" SG_ 1600 MO_Mom_Traegheit_02 0;
BA_ "GenSigSwitchedByIgnition" SG_ 1600 MO_Mom_Traegheit_02 0;
BA_ "GenSigSendType" SG_ 1600 MO_Nachlaufzeit_Heizungspumpe 0;
BA_ "GenSigSwitchedByIgnition" SG_ 1600 MO_Nachlaufzeit_Heizungspumpe 0;
BA_ "GenSigSendType" SG_ 1600 MO_Oel_Temp 0;
BA_ "GenSigStartValue" SG_ 1600 MO_Oel_Temp 254;
BA_ "GenSigSwitchedByIgnition" SG_ 1600 MO_Oel_Temp 0;
BA_ "Fehlerwert" SG_ 1600 MO_Oel_Temp 255;
BA_ "GenSigSendType" SG_ 1600 MO_QBit_Ansaugluft_Temp 0;
BA_ "GenSigStartValue" SG_ 1600 MO_QBit_Ansaugluft_Temp 1;
BA_ "GenSigSwitchedByIgnition" SG_ 1600 MO_QBit_Ansaugluft_Temp 0;
BA_ "GenSigSendType" SG_ 1600 MO_QBit_Hoeheninfo 0;
BA_ "GenSigStartValue" SG_ 1600 MO_QBit_Hoeheninfo 1;
BA_ "GenSigSwitchedByIgnition" SG_ 1600 MO_QBit_Hoeheninfo 0;
BA_ "GenSigSendType" SG_ 1600 MO_QBit_Kuehlmittel_Temp 0;
BA_ "GenSigStartValue" SG_ 1600 MO_QBit_Kuehlmittel_Temp 1;
BA_ "GenSigSwitchedByIgnition" SG_ 1600 MO_QBit_Kuehlmittel_Temp 0;
BA_ "GenSigSendType" SG_ 1600 MO_QBit_Oel_Temp 0;
BA_ "GenSigStartValue" SG_ 1600 MO_QBit_Oel_Temp 1;
BA_ "GenSigSwitchedByIgnition" SG_ 1600 MO_QBit_Oel_Temp 0;
BA_ "GenSigSendType" SG_ 1600 MO_SpannungsAnf 0;
BA_ "GenSigSwitchedByIgnition" SG_ 1600 MO_SpannungsAnf 0;
BA_ "GenSigSendType" SG_ 1600 MO_Versionsinfo_02 0;
BA_ "GenSigSwitchedByIgnition" SG_ 1600 MO_Versionsinfo_02 0;
BA_ "GenSigSendType" SG_ 1607 MO_CO2_Faktor 0;
BA_ "GenSigSwitchedByIgnition" SG_ 1607 MO_CO2_Faktor 0;
BA_ "Fehlerwert" SG_ 1607 MO_CO2_Faktor 4095;
BA_ "GenSigSendType" SG_ 1607 MO_E85_Sensor 0;
BA_ "GenSigStartValue" SG_ 1607 MO_E85_Sensor 14;
BA_ "GenSigSwitchedByIgnition" SG_ 1607 MO_E85_Sensor 0;
BA_ "Fehlerwert" SG_ 1607 MO_E85_Sensor 15;
BA_ "GenSigSendType" SG_ 1607 MO_Ethanol_Spuelhinweis 0;
BA_ "GenSigSwitchedByIgnition" SG_ 1607 MO_Ethanol_Spuelhinweis 0;
BA_ "GenSigSendType" SG_ 1607 MO_ITM_Kuehlmittel_Temp 0;
BA_ "GenSigStartValue" SG_ 1607 MO_ITM_Kuehlmittel_Temp 1;
BA_ "GenSigSwitchedByIgnition" SG_ 1607 MO_ITM_Kuehlmittel_Temp 0;
BA_ "Fehlerwert" SG_ 1607 MO_ITM_Kuehlmittel_Temp 2;
BA_ "GenSigSendType" SG_ 1607 MO_Kraftstofffilter_Wasser 0;
BA_ "GenSigSwitchedByIgnition" SG_ 1607 MO_Kraftstofffilter_Wasser 0;
BA_ "GenSigSwitchedByIgnition" SG_ 1607 MO_MKB_01 0;
BA_ "GenSigSwitchedByIgnition" SG_ 1607 MO_MKB_02 0;
BA_ "GenSigSwitchedByIgnition" SG_ 1607 MO_MKB_03 0;
BA_ "GenSigSwitchedByIgnition" SG_ 1607 MO_MKB_04 0;
BA_ "GenSigSendType" SG_ 1607 MO_MKB_MUX 0;
BA_ "GenSigSwitchedByIgnition" SG_ 1607 MO_MKB_MUX 0;
BA_ "GenSigSendType" SG_ 1607 SCR_Akustik 0;
BA_ "GenSigSwitchedByIgnition" SG_ 1607 SCR_Akustik 0;
BA_ "GenSigSendType" SG_ 1607 SCR_Anz_Motorstarts 0;
BA_ "GenSigStartValue" SG_ 1607 SCR_Anz_Motorstarts 15;
BA_ "GenSigSwitchedByIgnition" SG_ 1607 SCR_Anz_Motorstarts 0;
BA_ "GenSigSendType" SG_ 1607 SCR_Inducement_Strategie 0;
BA_ "GenSigSwitchedByIgnition" SG_ 1607 SCR_Inducement_Strategie 0;
BA_ "GenSigSendType" SG_ 1607 SCR_Reichweite 0;
BA_ "GenSigStartValue" SG_ 1607 SCR_Reichweite 32767;
BA_ "GenSigSwitchedByIgnition" SG_ 1607 SCR_Reichweite 0;
BA_ "GenSigSendType" SG_ 1607 SCR_Systemfehler 0;
BA_ "GenSigSwitchedByIgnition" SG_ 1607 SCR_Systemfehler 0;
BA_ "GenSigSendType" SG_ 1607 SCR_Text 0;
BA_ "GenSigSwitchedByIgnition" SG_ 1607 SCR_Text 0;
BA_ "GenSigSendType" SG_ 1607 SCR_verbaut 0;
BA_ "GenSigFuncType" SG_ 1607 SCR_verbaut 8;
BA_ "GenSigSwitchedByIgnition" SG_ 1607 SCR_verbaut 0;
BA_ "GenSigSendType" SG_ 1607 SCR_Warnstufe_1 0;
BA_ "GenSigSwitchedByIgnition" SG_ 1607 SCR_Warnstufe_1 0;
BA_ "GenSigSendType" SG_ 1607 SCR_Warnstufe_2 0;
BA_ "GenSigSwitchedByIgnition" SG_ 1607 SCR_Warnstufe_2 0;
BA_ "GenSigSendType" SG_ 168 MO_Drehzahl_01 0;
BA_ "GenSigSwitchedByIgnition" SG_ 168 MO_Drehzahl_01 0;
BA_ "GenSigSendType" SG_ 168 MO_Mom_Begr_dyn 0;
BA_ "GenSigStartValue" SG_ 168 MO_Mom_Begr_dyn 1022;
BA_ "GenSigSwitchedByIgnition" SG_ 168 MO_Mom_Begr_dyn 0;
BA_ "GenSigSendType" SG_ 168 MO_Mom_Begr_stat 0;
BA_ "GenSigStartValue" SG_ 168 MO_Mom_Begr_stat 510;
BA_ "GenSigSwitchedByIgnition" SG_ 168 MO_Mom_Begr_stat 0;
BA_ "GenSigSendType" SG_ 168 MO_Mom_neg_verfuegbar 0;
BA_ "GenSigStartValue" SG_ 168 MO_Mom_neg_verfuegbar 510;
BA_ "GenSigSwitchedByIgnition" SG_ 168 MO_Mom_neg_verfuegbar 0;
BA_ "Fehlerwert" SG_ 168 MO_Mom_neg_verfuegbar 511;
BA_ "GenSigSendType" SG_ 168 MO_Momentenintegral_02 0;
BA_ "GenSigSwitchedByIgnition" SG_ 168 MO_Momentenintegral_02 0;
BA_ "GenSigSendType" SG_ 168 MO_QBit_Drehzahl_01 0;
BA_ "GenSigStartValue" SG_ 168 MO_QBit_Drehzahl_01 1;
BA_ "GenSigSwitchedByIgnition" SG_ 168 MO_QBit_Drehzahl_01 0;
BA_ "GenSigSendType" SG_ 168 Motor_12_BZ 0;
BA_ "GenSigFuncType" SG_ 168 Motor_12_BZ 1;
BA_ "GenSigSwitchedByIgnition" SG_ 168 Motor_12_BZ 0;
BA_ "GenSigSendType" SG_ 168 Motor_12_CRC 0;
BA_ "GenSigFuncType" SG_ 168 Motor_12_CRC 2;
BA_ "GenSigSwitchedByIgnition" SG_ 168 Motor_12_CRC 0;
BA_ "GenSigSendType" SG_ 958 MO_Aussp_Anlass 3;
BA_ "GenSigSwitchedByIgnition" SG_ 958 MO_Aussp_Anlass 0;
BA_ "GenSigSendType" SG_ 958 MO_BKV_Unterdruckwarnung 0;
BA_ "GenSigSwitchedByIgnition" SG_ 958 MO_BKV_Unterdruckwarnung 0;
BA_ "GenSigSendType" SG_ 958 MO_BLS 3;
BA_ "GenSigSwitchedByIgnition" SG_ 958 MO_BLS 0;
BA_ "GenSigSendType" SG_ 958 MO_BMS_NV_Anf_stuetzen 3;
BA_ "GenSigSwitchedByIgnition" SG_ 958 MO_BMS_NV_Anf_stuetzen 0;
BA_ "GenSigSendType" SG_ 958 MO_EKlKomLeiRed 0;
BA_ "GenSigSwitchedByIgnition" SG_ 958 MO_EKlKomLeiRed 0;
BA_ "GenSigSendType" SG_ 958 MO_Ext_E_Fahrt_aktiv 3;
BA_ "NWM-WakeupAllowed" SG_ 958 MO_Ext_E_Fahrt_aktiv 1;
BA_ "GenSigSwitchedByIgnition" SG_ 958 MO_Ext_E_Fahrt_aktiv 0;
BA_ "GenSigSendType" SG_ 958 MO_Fahrer_bremst 3;
BA_ "GenSigSwitchedByIgnition" SG_ 958 MO_Fahrer_bremst 0;
BA_ "GenSigSendType" SG_ 958 MO_FMAus_aktiv 3;
BA_ "GenSigSwitchedByIgnition" SG_ 958 MO_FMAus_aktiv 0;
BA_ "GenSigSendType" SG_ 958 MO_FMAus_Startvariante 3;
BA_ "GenSigSwitchedByIgnition" SG_ 958 MO_FMAus_Startvariante 0;
BA_ "GenSigSendType" SG_ 958 MO_Freig_Anlass 3;
BA_ "GenSigSwitchedByIgnition" SG_ 958 MO_Freig_Anlass 0;
BA_ "GenSigSendType" SG_ 958 MO_Freig_Reku 0;
BA_ "GenSigSwitchedByIgnition" SG_ 958 MO_Freig_Reku 0;
BA_ "GenSigSendType" SG_ 958 MO_Freigabe_Segeln 0;
BA_ "GenSigSwitchedByIgnition" SG_ 958 MO_Freigabe_Segeln 0;
BA_ "GenSigSendType" SG_ 958 MO_Gangposition 3;
BA_ "GenSigStartValue" SG_ 958 MO_Gangposition 14;
BA_ "GenSigSwitchedByIgnition" SG_ 958 MO_Gangposition 0;
BA_ "Fehlerwert" SG_ 958 MO_Gangposition 15;
BA_ "GenSigSendType" SG_ 958 MO_Handshake_STH 0;
BA_ "GenSigSwitchedByIgnition" SG_ 958 MO_Handshake_STH 0;
BA_ "GenSigSendType" SG_ 958 MO_HYB_Fahrbereitschaft 0;
BA_ "GenSigSwitchedByIgnition" SG_ 958 MO_HYB_Fahrbereitschaft 0;
BA_ "GenSigSendType" SG_ 958 MO_HYB_VM_aktiv 3;
BA_ "GenSigSwitchedByIgnition" SG_ 958 MO_HYB_VM_aktiv 0;
BA_ "GenSigSendType" SG_ 958 MO_Interlock 3;
BA_ "GenSigSwitchedByIgnition" SG_ 958 MO_Interlock 0;
BA_ "GenSigSendType" SG_ 958 MO_Kickdown 3;
BA_ "GenSigSwitchedByIgnition" SG_ 958 MO_Kickdown 0;
BA_ "GenSigSendType" SG_ 958 MO_Kl_50 3;
BA_ "GenSigSwitchedByIgnition" SG_ 958 MO_Kl_50 0;
BA_ "GenSigSendType" SG_ 958 MO_Kl_75 3;
BA_ "GenSigSwitchedByIgnition" SG_ 958 MO_Kl_75 0;
BA_ "GenSigSendType" SG_ 958 MO_Klima_Eingr 0;
BA_ "GenSigSwitchedByIgnition" SG_ 958 MO_Klima_Eingr 0;
BA_ "GenSigSendType" SG_ 958 MO_KomFehler_ESP 3;
BA_ "GenSigSwitchedByIgnition" SG_ 958 MO_KomFehler_ESP 0;
BA_ "Fehlerwert" SG_ 958 MO_KomFehler_ESP 1;
BA_ "GenSigSendType" SG_ 958 MO_Konsistenz_Bremsped 3;
BA_ "GenSigSwitchedByIgnition" SG_ 958 MO_Konsistenz_Bremsped 0;
BA_ "GenSigSendType" SG_ 958 MO_Kuppl_schalter 3;
BA_ "GenSigSwitchedByIgnition" SG_ 958 MO_Kuppl_schalter 0;
BA_ "GenSigSendType" SG_ 958 MO_Motor_laeuft 3;
BA_ "GenSigSwitchedByIgnition" SG_ 958 MO_Motor_laeuft 0;
BA_ "GenSigSendType" SG_ 958 MO_PTC_Status 0;
BA_ "GenSigSwitchedByIgnition" SG_ 958 MO_PTC_Status 0;
BA_ "GenSigSendType" SG_ 958 MO_QBit_Fahrer_bremst 3;
BA_ "GenSigStartValue" SG_ 958 MO_QBit_Fahrer_bremst 1;
BA_ "GenSigSwitchedByIgnition" SG_ 958 MO_QBit_Fahrer_bremst 0;
BA_ "GenSigSendType" SG_ 958 MO_QBit_Gangposition 3;
BA_ "GenSigStartValue" SG_ 958 MO_QBit_Gangposition 1;
BA_ "GenSigSwitchedByIgnition" SG_ 958 MO_QBit_Gangposition 0;
BA_ "GenSigSendType" SG_ 958 MO_QBit_KL_75 3;
BA_ "GenSigStartValue" SG_ 958 MO_QBit_KL_75 1;
BA_ "GenSigSwitchedByIgnition" SG_ 958 MO_QBit_KL_75 0;
BA_ "GenSigSendType" SG_ 958 MO_Remotestart_Betrieb 3;
BA_ "GenSigSwitchedByIgnition" SG_ 958 MO_Remotestart_Betrieb 0;
BA_ "GenSigSendType" SG_ 958 MO_Remotestart_moeglich 0;
BA_ "GenSigSwitchedByIgnition" SG_ 958 MO_Remotestart_moeglich 0;
BA_ "GenSigSendType" SG_ 958 MO_Signalquelle_Gangposition 0;
BA_ "GenSigSwitchedByIgnition" SG_ 958 MO_Signalquelle_Gangposition 0;
BA_ "GenSigSendType" SG_ 958 MO_StartStopp_Fahrerwunsch 0;
BA_ "GenSigSwitchedByIgnition" SG_ 958 MO_StartStopp_Fahrerwunsch 0;
BA_ "GenSigSendType" SG_ 958 MO_StartStopp_Motorstopp 3;
BA_ "GenSigSwitchedByIgnition" SG_ 958 MO_StartStopp_Motorstopp 0;
BA_ "GenSigSendType" SG_ 958 MO_StartStopp_Status 3;
BA_ "GenSigSwitchedByIgnition" SG_ 958 MO_StartStopp_Status 0;
BA_ "GenSigSendType" SG_ 958 MO_StartStopp_Wiederstart 3;
BA_ "GenSigSwitchedByIgnition" SG_ 958 MO_StartStopp_Wiederstart 0;
BA_ "GenSigSendType" SG_ 958 MO_StartVorauss_erfuellt 3;
BA_ "GenSigStartValue" SG_ 958 MO_StartVorauss_erfuellt 1;
BA_ "GenSigSwitchedByIgnition" SG_ 958 MO_StartVorauss_erfuellt 0;
BA_ "GenSigSendType" SG_ 958 MO_Text_Geschw_red 0;
BA_ "GenSigSwitchedByIgnition" SG_ 958 MO_Text_Geschw_red 0;
BA_ "GenSigSendType" SG_ 958 MO_Zylinderabschaltung 3;
BA_ "GenSigSwitchedByIgnition" SG_ 958 MO_Zylinderabschaltung 0;
BA_ "GenSigSendType" SG_ 958 Motor_14_BZ 0;
BA_ "GenSigFuncType" SG_ 958 Motor_14_BZ 1;
BA_ "GenSigSwitchedByIgnition" SG_ 958 Motor_14_BZ 0;
BA_ "GenSigSendType" SG_ 958 Motor_14_CRC 0;
BA_ "GenSigFuncType" SG_ 958 Motor_14_CRC 2;
BA_ "GenSigSwitchedByIgnition" SG_ 958 Motor_14_CRC 0;
BA_ "GenSigSendType" SG_ 1631 MO_Anzeige_Kaltleuchte 0;
BA_ "GenSigSwitchedByIgnition" SG_ 1631 MO_Anzeige_Kaltleuchte 0;
BA_ "GenSigSendType" SG_ 1631 MO_DPF_reg 0;
BA_ "GenSigSwitchedByIgnition" SG_ 1631 MO_DPF_reg 0;
BA_ "GenSigSendType" SG_ 1631 MO_Energieinhalt_BMS 0;
BA_ "GenSigStartValue" SG_ 1631 MO_Energieinhalt_BMS 4094;
BA_ "GenSigSwitchedByIgnition" SG_ 1631 MO_Energieinhalt_BMS 0;
BA_ "Fehlerwert" SG_ 1631 MO_Energieinhalt_BMS 4095;
BA_ "GenSigSendType" SG_ 1631 MO_Heizstrom_EKAT 0;
BA_ "GenSigSwitchedByIgnition" SG_ 1631 MO_Heizstrom_EKAT 0;
BA_ "Fehlerwert" SG_ 1631 MO_Heizstrom_EKAT 127;
BA_ "GenSigSendType" SG_ 1631 MO_Heizstrom_SCR 0;
BA_ "GenSigSwitchedByIgnition" SG_ 1631 MO_Heizstrom_SCR 0;
BA_ "Fehlerwert" SG_ 1631 MO_Heizstrom_SCR 63;
BA_ "GenSigSendType" SG_ 1631 MO_P_Generator_ungefiltert_Anf 0;
BA_ "GenSigSwitchedByIgnition" SG_ 1631 MO_P_Generator_ungefiltert_Anf 0;
BA_ "GenSigSendType" SG_ 1631 MO_SpannungsAnf_02 0;
BA_ "GenSigSwitchedByIgnition" SG_ 1631 MO_SpannungsAnf_02 0;
BA_ "GenSigSendType" SG_ 1631 TSK_Fahrzeugmasse_02 0;
BA_ "GenSigSwitchedByIgnition" SG_ 1631 TSK_Fahrzeugmasse_02 0;
BA_ "Fehlerwert" SG_ 1631 TSK_Fahrzeugmasse_02 255;
BA_ "GenSigSendType" SG_ 1631 TSK_Getriebeinfo 0;
BA_ "GenSigSwitchedByIgnition" SG_ 1631 TSK_Getriebeinfo 0;
BA_ "GenSigSendType" SG_ 1631 TSK_Grundmasse 0;
BA_ "GenSigSwitchedByIgnition" SG_ 1631 TSK_Grundmasse 0;
BA_ "GenSigSendType" SG_ 1631 TSK_QBit_Fahrzeugmasse 0;
BA_ "GenSigStartValue" SG_ 1631 TSK_QBit_Fahrzeugmasse 1;
BA_ "GenSigSwitchedByIgnition" SG_ 1631 TSK_QBit_Fahrzeugmasse 0;
BA_ "GenSigSendType" SG_ 1631 TSK_QBit_Steigung 0;
BA_ "GenSigStartValue" SG_ 1631 TSK_QBit_Steigung 1;
BA_ "GenSigSwitchedByIgnition" SG_ 1631 TSK_QBit_Steigung 0;
BA_ "GenSigSendType" SG_ 1631 TSK_Steigung_02 0;
BA_ "GenSigSwitchedByIgnition" SG_ 1631 TSK_Steigung_02 0;
BA_ "Fehlerwert" SG_ 1631 TSK_Steigung_02 255;
BA_ "GenSigSendType" SG_ 812 MO_BZS_Charisma_FahrPr 3;
BA_ "GenSigSwitchedByIgnition" SG_ 812 MO_BZS_Charisma_FahrPr 0;
BA_ "GenSigSendType" SG_ 812 MO_BZS_Charisma_Status 0;
BA_ "GenSigSwitchedByIgnition" SG_ 812 MO_BZS_Charisma_Status 0;
BA_ "GenSigSendType" SG_ 812 MO_Charisma_FahrPr 0;
BA_ "GenSigSwitchedByIgnition" SG_ 812 MO_Charisma_FahrPr 0;
BA_ "GenSigSendType" SG_ 812 MO_Charisma_Status 0;
BA_ "GenSigSwitchedByIgnition" SG_ 812 MO_Charisma_Status 0;
BA_ "GenSigSendType" SG_ 812 MO_Drehzahlbeeinflussung 0;
BA_ "GenSigSwitchedByIgnition" SG_ 812 MO_Drehzahlbeeinflussung 0;
BA_ "GenSigSendType" SG_ 812 MO_Luftpfad_aktiv 0;
BA_ "GenSigSwitchedByIgnition" SG_ 812 MO_Luftpfad_aktiv 0;
BA_ "GenSigSendType" SG_ 812 MO_MAX_Wunschdrehzahl 3;
BA_ "GenSigSwitchedByIgnition" SG_ 812 MO_MAX_Wunschdrehzahl 0;
BA_ "GenSigSendType" SG_ 812 MO_MIN_Wunschdrehzahl 0;
BA_ "GenSigSwitchedByIgnition" SG_ 812 MO_MIN_Wunschdrehzahl 0;
BA_ "GenSigSendType" SG_ 812 MO_NGS_Position 0;
BA_ "GenSigSwitchedByIgnition" SG_ 812 MO_NGS_Position 0;
BA_ "GenSigSendType" SG_ 812 MO_NGS_Status 0;
BA_ "GenSigSwitchedByIgnition" SG_ 812 MO_NGS_Status 0;
BA_ "Fehlerwert" SG_ 812 MO_NGS_Status 3;
BA_ "GenSigSendType" SG_ 812 MO_Prio_MAX_Wunschdrehzahl 3;
BA_ "GenSigSwitchedByIgnition" SG_ 812 MO_Prio_MAX_Wunschdrehzahl 0;
BA_ "GenSigSendType" SG_ 812 MO_Prio_MIN_Wunschdrehzahl 0;
BA_ "GenSigSwitchedByIgnition" SG_ 812 MO_Prio_MIN_Wunschdrehzahl 0;
BA_ "GenSigSendType" SG_ 812 MO_Rampenzeit_Generator_Anf 0;
BA_ "GenSigStartValue" SG_ 812 MO_Rampenzeit_Generator_Anf 15;
BA_ "GenSigSwitchedByIgnition" SG_ 812 MO_Rampenzeit_Generator_Anf 0;
BA_ "GenSigSendType" SG_ 812 MO_Sperrung_FahrPr_BZS 0;
BA_ "GenSigSwitchedByIgnition" SG_ 812 MO_Sperrung_FahrPr_BZS 0;
BA_ "GenSigSendType" SG_ 812 MO_StSt_Charisma_FahrPr 0;
BA_ "GenSigSwitchedByIgnition" SG_ 812 MO_StSt_Charisma_FahrPr 0;
BA_ "GenSigSendType" SG_ 812 MO_StSt_Charisma_Status 0;
BA_ "GenSigSwitchedByIgnition" SG_ 812 MO_StSt_Charisma_Status 0;
BA_ "GenSigSendType" SG_ 812 MO_v_Begrenz_Aktivierbar 0;
BA_ "GenSigSwitchedByIgnition" SG_ 812 MO_v_Begrenz_Aktivierbar 0;
BA_ "GenSigSendType" SG_ 812 MO_v_Begrenzung_Niveau 0;
BA_ "GenSigSwitchedByIgnition" SG_ 812 MO_v_Begrenzung_Niveau 0;
BA_REL_ "GenSigTimeoutTime" BU_SG_REL_ BCM1 SG_ 822 LR_HZG_Taster_on_off 1200;
BA_REL_ "GenSigTimeoutTime" BU_SG_REL_ BCM1 SG_ 2527679652 LS1_Reinigung_Anf 5000;
BA_REL_ "GenSigTimeoutTime" BU_SG_REL_ BCM1 SG_ 1153 MIB_Tongenerator_PH_verfuegbar 5000;
BA_REL_ "GenSigTimeoutTime" BU_SG_REL_ BCM1 SG_ 1153 ZR_Sta_Inszenierung 5000;
BA_REL_ "GenSigTimeoutTime" BU_SG_REL_ BCM1 SG_ 1639 BFS_MMB_storage 1000;
BA_REL_ "GenSigTimeoutTime" BU_SG_REL_ BCM1 SG_ 1639 BFS_MMB_tipp 1000;
BA_REL_ "GenSigTimeoutTime" BU_SG_REL_ BCM1 SG_ 1639 BFS_MMB_tast 1000;
BA_REL_ "GenSigTimeoutTime" BU_SG_REL_ BCM1 SG_ 1639 BFS_MMB_glob_stop 1000;
BA_REL_ "GenSigTimeoutTime" BU_SG_REL_ BCM1 SG_ 1639 BFS_FSV_ausgeklappt 1000;
BA_REL_ "GenSigTimeoutTime" BU_SG_REL_ BCM1 SG_ 1178 FS_Sitzfahrt_aktiv 1000;
BA_REL_ "GenSigTimeoutTime" BU_SG_REL_ BCM1 SG_ 1178 FS_MMB_storage 1000;
BA_REL_ "GenSigTimeoutTime" BU_SG_REL_ BCM1 SG_ 1178 FS_MMB_tipp 1000;
BA_REL_ "GenSigTimeoutTime" BU_SG_REL_ BCM1 SG_ 1178 FS_MMB_tast 1000;
BA_REL_ "GenSigTimeoutTime" BU_SG_REL_ BCM1 SG_ 1178 FS_MMB_store 1000;
BA_REL_ "GenSigTimeoutTime" BU_SG_REL_ BCM1 SG_ 1178 FS_MMB_glob_stop 1000;
BA_REL_ "GenSigTimeoutTime" BU_SG_REL_ BCM1 SG_ 1171 MFG_01_CRC 2000;
BA_REL_ "GenSigTimeoutTime" BU_SG_REL_ BCM1 SG_ 1171 MFG_01_BZ 2000;
BA_REL_ "GenSigTimeoutTime" BU_SG_REL_ BCM1 SG_ 1171 MF_Variante 2000;
BA_REL_ "GenSigTimeoutTime" BU_SG_REL_ BCM1 SG_ 1171 MF_Fernbed_ein 2000;
BA_REL_ "GenSigTimeoutTime" BU_SG_REL_ BCM1 SG_ 1171 MF_Standlicht 2000;
BA_REL_ "GenSigTimeoutTime" BU_SG_REL_ BCM1 SG_ 1171 MF_Fahrlicht 2000;
BA_REL_ "GenSigTimeoutTime" BU_SG_REL_ BCM1 SG_ 1171 MF_interm_Fernlicht 2000;
BA_REL_ "GenSigTimeoutTime" BU_SG_REL_ BCM1 SG_ 1171 MF_Warnblinker 2000;
BA_REL_ "GenSigTimeoutTime" BU_SG_REL_ BCM1 SG_ 1171 MF_Fussraumbel 2000;
BA_REL_ "GenSigTimeoutTime" BU_SG_REL_ BCM1 SG_ 1171 MF_Innenraumbel 2000;
BA_REL_ "GenSigTimeoutTime" BU_SG_REL_ BCM1 SG_ 1171 MF_Innenraumbel_Unterdrueck 2000;
BA_REL_ "GenSigTimeoutTime" BU_SG_REL_ BCM1 SG_ 1171 MF_Lichthupe 2000;
BA_REL_ "GenSigTimeoutTime" BU_SG_REL_ BCM1 SG_ 1171 MF_Fernlicht 2000;
BA_REL_ "GenSigTimeoutTime" BU_SG_REL_ BCM1 SG_ 1171 MF_Tippwischen 2000;
BA_REL_ "GenSigTimeoutTime" BU_SG_REL_ BCM1 SG_ 1171 MF_Frontintervall 2000;
BA_REL_ "GenSigTimeoutTime" BU_SG_REL_ BCM1 SG_ 1171 MF_Wischerstufe_1 2000;
BA_REL_ "GenSigTimeoutTime" BU_SG_REL_ BCM1 SG_ 1171 MF_Wischerstufe_2 2000;
BA_REL_ "GenSigTimeoutTime" BU_SG_REL_ BCM1 SG_ 1171 MF_Frontwaschen 2000;
BA_REL_ "GenSigTimeoutTime" BU_SG_REL_ BCM1 SG_ 1171 MF_Heckintervall 2000;
BA_REL_ "GenSigTimeoutTime" BU_SG_REL_ BCM1 SG_ 1171 MF_Heckwaschen 2000;
BA_REL_ "GenSigTimeoutTime" BU_SG_REL_ BCM1 SG_ 1171 MF_TFL_Abschaltung 2000;
BA_REL_ "GenSigTimeoutTime" BU_SG_REL_ BCM1 SG_ 1171 MF_Signalhorn 2000;
BA_REL_ "GenSigTimeoutTime" BU_SG_REL_ BCM1 SG_ 817 MFL_Tastencode_1 5000;
BA_REL_ "GenSigTimeoutTime" BU_SG_REL_ BCM1 SG_ 817 MFL_Tastencode_2 5000;
BA_REL_ "GenSigTimeoutTime" BU_SG_REL_ BCM1 SG_ 817 MFL_Signalhorn 5000;
BA_REL_ "GenSigTimeoutTime" BU_SG_REL_ BCM1 SG_ 1600 MO_Absperrventil_oeffnen 3200;
BA_REL_ "GenSigTimeoutTime" BU_SG_REL_ BCM1 SG_ 1600 MO_Oel_Temp 3200;
BA_REL_ "GenSigTimeoutTime" BU_SG_REL_ BCM1 SG_ 1600 MO_Kuehlmittel_Temp 3200;
BA_REL_ "GenSigTimeoutTime" BU_SG_REL_ BCM1 SG_ 1600 MO_Hoeheninfo 3200;
BA_REL_ "GenSigTimeoutTime" BU_SG_REL_ BCM1 SG_ 1600 MO_Kennfeldk 3200;
BA_REL_ "GenSigTimeoutTime" BU_SG_REL_ BCM1 SG_ 1600 MO_Heizungspumpenansteuerung 3200;
BA_REL_ "GenSigTimeoutTime" BU_SG_REL_ BCM1 SG_ 1600 MO_Nachlaufzeit_Heizungspumpe 3200;
BA_REL_ "GenSigTimeoutTime" BU_SG_REL_ BCM1 SG_ 1607 MO_ITM_Kuehlmittel_Temp 3200;
BA_REL_ "GenSigTimeoutTime" BU_SG_REL_ BCM1 SG_ 168 MO_QBit_Drehzahl_01 500;
BA_REL_ "GenSigTimeoutTime" BU_SG_REL_ BCM1 SG_ 168 MO_Drehzahl_01 500;
BA_REL_ "GenSigTimeoutTime" BU_SG_REL_ BCM1 SG_ 958 MO_StartStopp_Status 1000;
BA_REL_ "GenSigTimeoutTime" BU_SG_REL_ BCM1 SG_ 958 MO_StartStopp_Wiederstart 1000;
BA_REL_ "GenSigTimeoutTime" BU_SG_REL_ BCM1 SG_ 958 MO_StartStopp_Motorstopp 1000;
BA_REL_ "GenSigTimeoutTime" BU_SG_REL_ BCM1 SG_ 958 MO_Kl_75 1000;
BA_REL_ "GenSigTimeoutTime" BU_SG_REL_ BCM1 SG_ 958 MO_Gangposition 1000;
BA_REL_ "GenSigTimeoutTime" BU_SG_REL_ BCM1 SG_ 958 MO_StartStopp_Fahrerwunsch 1000;
BA_REL_ "GenSigTimeoutTime" BU_SG_REL_ BCM1 SG_ 958 MO_HYB_Fahrbereitschaft 1000;
BA_REL_ "GenSigTimeoutTime" BU_SG_REL_ BCM1 SG_ 958 MO_Ext_E_Fahrt_aktiv 1000;
BA_REL_ "GenSigTimeoutTime" BU_SG_REL_ BCM1 SG_ 958 MO_Fahrer_bremst 1000;
BA_REL_ "GenSigTimeoutTime" BU_SG_REL_ BCM1 SG_ 958 MO_QBit_Fahrer_bremst 1000;
BA_REL_ "GenSigTimeoutTime" BU_SG_REL_ BCM1 SG_ 958 MO_BLS 1000;
BA_REL_ "GenSigTimeoutTime" BU_SG_REL_ BCM1 SG_ 958 MO_Klima_Eingr 1000;
BA_REL_ "GenSigTimeoutTime" BU_SG_REL_ BCM1 SG_ 958 MO_Kuppl_schalter 1000;
BA_REL_ "GenSigTimeoutTime" BU_SG_REL_ BCM1 SG_ 958 MO_Interlock 1000;
BA_REL_ "GenSigTimeoutTime" BU_SG_REL_ BCM1 SG_ 958 MO_Motor_laeuft 1000;
BA_REL_ "GenSigTimeoutTime" BU_SG_REL_ BCM1 SG_ 958 MO_Kickdown 1000;
BA_REL_ "GenSigTimeoutTime" BU_SG_REL_ BCM1 SG_ 958 MO_QBit_KL_75 1000;
BA_REL_ "GenSigTimeoutTime" BU_SG_REL_ BCM1 SG_ 958 MO_FMAus_aktiv 1000;
BA_REL_ "GenSigTimeoutTime" BU_SG_REL_ BCM1 SG_ 958 MO_HYB_VM_aktiv 1000;
BA_REL_ "GenSigTimeoutTime" BU_SG_REL_ BCM1 SG_ 1631 TSK_QBit_Steigung 3200;
BA_REL_ "GenSigTimeoutTime" BU_SG_REL_ BCM1 SG_ 1631 TSK_Steigung_02 3200;
BA_REL_ "GenSigTimeoutTime" BU_SG_REL_ BCM1 SG_ 812 MO_BZS_Charisma_FahrPr 2000;
BA_REL_ "GenSigTimeoutTime" BU_SG_REL_ Gateway SG_ 1624 LV_Standlicht_Anzeige 5000;
BA_REL_ "GenSigTimeoutTime" BU_SG_REL_ Gateway SG_ 1624 LV_Abblendlicht_Anzeige 5000;
BA_REL_ "GenSigTimeoutTime" BU_SG_REL_ Gateway SG_ 1624 LV_Fernlicht_Anzeige 5000;
BA_REL_ "GenSigTimeoutTime" BU_SG_REL_ Gateway SG_ 1624 LV_Nebellicht_Anzeige 5000;
BA_REL_ "GenSigTimeoutTime" BU_SG_REL_ Gateway SG_ 1624 LV_Nebelschlusslicht_Anzeige 5000;
BA_REL_ "GenSigTimeoutTime" BU_SG_REL_ Gateway SG_ 1624 LV_Tagfahrlicht_Anzeige 5000;
BA_REL_ "GenSigTimeoutTime" BU_SG_REL_ Gateway SG_ 1624 LV_AFL_aktiv_Anzeige 5000;
BA_REL_ "GenSigTimeoutTime" BU_SG_REL_ Gateway SG_ 1624 LV_AFL_defekt 5000;
BA_REL_ "GenSigTimeoutTime" BU_SG_REL_ Gateway SG_ 1624 LV_Blinker_li_def 5000;
BA_REL_ "GenSigTimeoutTime" BU_SG_REL_ Gateway SG_ 1624 LV_Standlicht_li_def 5000;
BA_REL_ "GenSigTimeoutTime" BU_SG_REL_ Gateway SG_ 1624 LV_Abblendlicht_li_def 5000;
BA_REL_ "GenSigTimeoutTime" BU_SG_REL_ Gateway SG_ 1624 LV_Fernlicht_li_def 5000;
BA_REL_ "GenSigTimeoutTime" BU_SG_REL_ Gateway SG_ 1624 LV_Nebellicht_li_def 5000;
BA_REL_ "GenSigTimeoutTime" BU_SG_REL_ Gateway SG_ 1624 LV_Blk_li_Seite_def 5000;
BA_REL_ "GenSigTimeoutTime" BU_SG_REL_ Gateway SG_ 1624 LV_Tagfahrlicht_li_def 5000;
BA_REL_ "GenSigTimeoutTime" BU_SG_REL_ Gateway SG_ 1624 LV_Blinker_re_def 5000;
BA_REL_ "GenSigTimeoutTime" BU_SG_REL_ Gateway SG_ 1624 LV_Standlicht_re_def 5000;
BA_REL_ "GenSigTimeoutTime" BU_SG_REL_ Gateway SG_ 1624 LV_Abblendlicht_re_def 5000;
BA_REL_ "GenSigTimeoutTime" BU_SG_REL_ Gateway SG_ 1624 LV_Fernlicht_re_def 5000;
BA_REL_ "GenSigTimeoutTime" BU_SG_REL_ Gateway SG_ 1624 LV_Nebellicht_re_def 5000;
BA_REL_ "GenSigTimeoutTime" BU_SG_REL_ Gateway SG_ 1624 LV_Blk_re_Seite_def 5000;
BA_REL_ "GenSigTimeoutTime" BU_SG_REL_ Gateway SG_ 1624 LV_Tagfahrlicht_re_def 5000;
BA_REL_ "GenSigTimeoutTime" BU_SG_REL_ Gateway SG_ 1624 LV_Aussenlicht_def 5000;
BA_REL_ "GenSigTimeoutTime" BU_SG_REL_ Gateway SG_ 1624 LV_Abblendlicht_TFL_li_def 5000;
BA_REL_ "GenSigTimeoutTime" BU_SG_REL_ Gateway SG_ 1624 LV_Nebellicht_TFL_li_def 5000;
BA_REL_ "GenSigTimeoutTime" BU_SG_REL_ Gateway SG_ 1624 LV_Standlicht_TFL_li_def 5000;
BA_REL_ "GenSigTimeoutTime" BU_SG_REL_ Gateway SG_ 1624 LV_Abblend_Fernlicht_li_def 5000;
BA_REL_ "GenSigTimeoutTime" BU_SG_REL_ Gateway SG_ 1624 LV_Abblendlicht_TFL_re_def 5000;
BA_REL_ "GenSigTimeoutTime" BU_SG_REL_ Gateway SG_ 1624 LV_Nebellicht_TFL_re_def 5000;
BA_REL_ "GenSigTimeoutTime" BU_SG_REL_ Gateway SG_ 1624 LV_Standlicht_TFL_re_def 5000;
BA_REL_ "GenSigTimeoutTime" BU_SG_REL_ Gateway SG_ 1624 LV_Abblend_Fernlicht_re_def 5000;
BA_REL_ "GenSigTimeoutTime" BU_SG_REL_ Gateway SG_ 1624 LV_Blinker_VL_aktiv 5000;
BA_REL_ "GenSigTimeoutTime" BU_SG_REL_ Gateway SG_ 1624 LV_Blinker_VR_aktiv 5000;
BA_REL_ "GenSigTimeoutTime" BU_SG_REL_ Gateway SG_ 1321 Lift_SpannungsAnf 2000;
BA_REL_ "GenSigTimeoutTime" BU_SG_REL_ Gateway SG_ 917 AFS_Charisma_FahrPr 1000;
BA_REL_ "GenSigTimeoutTime" BU_SG_REL_ Gateway SG_ 917 AFS_Charisma_Status 1000;
BA_REL_ "GenSigTimeoutTime" BU_SG_REL_ Gateway SG_ 917 LWR_Hoehenwert_VL 1000;
BA_REL_ "GenSigTimeoutTime" BU_SG_REL_ Gateway SG_ 917 LWR_Hoehenwert_HL 1000;
BA_REL_ "GenSigTimeoutTime" BU_SG_REL_ Gateway_PAG SG_ 1624 LV_Standlicht_Anzeige 5000;
BA_REL_ "GenSigTimeoutTime" BU_SG_REL_ Gateway_PAG SG_ 1624 LV_Abblendlicht_Anzeige 5000;
BA_REL_ "GenSigTimeoutTime" BU_SG_REL_ Gateway_PAG SG_ 1624 LV_Fernlicht_Anzeige 5000;
BA_REL_ "GenSigTimeoutTime" BU_SG_REL_ Gateway_PAG SG_ 1624 LV_Nebellicht_Anzeige 5000;
BA_REL_ "GenSigTimeoutTime" BU_SG_REL_ Gateway_PAG SG_ 1624 LV_Nebelschlusslicht_Anzeige 5000;
BA_REL_ "GenSigTimeoutTime" BU_SG_REL_ Gateway_PAG SG_ 1624 LV_Tagfahrlicht_Anzeige 5000;
BA_REL_ "GenSigTimeoutTime" BU_SG_REL_ Gateway_PAG SG_ 1624 LV_AFL_aktiv_Anzeige 5000;
BA_REL_ "GenSigTimeoutTime" BU_SG_REL_ Gateway_PAG SG_ 1624 LV_AFL_defekt 5000;
BA_REL_ "GenSigTimeoutTime" BU_SG_REL_ Gateway_PAG SG_ 1624 LV_Blinker_li_def 5000;
BA_REL_ "GenSigTimeoutTime" BU_SG_REL_ Gateway_PAG SG_ 1624 LV_Standlicht_li_def 5000;
BA_REL_ "GenSigTimeoutTime" BU_SG_REL_ Gateway_PAG SG_ 1624 LV_Abblendlicht_li_def 5000;
BA_REL_ "GenSigTimeoutTime" BU_SG_REL_ Gateway_PAG SG_ 1624 LV_Fernlicht_li_def 5000;
BA_REL_ "GenSigTimeoutTime" BU_SG_REL_ Gateway_PAG SG_ 1624 LV_Nebellicht_li_def 5000;
BA_REL_ "GenSigTimeoutTime" BU_SG_REL_ Gateway_PAG SG_ 1624 LV_Blk_li_Seite_def 5000;
BA_REL_ "GenSigTimeoutTime" BU_SG_REL_ Gateway_PAG SG_ 1624 LV_Tagfahrlicht_li_def 5000;
BA_REL_ "GenSigTimeoutTime" BU_SG_REL_ Gateway_PAG SG_ 1624 LV_Blinker_re_def 5000;
BA_REL_ "GenSigTimeoutTime" BU_SG_REL_ Gateway_PAG SG_ 1624 LV_Standlicht_re_def 5000;
BA_REL_ "GenSigTimeoutTime" BU_SG_REL_ Gateway_PAG SG_ 1624 LV_Abblendlicht_re_def 5000;
BA_REL_ "GenSigTimeoutTime" BU_SG_REL_ Gateway_PAG SG_ 1624 LV_Fernlicht_re_def 5000;
BA_REL_ "GenSigTimeoutTime" BU_SG_REL_ Gateway_PAG SG_ 1624 LV_Nebellicht_re_def 5000;
BA_REL_ "GenSigTimeoutTime" BU_SG_REL_ Gateway_PAG SG_ 1624 LV_Blk_re_Seite_def 5000;
BA_REL_ "GenSigTimeoutTime" BU_SG_REL_ Gateway_PAG SG_ 1624 LV_Tagfahrlicht_re_def 5000;
BA_REL_ "GenSigTimeoutTime" BU_SG_REL_ Gateway_PAG SG_ 1624 LV_Aussenlicht_def 5000;
BA_REL_ "GenSigTimeoutTime" BU_SG_REL_ Gateway_PAG SG_ 1624 LV_Abblendlicht_TFL_li_def 5000;
BA_REL_ "GenSigTimeoutTime" BU_SG_REL_ Gateway_PAG SG_ 1624 LV_Nebellicht_TFL_li_def 5000;
BA_REL_ "GenSigTimeoutTime" BU_SG_REL_ Gateway_PAG SG_ 1624 LV_Standlicht_TFL_li_def 5000;
BA_REL_ "GenSigTimeoutTime" BU_SG_REL_ Gateway_PAG SG_ 1624 LV_Abblend_Fernlicht_li_def 5000;
BA_REL_ "GenSigTimeoutTime" BU_SG_REL_ Gateway_PAG SG_ 1624 LV_Abblendlicht_TFL_re_def 5000;
BA_REL_ "GenSigTimeoutTime" BU_SG_REL_ Gateway_PAG SG_ 1624 LV_Nebellicht_TFL_re_def 5000;
BA_REL_ "GenSigTimeoutTime" BU_SG_REL_ Gateway_PAG SG_ 1624 LV_Standlicht_TFL_re_def 5000;
BA_REL_ "GenSigTimeoutTime" BU_SG_REL_ Gateway_PAG SG_ 1624 LV_Abblend_Fernlicht_re_def 5000;
BA_REL_ "GenSigTimeoutTime" BU_SG_REL_ Gateway_PAG SG_ 1624 LV_Blinker_VL_aktiv 5000;
BA_REL_ "GenSigTimeoutTime" BU_SG_REL_ Gateway_PAG SG_ 1624 LV_Blinker_VR_aktiv 5000;
BA_REL_ "GenSigTimeoutTime" BU_SG_REL_ Gateway_PAG SG_ 1321 Lift_SpannungsAnf 2000;
BA_REL_ "GenSigTimeoutTime" BU_SG_REL_ Gateway_PAG SG_ 917 AFS_Charisma_FahrPr 1000;
BA_REL_ "GenSigTimeoutTime" BU_SG_REL_ Gateway_PAG SG_ 917 AFS_Charisma_Status 1000;
BA_REL_ "GenSigTimeoutTime" BU_SG_REL_ Klima_MSB SG_ 822 LR_HZG_Temp_Sensor 1200;
BA_REL_ "GenSigTimeoutTime" BU_SG_REL_ Klima_MSB SG_ 822 LR_HZG_Taster_on_off 1200;
BA_REL_ "GenSigTimeoutTime" BU_SG_REL_ Klima_MSB SG_ 1178 FS_MMB_storage 1000;
BA_REL_ "GenSigTimeoutTime" BU_SG_REL_ Klima_MSB SG_ 1178 FS_MMB_tipp 1000;
BA_REL_ "GenSigTimeoutTime" BU_SG_REL_ Klima_MSB SG_ 1178 FS_MMB_tast 1000;
BA_REL_ "GenSigTimeoutTime" BU_SG_REL_ Klima_MSB SG_ 1178 FS_MMB_store 1000;
BA_REL_ "GenSigTimeoutTime" BU_SG_REL_ Klima_MSB SG_ 1600 MO_Absperrventil_oeffnen 3200;
BA_REL_ "GenSigTimeoutTime" BU_SG_REL_ Klima_MSB SG_ 1600 MO_Oel_Temp 3200;
BA_REL_ "GenSigTimeoutTime" BU_SG_REL_ Klima_MSB SG_ 1600 MO_Kuehlmittel_Temp 3200;
BA_REL_ "GenSigTimeoutTime" BU_SG_REL_ Klima_MSB SG_ 1600 MO_Hoeheninfo 3200;
BA_REL_ "GenSigTimeoutTime" BU_SG_REL_ Klima_MSB SG_ 1600 MO_Kennfeldk 3200;
BA_REL_ "GenSigTimeoutTime" BU_SG_REL_ Klima_MSB SG_ 1600 MO_Heizungspumpenansteuerung 3200;
BA_REL_ "GenSigTimeoutTime" BU_SG_REL_ Klima_MSB SG_ 1607 MO_ITM_Kuehlmittel_Temp 3200;
BA_REL_ "GenSigTimeoutTime" BU_SG_REL_ Klima_MSB SG_ 168 MO_QBit_Drehzahl_01 500;
BA_REL_ "GenSigTimeoutTime" BU_SG_REL_ Klima_MSB SG_ 168 MO_Drehzahl_01 500;
BA_REL_ "GenSigTimeoutTime" BU_SG_REL_ Klima_MSB SG_ 958 MO_StartStopp_Status 1000;
BA_REL_ "GenSigTimeoutTime" BU_SG_REL_ Klima_MSB SG_ 958 MO_StartStopp_Wiederstart 1000;
BA_REL_ "GenSigTimeoutTime" BU_SG_REL_ Klima_MSB SG_ 958 MO_StartStopp_Motorstopp 1000;
BA_REL_ "GenSigTimeoutTime" BU_SG_REL_ Klima_MSB SG_ 958 MO_Kl_75 1000;
BA_REL_ "GenSigTimeoutTime" BU_SG_REL_ Klima_MSB SG_ 958 MO_Gangposition 1000;
BA_REL_ "GenSigTimeoutTime" BU_SG_REL_ Klima_MSB SG_ 958 MO_StartStopp_Fahrerwunsch 1000;
BA_REL_ "GenSigTimeoutTime" BU_SG_REL_ Klima_MSB SG_ 958 MO_HYB_Fahrbereitschaft 1000;
BA_REL_ "GenSigTimeoutTime" BU_SG_REL_ Klima_MSB SG_ 958 MO_Ext_E_Fahrt_aktiv 1000;
BA_REL_ "GenSigTimeoutTime" BU_SG_REL_ Klima_MSB SG_ 958 MO_Klima_Eingr 1000;
BA_REL_ "GenSigTimeoutTime" BU_SG_REL_ Klima_MSB SG_ 958 MO_Motor_laeuft 1000;
BA_REL_ "GenSigTimeoutTime" BU_SG_REL_ Klima_MSB SG_ 958 MO_Kickdown 1000;
BA_REL_ "GenSigTimeoutTime" BU_SG_REL_ Klima_MSB SG_ 958 MO_FMAus_aktiv 1000;
BA_REL_ "GenSigTimeoutTime" BU_SG_REL_ Klima_MSB SG_ 958 MO_HYB_VM_aktiv 1000;
BA_REL_ "GenSigTimeoutTime" BU_SG_REL_ Lift_VA SG_ 134 LWI_Lenkradwinkel 1000;
BA_REL_ "GenSigTimeoutTime" BU_SG_REL_ Lift_VA SG_ 134 LWI_VZ_Lenkradwinkel 1000;
BA_REL_ "GenSigTimeoutTime" BU_SG_REL_ Lift_VA SG_ 168 MO_Drehzahl_01 500;
BA_REL_ "GenSigTimeoutTime" BU_SG_REL_ Lift_VA SG_ 958 MO_StartStopp_Status 1000;
BA_REL_ "GenSigTimeoutTime" BU_SG_REL_ Lift_VA SG_ 958 MO_StartStopp_Wiederstart 1000;
BA_REL_ "GenSigTimeoutTime" BU_SG_REL_ Lift_VA SG_ 958 MO_StartStopp_Motorstopp 1000;
BA_REL_ "GenSigTimeoutTime" BU_SG_REL_ Lift_VA SG_ 958 MO_Kl_50 1000;
BA_REL_ "GenSigTimeoutTime" BU_SG_REL_ Lift_VA SG_ 958 MO_StartStopp_Fahrerwunsch 1000;
BA_REL_ "GenSigTimeoutTime" BU_SG_REL_ Lift_VA SG_ 958 MO_Motor_laeuft 1000;
BA_REL_ "GenSigTimeoutTime" BU_SG_REL_ VAS_L SG_ 1624 LV_Blinker_li_def 5000;
BA_REL_ "GenSigTimeoutTime" BU_SG_REL_ VAS_L SG_ 1624 LV_Abblendlicht_li_def 5000;
BA_REL_ "GenSigTimeoutTime" BU_SG_REL_ VAS_L SG_ 1624 LV_Fernlicht_li_def 5000;
BA_REL_ "GenSigTimeoutTime" BU_SG_REL_ VAS_L SG_ 1624 LV_Nebellicht_li_def 5000;
BA_REL_ "GenSigTimeoutTime" BU_SG_REL_ VAS_L SG_ 1624 LV_Blk_li_Seite_def 5000;
BA_REL_ "GenSigTimeoutTime" BU_SG_REL_ VAS_L SG_ 1624 LV_Blinker_re_def 5000;
BA_REL_ "GenSigTimeoutTime" BU_SG_REL_ VAS_L SG_ 1624 LV_Abblendlicht_re_def 5000;
BA_REL_ "GenSigTimeoutTime" BU_SG_REL_ VAS_L SG_ 1624 LV_Fernlicht_re_def 5000;
BA_REL_ "GenSigTimeoutTime" BU_SG_REL_ VAS_L SG_ 1624 LV_Nebellicht_re_def 5000;
BA_REL_ "GenSigTimeoutTime" BU_SG_REL_ VAS_L SG_ 1624 LV_Blk_re_Seite_def 5000;
BA_REL_ "GenSigTimeoutTime" BU_SG_REL_ VAS_L SG_ 1624 LV_Aussenlicht_def 5000;
BA_REL_ "GenSigTimeoutTime" BU_SG_REL_ VAS_L SG_ 1624 LV_Abblendlicht_TFL_li_def 5000;
BA_REL_ "GenSigTimeoutTime" BU_SG_REL_ VAS_L SG_ 1624 LV_Nebellicht_TFL_li_def 5000;
BA_REL_ "GenSigTimeoutTime" BU_SG_REL_ VAS_L SG_ 1624 LV_Abblend_Fernlicht_li_def 5000;
BA_REL_ "GenSigTimeoutTime" BU_SG_REL_ VAS_L SG_ 1624 LV_Abblendlicht_TFL_re_def 5000;
BA_REL_ "GenSigTimeoutTime" BU_SG_REL_ VAS_L SG_ 1624 LV_Nebellicht_TFL_re_def 5000;
BA_REL_ "GenSigTimeoutTime" BU_SG_REL_ VAS_L SG_ 1624 LV_Abblend_Fernlicht_re_def 5000;
BA_REL_ "GenSigTimeoutTime" BU_SG_REL_ VAS_L SG_ 1624 LV_Blinker_VL_aktiv 5000;
BA_REL_ "GenSigTimeoutTime" BU_SG_REL_ VAS_L SG_ 1624 LV_Blinker_VR_aktiv 5000;
BA_REL_ "GenSigTimeoutTime" BU_SG_REL_ VAS_L SG_ 958 MO_Kl_75 1000;
BA_REL_ "GenSigTimeoutTime" BU_SG_REL_ VAS_L SG_ 958 MO_Gangposition 1000;
BA_REL_ "GenSigTimeoutTime" BU_SG_REL_ VAS_R SG_ 1624 LV_Blinker_li_def 5000;
BA_REL_ "GenSigTimeoutTime" BU_SG_REL_ VAS_R SG_ 1624 LV_Abblendlicht_li_def 5000;
BA_REL_ "GenSigTimeoutTime" BU_SG_REL_ VAS_R SG_ 1624 LV_Fernlicht_li_def 5000;
BA_REL_ "GenSigTimeoutTime" BU_SG_REL_ VAS_R SG_ 1624 LV_Nebellicht_li_def 5000;
BA_REL_ "GenSigTimeoutTime" BU_SG_REL_ VAS_R SG_ 1624 LV_Blk_li_Seite_def 5000;
BA_REL_ "GenSigTimeoutTime" BU_SG_REL_ VAS_R SG_ 1624 LV_Blinker_re_def 5000;
BA_REL_ "GenSigTimeoutTime" BU_SG_REL_ VAS_R SG_ 1624 LV_Abblendlicht_re_def 5000;
BA_REL_ "GenSigTimeoutTime" BU_SG_REL_ VAS_R SG_ 1624 LV_Fernlicht_re_def 5000;
BA_REL_ "GenSigTimeoutTime" BU_SG_REL_ VAS_R SG_ 1624 LV_Nebellicht_re_def 5000;
BA_REL_ "GenSigTimeoutTime" BU_SG_REL_ VAS_R SG_ 1624 LV_Blk_re_Seite_def 5000;
BA_REL_ "GenSigTimeoutTime" BU_SG_REL_ VAS_R SG_ 1624 LV_Aussenlicht_def 5000;
BA_REL_ "GenSigTimeoutTime" BU_SG_REL_ VAS_R SG_ 1624 LV_Abblendlicht_TFL_li_def 5000;
BA_REL_ "GenSigTimeoutTime" BU_SG_REL_ VAS_R SG_ 1624 LV_Nebellicht_TFL_li_def 5000;
BA_REL_ "GenSigTimeoutTime" BU_SG_REL_ VAS_R SG_ 1624 LV_Abblend_Fernlicht_li_def 5000;
BA_REL_ "GenSigTimeoutTime" BU_SG_REL_ VAS_R SG_ 1624 LV_Abblendlicht_TFL_re_def 5000;
BA_REL_ "GenSigTimeoutTime" BU_SG_REL_ VAS_R SG_ 1624 LV_Nebellicht_TFL_re_def 5000;
BA_REL_ "GenSigTimeoutTime" BU_SG_REL_ VAS_R SG_ 1624 LV_Abblend_Fernlicht_re_def 5000;
BA_REL_ "GenSigTimeoutTime" BU_SG_REL_ VAS_R SG_ 1624 LV_Blinker_VL_aktiv 5000;
BA_REL_ "GenSigTimeoutTime" BU_SG_REL_ VAS_R SG_ 1624 LV_Blinker_VR_aktiv 5000;
BA_REL_ "GenSigTimeoutTime" BU_SG_REL_ VAS_R SG_ 958 MO_Kl_75 1000;
BA_REL_ "GenSigTimeoutTime" BU_SG_REL_ VAS_R SG_ 958 MO_Gangposition 1000;
VAL_ 1624 LV_Standlicht_Anzeige 0 "nicht aktiv" 1 "aktiv" ;
VAL_ 1624 LV_Abblendlicht_Anzeige 0 "inaktiv" 1 "aktiv" ;
VAL_ 1624 LV_Fernlicht_Anzeige 0 "nicht aktiv" 1 "aktiv" ;
VAL_ 1624 LV_Nebellicht_Anzeige 0 "nicht aktiv" 1 "aktiv" ;
VAL_ 1624 LV_Nebelschlusslicht_Anzeige 0 "nicht aktiv" 1 "aktiv" ;
VAL_ 1624 LV_Tagfahrlicht_Anzeige 0 "nicht aktiv" 1 "aktiv" ;
VAL_ 1624 LV_AFL_aktiv_Anzeige 0 "nicht aktiv" 1 "aktiv" ;
VAL_ 1624 LV_AFL_defekt 0 "OK" 1 "defekt" ;
VAL_ 1624 LV_Blinker_li_def 0 "OK" 1 "defekt" ;
VAL_ 1624 LV_Standlicht_li_def 0 "OK" 1 "defekt" ;
VAL_ 1624 LV_Abblendlicht_li_def 0 "OK" 1 "defekt" ;
VAL_ 1624 LV_Fernlicht_li_def 0 "OK" 1 "defekt" ;
VAL_ 1624 LV_Nebellicht_li_def 0 "OK" 1 "defekt" ;
VAL_ 1624 LV_Blk_li_Seite_def 0 "OK" 1 "defekt" ;
VAL_ 1624 LV_Tagfahrlicht_li_def 0 "OK" 1 "defekt" ;
VAL_ 1624 LV_FLA_aktiv_Anzeige 0 "aus" 1 "ein" ;
VAL_ 1624 LV_FLA_defekt 0 "i.O." 1 "FLA defekt" ;
VAL_ 1624 LV_FLA_Sensor_blockiert 0 "i.O." 1 "FLA-Sensor blockiert" ;
VAL_ 1624 LV_Blinker_re_def 0 "OK" 1 "defekt" ;
VAL_ 1624 LV_Standlicht_re_def 0 "OK" 1 "defekt" ;
VAL_ 1624 LV_Abblendlicht_re_def 0 "OK" 1 "defekt" ;
VAL_ 1624 LV_Fernlicht_re_def 0 "OK" 1 "defekt" ;
VAL_ 1624 LV_Nebellicht_re_def 0 "OK" 1 "defekt" ;
VAL_ 1624 LV_Blk_re_Seite_def 0 "OK" 1 "defekt" ;
VAL_ 1624 LV_Tagfahrlicht_re_def 0 "OK" 1 "defekt" ;
VAL_ 1624 LV_Aussenlicht_def 0 "OK" 1 "defekt" ;
VAL_ 1624 LV_Abblendlicht_TFL_li_def 0 "OK" 1 "defekt" ;
VAL_ 1624 LV_Nebellicht_TFL_li_def 0 "OK" 1 "defekt" ;
VAL_ 1624 LV_Standlicht_TFL_li_def 0 "OK" 1 "defekt" ;
VAL_ 1624 LV_Abblend_Fernlicht_li_def 0 "OK" 1 "defekt" ;
VAL_ 1624 LV_Abblendlicht_TFL_re_def 0 "OK" 1 "defekt" ;
VAL_ 1624 LV_Nebellicht_TFL_re_def 0 "OK" 1 "defekt" ;
VAL_ 1624 LV_Standlicht_TFL_re_def 0 "OK" 1 "defekt" ;
VAL_ 1624 LV_Abblend_Fernlicht_re_def 0 "OK" 1 "defekt" ;
VAL_ 1624 LV_Abbiegelicht_li_def 0 "OK" 1 "defekt" ;
VAL_ 1624 LV_Abbiegelicht_re_def 0 "OK" 1 "defekt" ;
VAL_ 1624 BCM1_Linksverkehr 0 "Rechtsverkehr" 1 "Linksverkehr" ;
VAL_ 1624 BCM1_Licht_Dunkelheit_aktiv 0 "inaktiv" 1 "aktiv" ;
VAL_ 1624 LV_LED_Scheinwerfer_li_def 0 "OK" 1 "defekt" ;
VAL_ 1624 LV_LED_Scheinwerfer_re_def 0 "OK" 1 "defekt" ;
VAL_ 1624 LV_Blinker_VL_aktiv 0 "inaktiv" 1 "aktiv" ;
VAL_ 1624 LV_Blinker_VR_aktiv 0 "inaktiv" 1 "aktiv" ;
VAL_ 1624 LV_MXB_Status_Anzeige 0 "MXB_aus" 1 "MXB_regelt" 2 "MXB_volles_Fernlicht" 3 "MXB_und_Laser_aktiv" ;
VAL_ 1321 Lift_Charisma_FahrPr 0 "nicht_belegt" 1 "Programm_1" 2 "Programm_2" 3 "Programm_3" 4 "Programm_4" 5 "Programm_5" 6 "Programm_6" 7 "Programm_7" ;
VAL_ 1321 Lift_Charisma_Status 0 "Init" 1 "verfuegbar" 2 "nicht_verfuegbar" 3 "asynchron_durch_Fahrerwunsch" ;
VAL_ 1321 Lift_Charisma_Umschaltung 0 "Idle" 1 "Erkennung_Umschaltaufforderung" 2 "Steuerbotschaft_nicht_definiert" 3 "Umschaltung_verzoegert" ;
VAL_ 1321 Lift_Anforderung_EFP 0 "Init" 1 "Anforderung_Tiefniveau" 2 "Anforderung_Hochniveau" ;
VAL_ 1321 Lift_ESP_Zuschaltung 0 "keine_ESP_Beeinflussung" 1 "ESP_Zwangszuschaltung_gefordert" ;
VAL_ 1321 Lift_Meldung_12 0 "inaktiv" 1 "aktiv" ;
VAL_ 1321 Lift_Meldung_13 0 "inaktiv" 1 "aktiv" ;
VAL_ 1321 Lift_Meldung_14 0 "inaktiv" 1 "aktiv" ;
VAL_ 1321 Lift_LED 0 "LED_aus" 1 "LED_ein" 2 "LED_blinken" 3 "Fehler" ;
VAL_ 1321 Lift_Position 0 "Init" 1 "Lift_in_Endlage_unten" 2 "Lift_in_Endlage_oben" 3 "Ausfuehrung_Hebevorgang" 4 "Ausfuehrung_Senkvorgang" 5 "Lift_in_zwischenstellung" ;
VAL_ 1321 Lift_Meldung_01 0 "inaktiv" 1 "aktiv" ;
VAL_ 1321 Lift_Meldung_02 0 "Init" 1 "Meldung_aktiv" ;
VAL_ 1321 Lift_Meldung_03 0 "inaktiv" 1 "aktiv" ;
VAL_ 1321 Lift_Meldung_04 0 "inaktiv" 1 "aktiv" ;
VAL_ 1321 Lift_Meldung_05 0 "inaktiv" 1 "aktiv" ;
VAL_ 1321 Lift_Meldung_06 0 "inaktiv" 1 "aktiv" ;
VAL_ 1321 Lift_Meldung_07 0 "inaktiv" 1 "aktiv" ;
VAL_ 1321 Lift_Meldung_08 0 "inaktiv" 1 "aktiv" ;
VAL_ 1321 Lift_Meldung_09 0 "inaktiv" 1 "aktiv" ;
VAL_ 1321 Lift_Meldung_10 0 "inaktiv" 1 "aktiv" ;
VAL_ 1321 Lift_Meldung_11 0 "inaktiv" 1 "aktiv" ;
VAL_ 1321 Lift_SpannungsAnf 0 "Keine_Anforderung" 1 "Anforderung_Stufe1" 2 "Anforderung_Stufe2" 3 "Anforderung_Stufe3" ;
VAL_ 1321 Lift_StartStopp_Info 0 "Motorlauf_nicht_notwendig_(Stoppfreigabe)" 1 "Motoranlauf_nicht_zwingend_notwendig_(Stoppverbot,keine_Startanforderung)" 2 "Motoranlauf_zwingend_notwendig_(Startanforderung)" 3 "Systemfehler" ;
VAL_ 822 LR_HZG_Temp_Sensor 253 "KS_Plus__Unterbrechung" 254 "Init" 255 "Tempsensor_fehlerhaft__KS_GND" ;
VAL_ 822 LR_HZG_Taster_on_off 0 "nicht_betaetigt" 1 "betaetigt" ;
VAL_ 2527679652 LS1_Reinigung_Anf 0 "Reinigung_Aus" 1 "Reinigung_Ein" ;
VAL_ 134 LWI_Sensorstatus 0 "iO" 1 "nicht kalibriert" ;
VAL_ 134 LWI_QBit_Sub_Daten 0 "LWS-Subinfo real (Lenkradwinkelinformation ADS-tauglich) " 1 "LWS-Subinfo simuliert (Lenkradwinkelinformation nicht ADS-tauglich )" ;
VAL_ 134 LWI_MFL_Abschaltung 0 "inaktiv" 1 "aktiv" ;
VAL_ 134 LWI_QBit_Lenkradwinkel 0 "gültiger Wert" 1 "ausserhalb der Spezifikation" ;
VAL_ 134 LWI_Lenkradwinkel 8190 "Init" 8191 "Fehler" ;
VAL_ 134 LWI_VZ_Lenkradwinkel 0 "positiv_links_von_der_Nullstellung" 1 "negativ" ;
VAL_ 134 LWI_VZ_Lenkradw_Geschw 0 "positiv_links_von_der_Nullstellung" 1 "negativ" ;
VAL_ 134 LWI_Lenkradw_Geschw 510 "Init" 511 "Fehler" ;
VAL_ 917 AFS_Abbiegelicht_li_Anf 0 "Abbiegelicht_aus" 1 "Abbiegelicht_ein" ;
VAL_ 917 AFS_Abbiegelicht_re_Anf 0 "Abbiegelicht_aus" 1 "Abbiegelicht_ein" ;
VAL_ 917 AFS_Abbiegelicht_Dimm_Anf 0 "Dimmung_angefordert" 1 "keine_Dimmung" ;
VAL_ 917 AFS_Verfuegbarkeit_GLW 0 "GLW_nicht_verfuegbar" 1 "GLW_verfuegbar" ;
VAL_ 917 AFS_Status_adaptive_LV 0 "adaptive_Lichtverteilung_aus" 1 "adaptive_Lichtverteilung_an" ;
VAL_ 917 AFS_Fernlicht_li_defekt 0 "Fernlicht_in_Ordnung" 1 "Fernlicht_defekt" ;
VAL_ 917 AFS_Fernlicht_re_defekt 0 "Fernlicht_in_Ordnung" 1 "Fernlicht_defekt" ;
VAL_ 917 AFS_Fernlicht_Status 0 "Fernlicht_aus" 1 "Fernlicht_ein" ;
VAL_ 917 AFS_Lampe 0 "Aus" 1 "Ein" ;
VAL_ 917 LWR_Lampe 0 "LWR Fehlerlampe aus" 1 "LWR Fehlerlampe ein" ;
VAL_ 917 AFS_Fehlertext 0 "kein Text" 1 "AFS ohne Funktion" ;
VAL_ 917 AFS_LED_Blinkmode 0 "kein Blinkmode angefordert" 1 "Blinkmode angefordert" ;
VAL_ 917 LWR_Touristenmodus_aktiv 0 "Touristenmodus inaktiv" 1 "Touristenmodus aktiv" ;
VAL_ 917 AFS_Charisma_FahrPr 0 "keine_Funktion" 1 "Programm_1" 2 "Programm_2" 3 "Programm_3" 4 "Programm_4" 5 "Programm_5" 6 "Programm_6" 7 "Programm_7" 8 "Programm_8" 9 "Programm_9" 10 "Programm_10" 11 "Programm_11" 12 "Programm_12" 13 "Programm_13" 14 "Programm_14" 15 "Programm_15" ;
VAL_ 917 AFS_Charisma_Status 0 "Init" 1 "verfuegbar" 2 "nicht_verfuegbar" 3 "asynchron_durch_Fahrerwunsch" ;
VAL_ 917 LWR_Sicherheitsposition_re 0 "inaktiv" 1 "aktiv" ;
VAL_ 917 AFS_Allwetterlicht 0 "Allwetterlicht_nicht_aktiv" 1 "Allwetterlicht_aktiv" ;
VAL_ 917 LWR_Touristenmodus_verbaut 0 "Touristenmodus_nicht_verbaut" 1 "Touristenmodus_verbaut" ;
VAL_ 917 AFS_adaptive_LV_verbaut 0 "adaptive_Lichtverteilung_nicht_verbaut" 1 "adaptive_Lichtverteilung_verbaut" ;
VAL_ 917 LWR_Reisemodus_Texte 0 "keine_Anzeige" 1 "Umschaltung_auf_Linksverkehr_aktiv" 2 "Umschaltung_auf_Rechtsverkehr_aktiv" ;
VAL_ 917 GLW_Sensor_blockiert 0 "Kamera_Sensor_nicht_blockiert" 1 "Kamera_Sensor_blockiert" ;
VAL_ 917 AFS_Charisma_Umschaltung 0 "Idle" 1 "Erkennung_Umschaltaufforderung" 2 "Steuerbotschaft_nicht_definiert" 3 "Umschaltung_verzoegert" ;
VAL_ 917 LWR_Pos_Schrittmotor 254 "Init" 255 "Fehler" ;
VAL_ 917 LWR_Hoehenwert_VL 254 "nicht_initialisiert" 255 "Fehler" ;
VAL_ 917 LWR_Hoehenwert_HL 254 "nicht_initialisiert" 255 "Fehler" ;
VAL_ 917 AFS_Ersatzlicht_Links 0 "keine Ersatzlichtfunktion links" 1 "Ersatzlichtfunktion links" ;
VAL_ 917 AFS_Ersatzlicht_Rechts 0 "keine Ersatzlichtfunktion rechts" 1 "Ersatzlichtfunktion rechts" ;
VAL_ 917 LWR_AFS_Grundeinstellung 0 "Grundeinstellung nicht erfolgt" 1 "Grundeinstellung erfolgt" ;
VAL_ 917 LWR_AFS_Parametrisierung 0 "Parametrisierung nicht erfolgt" 1 "Parametrisierung erfolgt" ;
VAL_ 917 LWR_Initialisierungslauf 0 "Initialisierungslauf nicht erfolgt" 1 "Initialisierungslauf erfolgt" ;
VAL_ 917 LWR_Sicherheitsposition_li 0 "inaktiv" 1 "aktiv" ;
VAL_ 917 LWR_Modus 0 "LWR statisch" 1 "LWR dynamisch" ;
VAL_ 1153 ZR_LoGeWa_Event_Kombiwarnung 0 "Init" 1 "Unfall" 2 "Traktionsverlust" 3 "Panne" 4 "Sichtbehinderung" 5 "Aquaplaning" 6 "EEBL" 7 "SEF_stat" 8 "SEF_dyn_allgemein" 9 "SEF_dyn_vorne" 10 "SEF_dyn_hinten" 11 "SEF_dyn_links" 12 "SEF_dyn_rechts" 13 "Stauende" ;
VAL_ 1153 Nav_FoD_Status 0 "Init" 1 "Nav_permanently_available" 2 "FoD_Nav_not_activated" 3 "FoD_Nav_activated" 4 "R4N_Nav_not_activated" ;
VAL_ 1153 MIB_Tongenerator_PH_verfuegbar 0 "Tongenerator_nicht_verfuegbar" 1 "Tongenerator_vorne_verfuegbar" 2 "Tongenerator_hinten_verfuegbar" 3 "Tongenerator_gesamt_verfuegbar" 4 "Tongenerator_im_AMP" ;
VAL_ 1153 DSSS_Warning 0 "No_Warning" 1 "Red_traffic_light_guidance" 2 "Stop_sign_warning" 3 "Rear_end_collision_avoidance_warning" 4 "Intersection_collision_avoidance_warning_right" 5 "Intersection_collision_avoidance_warning_left" 6 "turn_right_collision_avoidance" 7 "turn_left_collision_avoidance" 8 "pedestrian_crossing_right" 9 "pedestrian_crossing_left" 10 "bicycle_collision_right" 11 "bicycle_collision_left" ;
VAL_ 1153 ZR_Kindersicherung_RSE 0 "inaktiv" 1 "aktiv" ;
VAL_ 1153 ZR_RSE_aktivieren 0 "inaktiv" 1 "aktiv" ;
VAL_ 1153 MMI_SDS_aktiv 0 "inaktiv" 1 "aktiv" ;
VAL_ 1153 MU_SecondDisplay 0 "Init" 1 "gueltige_Karte" 2 "ungueltiges_Signal" 3 "Nicht_Verbaut" ;
VAL_ 1153 MMI_Telefon_aktiv 0 "Telefongespraech_nicht_aktiv" 1 "Telefongespraech_aktiv" ;
VAL_ 1153 MMI_Gurt_Mic_ref 0 "Downlink_inaktiv" 1 "Downlink_aktiv" ;
VAL_ 1153 ZR_Sta_Inszenierung 0 "Init" 1 "Inszenierung_deaktiviert" 2 "Inszenierung_Start" 3 "Inszenierung_Stop" ;
VAL_ 1153 MMI_Gauges_active 0 "gauges_inactive" 1 "gauges_active" ;
VAL_ 1153 ZR_MXB_Manoever_Ansage 0 "keine_Ansage" 1 "Ansage_ohne_Richtung" 2 "Ansage_rechte_Richtung" 3 "Ansage_linke_Richtung" ;
VAL_ 1153 ZR_LAPP_Sondermodus_Status 0 "keine_Anforderung" 1 "Sondermodus_aktiv" 2 "Aktivierung_nicht_moeglich" ;
VAL_ 1153 MMI_StartStopp_Info 0 "Stoppfreigabe" 1 "Stoppverbot" 2 "Startanforderung" 3 "Fehler" ;
VAL_ 1153 ZR_Parken_Sondermodus 0 "Init" 1 "Sondermodus_aktiv" 2 "Sondermodus_nicht_verfuegbar" 3 "WLAN_aus" 4 "WLAN_auscodiert" 15 "keine_WLAN_HW" ;
VAL_ 1153 ZR_Rundenbewertung 0 "Bewertung_nicht_aktiv" 1 "langsamer" 2 "gleich_schnell" 3 "schneller" 4 "reserviert" 5 "reserviert" 6 "reserviert" 7 "reserviert" 8 "reserviert" 9 "reserviert" 10 "reserviert" 11 "reserviert" 12 "reserviert" 13 "reserviert" 14 "Init" 15 "Funktion_nicht_verbaut" ;
VAL_ 1153 ZR_Rundenfortschritt 254 "Init" 255 "Funktion_nicht_verbaut" ;
VAL_ 1639 BFS_Fond_Bed_Ack 0 "nicht aktiviert" 1 "aktiviert" ;
VAL_ 1639 BFS_Lehne_nicht_verriegelt 0 "keine Anzeige" 1 "Lehne_nicht_verriegelt" ;
VAL_ 1639 BFS_Klapptisch_offen 0 "inaktiv" 1 "aktiv" ;
VAL_ 1639 BFS_Gurtbringer_Sperre 0 "Gurtzubringer_freigegeben" 1 "Gurtzubringer_gesperrt" ;
VAL_ 1639 BFS_Sitzsym_Fahrt_aktiv 0 "inaktiv" 1 "aktiv" ;
VAL_ 1639 BFS_Sitzfahrt_aktiv 0 "Init" 1 "Sitz in Bewegung" ;
VAL_ 1639 BFS_SLV_aktiv 0 "nicht_aktiv" 1 "Sitzlaengsverstellung aktiv" ;
VAL_ 1639 BFS_SHV_aktiv 0 "nicht_aktiv" 1 "Sitzhoehenverstellung aktiv" ;
VAL_ 1639 BFS_LNV_aktiv 0 "inaktiv" 1 "aktiv" ;
VAL_ 1639 BFS_SNV_aktiv 0 "nicht_aktiv" 1 "Sitzneigungsverstellung aktiv" ;
VAL_ 1639 BFS_KSV_aktiv 0 "nicht_aktiv" 1 "Kopfstuetzenverstellung aktiv" ;
VAL_ 1639 BFS_LKV_aktiv 0 "nicht_aktiv" 1 "aktiv" ;
VAL_ 1639 BFS_STV_aktiv 0 "inaktiv" 1 "Sitztiefeverstellung aktiv" ;
VAL_ 1639 BFS_LHV_aktiv 0 "inaktiv" 1 "aktiv" ;
VAL_ 1639 BFS_LWV_aktiv 0 "nicht_aktiv" 1 "aktiv" ;
VAL_ 1639 BFS_GHV_aktiv 0 "nicht_aktiv" 1 "Gurthoehe Verstellung aktiv" ;
VAL_ 1639 BFS_KSS_Fahrt_aktiv 0 "nicht_aktiv" 1 "Komfortseitensichtfahrt aktiv" ;
VAL_ 1639 BFS_MMB_lokal_Stop 0 "kein_Abbruch" 1 "lokaler_Abbruch" ;
VAL_ 1639 BFS_Ruhestellung_Status 0 "inakiv" 1 "Ruhestellung_aktiv" ;
VAL_ 1639 BFS_Seat_Locked 0 "nicht_gesperrt" 1 "gesperrt" ;
VAL_ 1639 BFS_MMB_storage 0 "keine Zuweisung" 1 "P1/FP1 Pos Zuweisung" 2 "P2/FP2 Pos Zuweisung" 3 "P3/FP3 Pos Zuweisung" 4 "P4/FP4 Pos Zuweisung an den im System aktiven Funkschlüssel/FPI ID über MMI" 5 "FS1" 6 "FS2" 7 "FS3" 8 "FS4" ;
VAL_ 1639 BFS_MMB_tipp 0 "kein_Tippbetrieb" 1 "Tippbetrieb" ;
VAL_ 1639 BFS_MMB_tast 0 "kein_Tastbetrieb" 1 "Tastbetrieb" ;
VAL_ 1639 BFS_MMB_store_LED_on 0 "LED_aus" 1 "LED_ein" ;
VAL_ 1639 BFS_MMB_storage_beep 0 "beep_aus" 1 "beep ein" ;
VAL_ 1639 BFS_MMB_store 0 "nicht speichern" 1 "speichern" ;
VAL_ 1639 BFS_MMB_glob_stop 0 "kein globaler Abbruch" 1 "globaler Abbruch" ;
VAL_ 1639 BFS_FSV_ausgeklappt 0 "FSV_nicht_ausgeklappt" 1 "FSV_ausgeklappt" ;
VAL_ 1639 BFS_NFA_einfahren 0 "uneingeschraenkt" 1 "NFA_einfahren" ;
VAL_ 1639 BFS_Kollisionsbereich_Windschott 0 "Ausserhalb_Kollisionsbereich" 1 "Innerhalb_Kollisionsbereich" ;
VAL_ 1639 BFS_Kollisionsgefahr_Windschott 0 "keine_Kombimeldung_anzeigen" 1 "Kombimeldung_anzeigen" ;
VAL_ 1178 FS_Fond_Bed_enable 0 "disable" 1 "enable" ;
VAL_ 1178 FS_Lehne_nicht_verriegelt 0 "keine Anzeige" 1 "Lehne_nicht_verriegelt" ;
VAL_ 1178 FS_Spezialposition_anfahren 0 "Fkt_inaktiv" 1 "Fkt_aktiv" ;
VAL_ 1178 FS_Gurtbringer_Sperre 0 "Gurtzubringer_freigegeben" 1 "Gurtzubringer_gesperrt" ;
VAL_ 1178 FS_BFS_Sitzsym_Anfahrt 0 "keine Sitzsymetrie Anfahrt BFS" 1 "Sitzsymetrie Anfahrt BFS" ;
VAL_ 1178 FS_Sitzfahrt_aktiv 0 "Sitz_nicht_in_Bewegung" 1 "Sitz_in_Bewegung" ;
VAL_ 1178 FS_SLV_aktiv 0 "nicht_aktiv" 1 "Sitzlaengsverstellung aktiv" ;
VAL_ 1178 FS_SHV_aktiv 0 "nicht_aktiv" 1 "Sitzhoehenverstellung aktiv" ;
VAL_ 1178 FS_LNV_aktiv 0 "nicht_aktiv" 1 "Lehnenneigungverstellung aktiv" ;
VAL_ 1178 FS_SNV_aktiv 0 "nicht_aktiv" 1 "Sitzneigungsverstellung_aktiv" ;
VAL_ 1178 FS_KSV_aktiv 0 "nicht_aktiv" 1 "Kopfstuetzenverstellung aktiv" ;
VAL_ 1178 FS_LKV_aktiv 0 "nicht_aktiv" 1 "Lehnenkopfverstellung aktiv" ;
VAL_ 1178 FS_STV_aktiv 0 "nicht_aktiv" 1 "Sitztiefeverstellung aktiv" ;
VAL_ 1178 FS_LHV_aktiv 0 "nicht_aktiv" 1 "Lordose Höhe Verstellung aktiv" ;
VAL_ 1178 FS_LWV_aktiv 0 "nicht_aktiv" 1 "Lordose W Verstellung aktiv" ;
VAL_ 1178 FS_GHV_aktiv 0 "nicht_aktiv" 1 "Gurthoehenverstellung aktiv" ;
VAL_ 1178 FS_BFS_KSS_Anfahrt 0 "keine Anfahrt KSS BFS" 1 "Anfahrt KSS BFS" ;
VAL_ 1178 FS_MMB_lokal_Stop 0 "kein_Abbruch" 1 "lokaler_Abbruch" ;
VAL_ 1178 FS_NFA_einfahren 0 "uneingeschraenkt" 1 "NFA_einfahren" ;
VAL_ 1178 FS_Kollisionsbereich_Windschott 0 "Ausserhalb_Kollisionsbereich" 1 "Innerhalb_Kollisionsbereich" ;
VAL_ 1178 FS_MMB_storage 0 "keine_Zuweisung" 1 "P1_FP1_Pos_Zuweisung" 2 "P2_FP2_Pos_Zuweisung" 3 "P3_FP3_Pos_Zuweisung" 4 "P4_FP4_Pos_Zuweisung" 5 "FS1_bzw_Benutzerkonto_1" 6 "FS2_bzw_Benutzerkonto_2" 7 "FS3_bzw_Benutzerkonto_3" 8 "FS4_bzw_Benutzerkonto_4" 9 "FS5_bzw_Benutzerkonto_5" 10 "FS6_bzw_Benutzerkonto_6" 11 "FS7_bzw_Benutzerkonto_7" ;
VAL_ 1178 FS_MMB_tipp 0 "kein_Tippbetrieb" 1 "Tippbetrieb__automatisches_Funks" ;
VAL_ 1178 FS_MMB_tast 0 "kein_Tastbetrieb" 1 "Tastbetrieb__Fingerprintautomati" ;
VAL_ 1178 FS_MMB_store_LED_on 0 "LED_aus" 1 "LED_ein" ;
VAL_ 1178 FS_MMB_storage_beep 0 "beep aus" 1 "beep ein" ;
VAL_ 1178 FS_MMB_store 0 "nicht_speichern__kein_keyless_ve" 1 "abspeichern__keyless_verbaut" ;
VAL_ 1178 FS_MMB_glob_stop 0 "kein_globaler_Abbrucht" 1 "globaler_Abbruch" ;
VAL_ 1178 FS_EE_Fond_FS_enable 0 "EE Fond links deaktiv" 1 "EE Fond links aktiv (default) vom MMI" ;
VAL_ 1178 FS_EE_Fond_BFS_enable 0 "EE Fond rechts deaktiv" 1 "EE Fond rechts aktiv (default) vom MMI" ;
VAL_ 1178 FS_EE_BFS_enable 0 "keine_EE_Freigabe" 1 "EE_Freigabe" ;
VAL_ 1178 FS_Kollisionsgefahr_Windschott 0 "Keine_Kombimeldung_anzeigen" 1 "Kombimeldung_anzeigen" ;
VAL_ 1171 MF_ZV_Lock 0 "Locktaster_nicht_betaetigt" 1 "Locktaster_betaetigt" ;
VAL_ 1171 MF_Motorweiterlauf 0 "inaktiv" 1 "aktiv" ;
VAL_ 1171 MF_Heckrollo 0 "inaktiv" 1 "aktiv" ;
VAL_ 1171 MF_Anlassersperre 0 "inaktiv" 1 "aktiv" ;
VAL_ 1171 MF_Variante 0 "keine_Sonderfunktion" 1 "Sondersignalfahrzeug" 2 "Taxi" 3 "Fahrhilfe" 4 "Fahrschule_Extra" 5 "SSF" 6 "DBMC" 7 "Arbeitsmaschine" ;
VAL_ 1171 MF_Sperre_Rollo 0 "inaktiv" 1 "aktiv" ;
VAL_ 1171 MF_Laderelais 0 "Relais_offen" 1 "Relais_geschlossen" ;
VAL_ 1171 MF_StartStopp_Info 0 "Motorlauf_nicht_notwendig_(Stoppfreigabe)" 1 "Motoranlauf_nicht_zwingend_notwendig_(Stoppverbot,keine_Startanforderung)" 2 "Motoranlauf_zwingend_notwendig_(Startanforderung)" 3 "Systemfehler" ;
VAL_ 1171 MF_Fernbed_ein 0 "inaktiv" 1 "aktiv" ;
VAL_ 1171 MF_Standlicht 0 "inaktiv" 1 "aktiv" ;
VAL_ 1171 MF_Fahrlicht 0 "inaktiv" 1 "aktiv" ;
VAL_ 1171 MF_interm_Fernlicht 0 "inaktiv" 1 "aktiv" ;
VAL_ 1171 MF_Warnblinker 0 "inaktiv" 1 "aktiv" ;
VAL_ 1171 MF_Fussraumbel 0 "inaktiv" 1 "aktiv" ;
VAL_ 1171 MF_Innenraumbel 0 "inaktiv" 1 "aktiv" ;
VAL_ 1171 MF_Innenraumbel_Unterdrueck 0 "inaktiv" 1 "aktiv" ;
VAL_ 1171 MF_Notstart 0 "kein_Notstart" 1 "Notstart" ;
VAL_ 1171 MF_Blk_li 0 "inaktiv" 1 "aktiv" ;
VAL_ 1171 MF_Blk_re 0 "inaktiv" 1 "aktiv" ;
VAL_ 1171 MF_Lichthupe 0 "inaktiv" 1 "aktiv" ;
VAL_ 1171 MF_Fernlicht 0 "inaktiv" 1 "aktiv" ;
VAL_ 1171 MF_HFS_verriegeln 0 "nicht_verriegeln" 1 "verriegeln" ;
VAL_ 1171 MF_HFS_entriegeln 0 "nicht_entriegeln" 1 "entriegeln" ;
VAL_ 1171 MF_HBFS_verriegeln 0 "nicht_verriegeln" 1 "verriegeln" ;
VAL_ 1171 MF_HBFS_entriegeln 0 "nicht_entriegeln" 1 "entriegeln" ;
VAL_ 1171 MF_Tippwischen 0 "inaktiv" 1 "aktiv" ;
VAL_ 1171 MF_Frontintervall 0 "inaktiv" 1 "aktiv" ;
VAL_ 1171 MF_Wischerstufe_1 0 "inaktiv" 1 "aktiv" ;
VAL_ 1171 MF_Wischerstufe_2 0 "inaktiv" 1 "aktiv" ;
VAL_ 1171 MF_Frontwaschen 0 "inaktiv" 1 "aktiv" ;
VAL_ 1171 MF_nachtr_Stopp_Anf 0 "nicht_angefordert" 1 "angefordert" ;
VAL_ 1171 MF_Heckintervall 0 "inaktiv" 1 "aktiv" ;
VAL_ 1171 MF_Heckwaschen 0 "inaktiv" 1 "aktiv" ;
VAL_ 1171 MF_Summer 0 "inaktiv" 1 "aktiv" ;
VAL_ 1171 MF_Alarm_Blinkertakt 0 "inaktiv" 1 "aktiv" ;
VAL_ 1171 MF_Alarm_Blinker 0 "inaktiv" 1 "aktiv" ;
VAL_ 1171 MF_TFL_Abschaltung 0 "inaktiv" 1 "aktiv" ;
VAL_ 1171 MF_interm_Takt 0 "inaktiv" 1 "aktiv" ;
VAL_ 1171 MF_Tuerentriegelung_hinten 0 "inaktiv" 1 "aktiv" ;
VAL_ 1171 MF_interm_Fahrlicht 0 "inaktiv" 1 "aktiv" ;
VAL_ 1171 MF_Signalhorn 0 "inaktiv" 1 "aktiv" ;
VAL_ 1171 MF_FH_FT_hoch 0 "inaktiv" 1 "aktiv" ;
VAL_ 1171 MF_FH_FT_tief 0 "inaktiv" 1 "aktiv" ;
VAL_ 1171 MF_FH_BT_hoch 0 "inaktiv" 1 "aktiv" ;
VAL_ 1171 MF_FH_BT_tief 0 "inaktiv" 1 "aktiv" ;
VAL_ 1171 MF_FT_verriegeln 0 "nicht_verriegeln" 1 "verriegeln" ;
VAL_ 1171 MF_FT_entriegeln 0 "nicht_entriegeln" 1 "entriegeln" ;
VAL_ 1171 MF_BT_verriegeln 0 "nicht_verriegeln" 1 "verriegeln" ;
VAL_ 1171 MF_BT_entriegeln 0 "nicht_entriegeln" 1 "entriegeln" ;
VAL_ 817 MFL_Lokalaktiv 0 "war_nicht_lokal_aktiv" 1 "war_lokal_aktiv" ;
VAL_ 817 MFL_M_Taste 0 "nicht_betaetigt" 1 "betaetigt" ;
VAL_ 817 MFL_Paddle_Verbau 0 "verbaut" 1 "nicht_verbaut" ;
VAL_ 817 MFL_Tastencode_1 0 "Key_Released__No_Key" 1 "Context_Menu" 2 "Menu_Up__Next_Screen" 3 "Menu_Down__Previous_Screen" 4 "Up" 5 "Down" 6 "Up__Down_ThumbWheel" 7 "OK__ThumbWheel_Button" 8 "Cancel__Escape" 9 "Main_Menu" 10 "Side_Menu_left" 11 "Side_Menu_right" 12 "FAS_Menu" 13 "Left__Right_ThumbWheel" 14 "FAS_Menu_ThumbWheel" 16 "Volume_Up" 17 "Volume_Down" 18 "Volume_Up__Down_ThumbWheel" 19 "Volume_ThumbWheel_Button" 20 "Audio_Source" 21 "Arrow_A_Up__Right" 22 "Arrow_A_Down__Left" 23 "Arrow_B_Up__Right" 24 "Arrow_B_Down__Left" 25 "PTT__PushToTalk" 26 "PTT_Cancel" 27 "Route_Info" 28 "Hook" 29 "Hang_Up" 30 "Off_Hook" 31 "Light_On__Off" 32 "Mute" 33 "Joker1" 34 "Joker2" 35 "View" 36 "Arrow_A_Up__Down_ThumbWheel" 37 "Lenkradheizung" 38 "Rekuperation" 39 "Tube_Toggle" 40 "DRS_Drag_Reduction_System" 41 "Stopwatch_Start_Stop" 42 "Stopwatch_Nextlap" 100 "MAP" 101 "MAP_Boost" 102 "Turn_signal_left" 103 "Turn_signal_right" 104 "Turn_signal_off" 105 "Flashlight" 106 "Highbeam" 107 "Washer_button" 108 "Wiper_button_left" 109 "Wiper_button_right" 110 "Wiper_button_cancel" 111 "Exhaust_Sound" 112 "Drive_Select_button" 113 "Sport_button" 114 "ESP_Drift_Selection_ThumbWheel" 115 "PTT_special_vehicle" 116 "TravelAssist" 117 "Launch_Control" 118 "Drift_Mode_Button_Increase" 119 "Drift_Mode_Button_Decrease" 120 "Drift_Mode_Button_Select" 121 "Drive_Mode_Button_Increase" 122 "Drive_Mode_Button_Decrease" 123 "Drive_Mode_Button_Select" 124 "E_Boost_Button_Increase" 125 "E_Boost_Button_Decrease" 126 "E_Boost_Button_Select" 127 "PerformanceHybridButton_Increase" 128 "PerformanceHybridButton_Decrease" 129 "EV_Mode_Button" 130 "HUD_Button" 131 "PASM_Wheel" 132 "PASM_Button" 133 "PTV_Wheel" 134 "PTV_Button" 135 "TC_ESC_Wheel" 136 "TC_ESC_Button" 240 "Startup_Reset" 241 "Initialization" ;
VAL_ 817 MFL_Tastencode_2 0 "Key_Released__No_Key" 1 "Context_Menu" 2 "Menu_Up__Next_Screen" 3 "Menu_Down__Previous_Screen" 4 "Up" 5 "Down" 6 "Up__Down_ThumbWheel" 7 "OK__ThumbWheel_Button" 8 "Cancel__Escape" 9 "Main_Menu" 10 "Side_Menu_left" 11 "Side_Menu_right" 12 "FAS_Menu" 13 "Left__Right_ThumbWheel" 14 "FAS_Menu_ThumbWheel" 16 "Volume_Up" 17 "Volume_Down" 18 "Volume_Up__Down_ThumbWheel" 19 "Volume_ThumbWheel_Button" 20 "Audio_Source" 21 "Arrow_A_Up__Right" 22 "Arrow_A_Down__Left" 23 "Arrow_B_Up__Right" 24 "Arrow_B_Down__Left" 25 "PTT__PushToTalk" 26 "PTT_Cancel" 27 "Route_Info" 28 "Hook" 29 "Hang_Up" 30 "Off_Hook" 31 "Light_On__Off" 32 "Mute" 33 "Joker1" 34 "Joker2" 35 "View" 36 "Arrow_A_Up_Right_Down_Left_ThumbWheel" 37 "Lenkradheizung" 38 "Rekuperation" 39 "Tube_Toggle" 40 "DRS_Drag_Reduction_System" 41 "Stopwatch_Start_Stop" 42 "Stopwatch_Nextlap" 100 "MAP" 101 "MAP_Boost" 102 "Turn_signal_left" 103 "Turn_signal_right" 104 "Turn_signal_off" 105 "Flashlight" 106 "Highbeam" 107 "Washer_button" 108 "Wiper_button_left" 109 "Wiper_button_right" 110 "Wiper_button_cancel" 111 "Exhaust_Sound" 112 "Drive_Select_button" 113 "Sport_button" 114 "ESP_Drift_Selection_ThumbWheel" 115 "PTT_special_vehicle" 116 "TravelAssist" 117 "Launch_Control" 118 "Drift_Mode_Button_Increase" 119 "Drift_Mode_Button_Decrease" 120 "Drift_Mode_Button_Select" 121 "Drive_Mode_Button_Increase" 122 "Drive_Mode_Button_Decrease" 123 "Drive_Mode_Button_Select" 124 "E_Boost_Button_Increase" 125 "E_Boost_Button_Decrease" 126 "E_Boost_Button_Select" 127 "PerformanceHybridButton_Increase" 128 "PerformanceHybridButton_Decrease" 129 "EV_Mode_Button" 130 "HUD_Button" 131 "PASM_Wheel" 132 "PASM_Button" 133 "PTV_Wheel" 134 "PTV_Button" 135 "TC_ESC_Wheel" 136 "TC_ESC_Button" 240 "Startup_Reset" 241 "Initialization" ;
VAL_ 817 MFL_Eventcode_1 0 "W_no_event____T_no_event" 1 "W_1_Tick_up__T_pressed_normal" 2 "W_2_Ticks_up__T_touched" 3 "W_3_Ticks_up__T_double_click_nor" 4 "W_4_Ticks_up__T_long_press_nor_1" 5 "W_5_Ticks_up__T_long_press_nor_2" 6 "W_6_Ticks_up__T_long_press_nor_3" 7 "W_7_Ticks_up" 9 "W_7_Ticks_dn__T_pressed_strong" 10 "W_6_Ticks_dn" 11 "W_5_Ticks_dn__T_double_click_str" 12 "W_4_Ticks_dn__T_long_press_str_1" 13 "W_3_Ticks_dn__T_long_press_str_2" 14 "W_2_Ticks_dn__T_long_press_str_3" 15 "W_1_Tick_dn" ;
VAL_ 817 MFL_Eventcode_2 0 "W_no_event____T_no_event" 1 "W_1_Tick_up__T_pressed_normal" 2 "W_2_Ticks_up__T_touched" 3 "W_3_Ticks_up__T_double_click_nor" 4 "W_4_Ticks_up__T_long_press_nor_1" 5 "W_5_Ticks_up__T_long_press_nor_2" 6 "W_6_Ticks_up__T_long_press_nor_3" 7 "W_7_Ticks_up" 9 "W_7_Ticks_dn__T_pressed_strong" 10 "W_6_Ticks_dn" 11 "W_5_Ticks_dn__T_double_click_str" 12 "W_4_Ticks_dn__T_long_press_str_1" 13 "W_3_Ticks_dn__T_long_press_str_2" 14 "W_2_Ticks_dn__T_long_press_str_3" 15 "W_1_Tick_dn" ;
VAL_ 817 MFL_Marke 0 "VW" 1 "Audi" 2 "Seat" 3 "Skoda" 4 "VW_Nutzf" 5 "Bugatti" 6 "Lamborghini" 7 "Bentley" 8 "Rolls Royce" 9 "Quattro" 10 "kein_Hersteller_1" 11 "kein_Hersteller_2" 12 "kein_Hersteller_3" 13 "kein_Hersteller_4" 14 "Ford" 15 "Porsche" ;
VAL_ 817 MFL_Tip_Down 0 "nicht_betaetigt" 1 "betaetigt" ;
VAL_ 817 MFL_Tip_Up 0 "nicht_betaetigt" 1 "betaetigt" ;
VAL_ 817 MFL_SatModul_links_Err 0 "kein_Fehler" 1 "Fehler" ;
VAL_ 817 MFL_SatModul_rechts_Err 0 "kein_Fehler" 1 "Fehler" ;
VAL_ 817 MFL_LR_HZG_Status 0 "inaktiv" 1 "aktiv" ;
VAL_ 817 MFL_LR_HZG_Err 0 "normal" 1 "Fehler" ;
VAL_ 817 MFL_Signalhorn 0 "nicht_betaetigt" 1 "betaetigt" ;
VAL_ 817 MFL_Signalhorn_Err 0 "normal" 1 "Fehler" ;
VAL_ 817 MFL_Tip_links_Err 0 "normal" 1 "Fehler" ;
VAL_ 817 MFL_Tip_rechts_Err 0 "normal" 1 "Fehler" ;
VAL_ 817 MFL_Taste_links_Err 0 "normal" 1 "Fehler" ;
VAL_ 817 MFL_Taste_rechts_Err 0 "normal" 1 "Fehler" ;
VAL_ 817 MFL_ECU_Err 0 "normal" 1 "Fehler" ;
VAL_ 817 MFL_Response_Err 0 "normal" 1 "Fehler" ;
VAL_ 1600 MO_QBit_Ansaugluft_Temp 0 "gueltiger_Wert" 1 "Ersatz_Init_oder_Fehlerwert" ;
VAL_ 1600 MO_QBit_Oel_Temp 0 "gueltiger_Wert" 1 "Ersatz_Init_oder_Fehlerwert" ;
VAL_ 1600 MO_QBit_Kuehlmittel_Temp 0 "gueltiger_Wert" 1 "Ersatz_Init_oder_Fehlerwert" ;
VAL_ 1600 MO_KL15_Abschaltempfehlung 0 "Keine Empfehlung" 1 "Abschaltempfehlung" ;
VAL_ 1600 MO_HYB_Fehler_HV_Netz 0 "i_O" 1 "kein_generatorischer_Betrieb_moeglich" ;
VAL_ 1600 MO_aktives_Getriebeheizen 0 "kein_Ventil_ansteuern" 1 "Ventil_muss_angesteuert_werden" ;
VAL_ 1600 MO_Absperrventil_oeffnen 0 "nicht_verfuegbar" 1 "Ansteuerung_Ventil_zulaessig" 2 "Ventil_oeffnen_oder_geoeffnet" 3 "Ventil_schliessen_oder_geschlossen" ;
VAL_ 1600 MO_Ansaugluft_Temp 254 "Init" 255 "Fehler" ;
VAL_ 1600 MO_Oel_Temp 253 "nicht_verbaut" 254 "Init" 255 "Fehler" ;
VAL_ 1600 MO_Kuehlmittel_Temp 254 "Init" 255 "Fehler" ;
VAL_ 1600 MO_Hoeheninfo 255 "Fehler" ;
VAL_ 1600 MO_Kennfeldk 0 "keine Kennfeldkühlung vorhanden" 1 "Kennfeldkühlung vorhanden" ;
VAL_ 1600 MO_Versionsinfo_02 0 "zum_Projektbeginn_aufgeraeumter_CAN" 1 "Motor_03_mit_10ms" 16 "MQB_mit_neuer_Momentenschnittstelle" ;
VAL_ 1600 MO_QBit_Hoeheninfo 0 "gueltiger_Wert" 1 "Ersatz_Init_oder_Fehlerwert" ;
VAL_ 1600 MO_Getriebe_kuehlen 0 "nicht_kuehlen" 1 "kuehlen" ;
VAL_ 1600 MO_Heizungspumpenansteuerung 13 "Fehler" 14 "Init" 15 "nicht_verbaut" ;
VAL_ 1600 MO_SpannungsAnf 0 "keine_Anforderung" 1 "Anforderung" ;
VAL_ 1607 MO_ITM_Kuehlmittel_Temp 0 "nicht_verbaut" 1 "Init" 2 "Fehler" ;
VAL_ 1607 MO_E85_Sensor 13 "nicht_verbaut" 14 "Init" 15 "Fehler" ;
VAL_ 1607 SCR_Anz_Motorstarts 0 "Anzahl_moeglicher_Restarts" 1 "Anzahl_moeglicher_Restarts" 2 "Anzahl_moeglicher_Restarts" 3 "Anzahl_moeglicher_Restarts" 4 "Anzahl_moeglicher_Restarts" 5 "Anzahl_moeglicher_Restarts" 6 "Anzahl_moeglicher_Restarts" 7 "Anzahl_moeglicher_Restarts" 8 "Anzahl_moeglicher_Restarts" 9 "Anzahl_moeglicher_Restarts" 10 "Anzahl_moeglicher_Restarts" 11 "Anzahl_moeglicher_Restarts" 12 "Anzahl_moeglicher_Restarts" 13 "Anzahl_moeglicher_Restarts" 14 "Fahrbarkeitseinschraenkung" 15 "keine_Einschraenkung" ;
VAL_ 1607 SCR_Reichweite 32767 "keine_Anzeige" ;
VAL_ 1607 MO_Ethanol_Spuelhinweis 0 "Kein_Hinweis" 1 "Spuelhinweis_aktiv" ;
VAL_ 1607 SCR_Warnstufe_1 0 "nicht_aktiv" 1 "Warnstufe_1_aktiv" ;
VAL_ 1607 SCR_Warnstufe_2 0 "nicht_aktiv" 1 "Warnstufe_2_aktiv" ;
VAL_ 1607 SCR_Text 0 "kein_Text" 1 "Warntext_1" 2 "Warntext_2" 3 "Hinweis_Fuellstand" 4 "Reserve" 5 "SysFehler_1" 6 "SysFehler_2" 7 "Hinweis_Systemfehler" ;
VAL_ 1607 SCR_Akustik 0 "keine_Akustik" 1 "Akustik_1" 2 "Akustik_2" 3 "Akustik_bei_Hinweis" ;
VAL_ 1607 SCR_verbaut 0 "kein_SCR" 1 "SCR_verbaut" ;
VAL_ 1607 MO_Kraftstofffilter_Wasser 0 "keine_Anzeige" 1 "Abscheidevolumen_erschoepft" ;
VAL_ 1607 SCR_Systemfehler 0 "Warnung_nicht_aktiv" 1 "Warnung_aktiv" ;
VAL_ 1607 SCR_Inducement_Strategie 0 "Restart_Strategie" 1 "Reduced_Drivability_Strategie" ;
VAL_ 1607 MO_CO2_Faktor 0 "nicht_verbaut" 4095 "Fehler" ;
VAL_ 1607 MO_MKB_MUX 0 "MKB_01" 1 "MKB_02" 2 "MKB_03" 3 "MKB_04" ;
VAL_ 1607 MO_MKB_01 0 "Minus" 1 "A" 2 "B" 3 "C" 4 "D" 5 "E" 6 "F" 7 "G" 8 "H" 9 "I" 10 "J" 11 "K" 12 "L" 13 "M" 14 "N" 15 "O" 16 "P" 17 "Q" 18 "R" 19 "S" 20 "T" 21 "U" 22 "V" 23 "W" 24 "X" 25 "Y" 26 "Z" 27 "Leerzeichen" 28 "Leerzeichen" 29 "Leerzeichen" 30 "Leerzeichen" 31 "Unterstrich" ;
VAL_ 1607 MO_MKB_02 0 "Minus" 1 "A" 2 "B" 3 "C" 4 "D" 5 "E" 6 "F" 7 "G" 8 "H" 9 "I" 10 "J" 11 "K" 12 "L" 13 "M" 14 "N" 15 "O" 16 "P" 17 "Q" 18 "R" 19 "S" 20 "T" 21 "U" 22 "V" 23 "W" 24 "X" 25 "Y" 26 "Z" 27 "Leerzeichen" 28 "Leerzeichen" 29 "Leerzeichen" 30 "Leerzeichen" 31 "Unterstrich" ;
VAL_ 1607 MO_MKB_03 0 "Minus" 1 "A" 2 "B" 3 "C" 4 "D" 5 "E" 6 "F" 7 "G" 8 "H" 9 "I" 10 "J" 11 "K" 12 "L" 13 "M" 14 "N" 15 "O" 16 "P" 17 "Q" 18 "R" 19 "S" 20 "T" 21 "U" 22 "V" 23 "W" 24 "X" 25 "Y" 26 "Z" 27 "Leerzeichen" 28 "Leerzeichen" 29 "Leerzeichen" 30 "Leerzeichen" 31 "Unterstrich" ;
VAL_ 1607 MO_MKB_04 0 "Minus" 1 "A" 2 "B" 3 "C" 4 "D" 5 "E" 6 "F" 7 "G" 8 "H" 9 "I" 10 "J" 11 "K" 12 "L" 13 "M" 14 "N" 15 "O" 16 "P" 17 "Q" 18 "R" 19 "S" 20 "T" 21 "U" 22 "V" 23 "W" 24 "X" 25 "Y" 26 "Z" 27 "Leerzeichen" 28 "Leerzeichen" 29 "Leerzeichen" 30 "Leerzeichen" 31 "Unterstrich" ;
VAL_ 168 MO_Mom_neg_verfuegbar 510 "Init" 511 "Fehler" ;
VAL_ 168 MO_Mom_Begr_stat 510 "Init" ;
VAL_ 168 MO_Mom_Begr_dyn 1022 "Init" ;
VAL_ 168 MO_QBit_Drehzahl_01 0 "gueltiger_Wert" 1 "Ersatz_Init_oder_Fehlerwert" ;
VAL_ 958 MO_StartStopp_Status 0 "System_in_diesem_KL15_Zyklus_nicht_verfuegbar" 1 "System_aktiv_keine_Freigabe_durch_StartStop_Koordinator" 2 "System_aktiv_alle_Freigaben_liegen_vor" 3 "System_aktiv_mindestens_eine_Freigabe_fehlt" ;
VAL_ 958 MO_StartStopp_Wiederstart 0 "Wiederstart_inaktiv" 1 "Wiederstart_aktiv" ;
VAL_ 958 MO_StartStopp_Motorstopp 0 "Motor_Stop_inaktiv" 1 "Motor_Stop_aktiv" ;
VAL_ 958 MO_Freig_Reku 0 "Rekuperations-Modus aus" 1 "Empfehlung Spannungsanhebung" 2 "Empfehlung Spannungsabsenkung" 3 "Rekuperationsmodus aktiv, Spannungsvariation nicht notwendig" ;
VAL_ 958 MO_Kl_75 0 "Aus" 1 "Ein" ;
VAL_ 958 MO_Kl_50 0 "aus" 1 "KL50_ein_Startausfuehrung_Fahrer" ;
VAL_ 958 MO_Gangposition 0 "Gang_N" 1 "Gang_1" 2 "Gang_2" 3 "Gang_3" 4 "Gang_4" 5 "Gang_5" 6 "Gang_6" 7 "Gang_7" 8 "Gang_8" 9 "Automat_P" 10 "Automat_Vorwaerts_S" 11 "Automat_Vorwaerts_D/E" 12 "Zwischenstellung" 13 "Gang_R" 14 "Istgang_nicht_definiert" 15 "Fehler" ;
VAL_ 958 MO_StartStopp_Fahrerwunsch 0 "Init" 1 "Stoppverbot_durch_Fahrer" 2 "Stoppfreigabe_durch_Fahrer" 3 "Stoppanforderung_durch_Fahrer" ;
VAL_ 958 MO_HYB_Fahrbereitschaft 0 "keine_Fahrbereitschaft" 1 "Fahrbereitschaft" ;
VAL_ 958 MO_Ext_E_Fahrt_aktiv 0 "Rueckmeldung_E_Taster_aus" 1 "Rueckmeldung_E_Taster_ein" ;
VAL_ 958 MO_Fahrer_bremst 0 "kein_Bremsen" 1 "Bremse_betaetigt" ;
VAL_ 958 MO_QBit_Fahrer_bremst 0 "gueltiger_Wert" 1 "Ersatz_Init_oder_Fehlerwert" ;
VAL_ 958 MO_BLS 0 "kein_Bremsen" 1 "Bremse_betaetigt" ;
VAL_ 958 MO_Konsistenz_Bremsped 0 "Bremspedalinformation_plausibel" 1 "Bremspedalinformation_unplausibel" ;
VAL_ 958 MO_KomFehler_ESP 0 "kein_Fehler" 1 "Fehler" ;
VAL_ 958 MO_Klima_Eingr 0 "kein Eingriff" 1 "Klimakompressor ausschalten" 2 "Klimakompressor Leistungsreduzierung" 3 "Klimakompressor aufgrund der Heissleuchtenvorwarnung ausschalten" ;
VAL_ 958 MO_Aussp_Anlass 0 "Anlasser_darf_angesteuert_werden" 1 "Anlasser_ausspuren__Ansteuerung_nicht_moeglich" ;
VAL_ 958 MO_Freig_Anlass 0 "Start_nicht_zulaessig" 1 "Startfreigabe" ;
VAL_ 958 MO_Kuppl_schalter 0 "Schalter_sagt_ausgekuppelt" 1 "Schalter_sagt_eingekuppelt" ;
VAL_ 958 MO_Interlock 0 "Interlockschalter_nicht_betaetigt" 1 "Interlockschalter_betaetigt" ;
VAL_ 958 MO_Motor_laeuft 0 "Motor_laeuft_nicht" 1 "Motor_laeuft_autark_und_stabil_und_darf_mechanisch_belastet_werden" ;
VAL_ 958 MO_Kickdown 0 "kein_Kickdown" 1 "Kickdown" ;
VAL_ 958 MO_QBit_KL_75 0 "gueltiger_Wert" 1 "Ersatz_Init_oder_Fehlerwert" ;
VAL_ 958 MO_EKlKomLeiRed 0 "keine_Leistungsbegr" 1 "Leistungsbegr_75" 2 "Leistungsbegr_50" 3 "Leistungsbegr_25" ;
VAL_ 958 MO_Handshake_STH 0 "keine EKP-Ansteuerung durch STH-Anforderung" 1 "EKP-Ansteuerung durch STH-Anforderung" ;
VAL_ 958 MO_BKV_Unterdruckwarnung 0 "Unterdruckhaushalt_iO" 1 "Unterdruckhaushalt_niO" ;
VAL_ 958 MO_Freigabe_Segeln 0 "Segelbetrieb_nicht_freigegeben" 1 "Segelbetrieb_freigegeben" ;
VAL_ 958 MO_PTC_Status 0 "nicht_unterstuetzt" 1 "Stufe_0" 2 "Stufe_1" 3 "Stufe_2" 4 "Stufe_3" 7 "PTC_am_BCM" ;
VAL_ 958 MO_QBit_Gangposition 0 "gueltiger_Wert" 1 "Ersatz_Init_oder_Fehlerwert" ;
VAL_ 958 MO_Signalquelle_Gangposition 0 "Sensorsignal" 1 "Modellsignal" ;
VAL_ 958 MO_Remotestart_Betrieb 0 "MSG_nicht_bereit_fuer_RS_Betrieb" 1 "MSG_bereit_fuer_oder_im_RS_Betrieb" ;
VAL_ 958 MO_Remotestart_moeglich 0 "Remotestart_nicht_moeglich" 1 "Remotestart_moeglich" ;
VAL_ 958 MO_Text_Geschw_red 0 "keine_Anzeige" 1 "Anzeige_Geschwindigkeitsred" ;
VAL_ 958 MO_FMAus_aktiv 0 "inaktiv" 1 "Segeln_mit_Motor_aus_aktiv" ;
VAL_ 958 MO_FMAus_Startvariante 0 "kein_Motorstart" 1 "Motorstart_elektrischer_Starter" 2 "GetriebeAnschleppstart" 3 "GetriebeNotAnschleppstart" ;
VAL_ 958 MO_BMS_NV_Anf_stuetzen 0 "nicht_notwendig" 1 "notwendig" ;
VAL_ 958 MO_Zylinderabschaltung 0 "Vollmotorbetrieb_VMB" 1 "Uebergang_HMB_in_VMB" 2 "Uebergang_VMB_in_HMB" 3 "Halbmotorbetrieb_HMB" ;
VAL_ 958 MO_HYB_VM_aktiv 0 "VM_nicht_aktiv" 1 "VM_aktiv" ;
VAL_ 958 MO_StartVorauss_erfuellt 0 "Signal_nicht_bedient" 1 "StartVorauss_nicht_ueberpruefbar" 2 "StartVorauss_nicht_erfuellt" 3 "StartVorauss_erfuellt" ;
VAL_ 1631 TSK_QBit_Steigung 0 "gueltiger_Wert" 1 "Ersatz_Init_oder_Fehlerwert" ;
VAL_ 1631 TSK_QBit_Fahrzeugmasse 0 "gueltiger_Wert" 1 "Ersatz_Init_oder_Fehlerwert" ;
VAL_ 1631 MO_SpannungsAnf_02 0 "keine_Anforderung" 1 "Anforderung_Stufe_1" 2 "Anforderung_Stufe_2" 3 "Anforderung_Stufe_3" ;
VAL_ 1631 MO_DPF_reg 0 "DPF_regeneriert_nicht" 1 "DPF_regeneriert" ;
VAL_ 1631 MO_Heizstrom_EKAT 127 "Fehler" ;
VAL_ 1631 MO_Heizstrom_SCR 63 "Fehler" ;
VAL_ 1631 MO_Anzeige_Kaltleuchte 0 "Lampe_aus" 1 "Lampe_an" ;
VAL_ 1631 MO_P_Generator_ungefiltert_Anf 0 "nicht_angefordert" 1 "angefordert" ;
VAL_ 1631 TSK_Getriebeinfo 0 "Handschalter" 1 "AL_AQ_Getriebe" 2 "DL_DQ_Getriebe" 3 "CVT_Getriebe" ;
VAL_ 1631 MO_Energieinhalt_BMS 4094 "Init" 4095 "Fehler" ;
VAL_ 1631 TSK_Fahrzeugmasse_02 255 "Fehler" ;
VAL_ 1631 TSK_Steigung_02 0 "Init_oder_nicht_verbaut" 255 "Fehler" ;
VAL_ 812 MO_Sperrung_FahrPr_BZS 0 "keine Sperrung" 1 "Sperrung BZS1" 2 "Sperrung BZS2" 4 "Sperrung BZS3" 8 "Sperrung BZS4" 16 "Sperrung BZS5" 32 "Sperrung BZS6" 64 "Sperrung BZS7" 128 "Sperrung BZS8" ;
VAL_ 812 MO_Rampenzeit_Generator_Anf 0 "0_sec" 1 "1_sec" 2 "2_sec" 3 "3_sec" 4 "4_sec" 5 "5_sec" 6 "6_sec" 7 "7_sec" 8 "8_sec" 9 "9_sec" 10 "reserviert" 11 "reserviert" 12 "reserviert" 13 "reserviert" 14 "reserviert" 15 "keine_Anforderung" ;
VAL_ 812 MO_Prio_MAX_Wunschdrehzahl 0 "Wunsch" 1 "Zwang" ;
VAL_ 812 MO_Prio_MIN_Wunschdrehzahl 0 "Wunsch" 1 "Zwang" ;
VAL_ 812 MO_Luftpfad_aktiv 0 "kein Eingriff oder nur Eingriff über Zündpfad" 1 "Eingriff über Luftpfad" ;
VAL_ 812 MO_v_Begrenz_Aktivierbar 0 "V-Begrenzung nicht möglich" 1 "V-Begrenzung möglich" ;
VAL_ 812 MO_Charisma_FahrPr 0 "keine_Funktion" 1 "Programm_1" 2 "Programm_2" 3 "Programm_3" 4 "Programm_4" 5 "Programm_5" 6 "Programm_6" 7 "Programm_7" 8 "Programm_8" 9 "Programm_9" 10 "Programm_10" 11 "Programm_11" 12 "Programm_12" 13 "Programm_13" 14 "Programm_14" 15 "Programm_15" ;
VAL_ 812 MO_Charisma_Status 0 "Init" 1 "verfuegbar" 2 "nicht_verfuegbar" 3 "asynchron_durch_Fahrerwunsch" ;
VAL_ 812 MO_StSt_Charisma_FahrPr 0 "keine_Funktion" 1 "Programm_1" 2 "Programm_2" 3 "Programm_3" 4 "Programm_4" 5 "Programm_5" 6 "Programm_6" 7 "Programm_7" 8 "Programm_8" 9 "Programm_9" 10 "Programm_10" 11 "Programm_11" 12 "Programm_12" 13 "Programm_13" 14 "Programm_14" 15 "Programm_15" ;
VAL_ 812 MO_StSt_Charisma_Status 0 "Init" 1 "verfuegbar" 2 "nicht_verfuegbar" 3 "asynchron_durch_Fahrerwunsch" ;
VAL_ 812 MO_BZS_Charisma_FahrPr 0 "keine_Funktion" 1 "Programm_1" 2 "Programm_2" 3 "Programm_3" 4 "Programm_4" 5 "Programm_5" 6 "Programm_6" 7 "Programm_7" 8 "Programm_8" 9 "Programm_9" 10 "Programm_10" 11 "Programm_11" 12 "Programm_12" 13 "Programm_13" 14 "Programm_14" 15 "Programm_15" ;
VAL_ 812 MO_BZS_Charisma_Status 0 "Init" 1 "verfuegbar" 2 "nicht_verfuegbar" 3 "asynchron_durch_Fahrerwunsch" ;
VAL_ 812 MO_NGS_Position 0 "Neutralposition_nicht_erkannt" 1 "Neutralposition_erkannt" ;
VAL_ 812 MO_NGS_Status 0 "nicht_verbaut" 1 "nicht_plausibilisiert" 2 "plausibilisiert" 3 "Fehler" ;
VAL_ 812 MO_v_Begrenzung_Niveau 0 "keine_Begrenzung_aktiv" 1 "Sicherheitsbegrenzung_1_aktiv" 2 "Sicherheitsbegrenzung_2_aktiv" 3 "Komfortbegrenzung_aktiv" ;
